VERSION ""

NS_ :

BS_:

BU_: WPC2 RLPSU DPSU PSB SHVU_RR APSU FCS EMCU SLB RCM ARS CGW_CCU ATS RLHV SGU PFSU ALBCU DSAU SWRC SHVU_FR RCS RRPSU BLTN_CAM SCM DLBCU OHCL RWPC RRHV WPC HOD ASAU

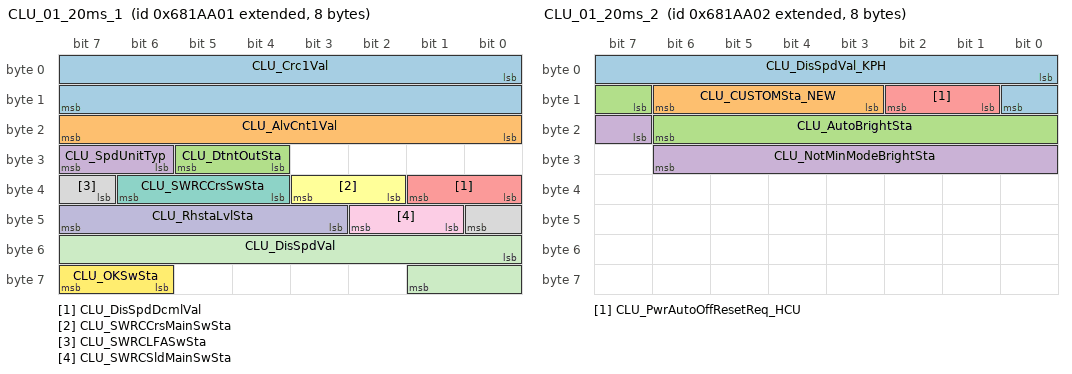
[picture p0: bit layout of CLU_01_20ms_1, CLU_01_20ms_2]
BO_ 2256644609 CLU_01_20ms_1: 8 CGW_CCU
 SG_ CLU_Crc1Val : 0|16@1+ (1,0) [0|0] ""  SHVU_RR,DPSU,ATS
 SG_ CLU_AlvCnt1Val : 16|8@1+ (1,0) [0|0] ""  SHVU_RR,DPSU,ATS,EMCU
 SG_ CLU_DtntOutSta : 28|2@1+ (1,0) [0|0] ""  FCS,WPC,RWPC,ARS,SWRC,APSU,RLHV,RRHV,SHVU_FR,SHVU_RR,DPSU,RCS,RRPSU,RLPSU,ATS,DSAU,ASAU,OHCL,WPC2
 SG_ CLU_SpdUnitTyp : 30|2@1+ (1,0) [0|0] ""  DPSU,BLTN_CAM,EMCU,WPC2
 SG_ CLU_DisSpdDcmlVal : 32|2@1+ (0.125,0) [0|0] ""  Vector__XXX
 SG_ CLU_SWRCCrsMainSwSta : 34|2@1+ (1,0) [0|0] ""  Vector__XXX
 SG_ CLU_SWRCCrsSwSta : 36|3@1+ (1,0) [0|0] ""  Vector__XXX
 SG_ CLU_SWRCLFASwSta : 39|2@1+ (1,0) [0|0] ""  Vector__XXX
 SG_ CLU_SWRCSldMainSwSta : 41|2@1+ (1,0) [0|0] ""  Vector__XXX
 SG_ CLU_RhstaLvlSta : 43|5@1+ (1,0) [0|0] ""  FCS,WPC,RWPC,ARS,SWRC,APSU,RLHV,RRHV,SHVU_FR,SHVU_RR,DPSU,RCS,RRPSU,RLPSU,ATS,DSAU,ASAU,OHCL,WPC2
 SG_ CLU_DisSpdVal : 48|10@1+ (0.5,0) [0|0] "km/h or MPH"  APSU,DPSU,BLTN_CAM,EMCU,WPC2
 SG_ CLU_OKSwSta : 62|2@1+ (1,0) [0|0] ""  Vector__XXX

BO_ 2470763009 CLU_09_00ms_1: 8 CGW_CCU
 SG_ CLU_Crc9Val : 0|16@1+ (1,0) [0|0] ""  Vector__XXX
 SG_ CLU_AlvCnt9Val : 16|8@1+ (1,0) [0|0] ""  Vector__XXX
 SG_ USM_MdLmpClrSetReq : 24|4@1+ (1,0) [0|0] ""  Vector__XXX
 SG_ USM_RrWiperRevSetReq : 28|2@1+ (1,0) [0|0] ""  Vector__XXX
 SG_ USM_RrStRemindSetReq : 30|2@1+ (1,0) [0|0] ""  Vector__XXX
 SG_ USM_RrWpcSetReq : 32|2@1+ (1,0) [0|0] ""  Vector__XXX
 SG_ USM_WpcSetReq : 34|2@1+ (1,0) [0|0] ""  WPC,WPC2
 SG_ USM_SeqLmpSetReq : 36|2@1+ (1,0) [0|0] ""  Vector__XXX
 SG_ USM_UnlckWlcmSetReq : 38|2@1+ (1,0) [0|0] ""  Vector__XXX
 SG_ USM_SmrtWlcmSetReq : 40|2@1+ (1,0) [0|0] ""  Vector__XXX
 SG_ USM_UipSetReq : 42|2@1+ (1,0) [0|0] ""  Vector__XXX
 SG_ USM_DigitalKeyEnblSetReq : 44|2@1+ (1,0) [0|0] ""  Vector__XXX
 SG_ USM_OwnerPhnRegSetReq : 46|2@1+ (1,0) [0|0] ""  Vector__XXX
 SG_ USM_NFCCard1RegSetReq : 48|2@1+ (1,0) [0|0] ""  Vector__XXX
 SG_ USM_NFCCard2RegSetReq : 50|2@1+ (1,0) [0|0] ""  Vector__XXX
 SG_ USM_ProcStpReq : 52|1@1+ (1,0) [0|0] ""  Vector__XXX
 SG_ USM_PwrAutoOffTimeSetReq : 54|3@1+ (1,0) [0|0] ""  Vector__XXX
 SG_ USM_RrStRemindSetReq_RestMode : 57|3@1+ (1,0) [0|0] ""  Vector__XXX
 SG_ USM_1stRrStRemindSetReq : 60|2@1+ (1,0) [0|0] ""  Vector__XXX
 SG_ USM_Wpc2SetReq : 62|2@1+ (1,0) [0|0] ""  WPC2

BO_ 2256644610 CLU_01_20ms_2: 8 CGW_CCU
 SG_ CLU_DisSpdVal_KPH : 0|9@1+ (1,0) [0|0] "km/h"  WPC,RWPC,APSU,RLHV,RRHV,SHVU_FR,SHVU_RR,DPSU,DLBCU,PFSU,RRPSU,RLPSU,ATS,DSAU,ASAU,RCM,ALBCU,WPC2
 SG_ CLU_CUSTOMSta_NEW : 11|4@1+ (1,0) [0|0] ""  SWRC
 SG_ CLU_AutoBrightSta : 15|8@1+ (1,0) [0|0] ""  FCS,WPC,RWPC,SWRC,APSU,RLHV,RRHV,SHVU_FR,SHVU_RR,DPSU,RCS,ATS,DSAU,ASAU,OHCL,BLTN_CAM,WPC2
 SG_ CLU_NotMinModeBrightSta : 23|8@1+ (1,0) [0|0] ""  Vector__XXX
 SG_ CLU_PwrAutoOffResetReq_HCU : 9|2@1+ (1,0) [0|0] ""  Vector__XXX

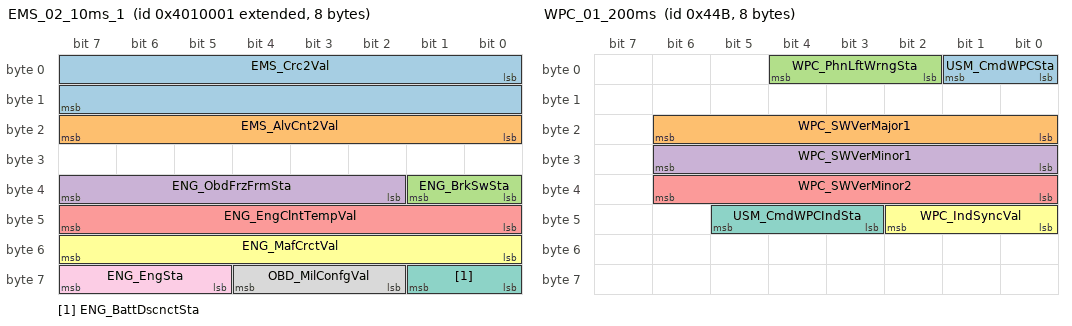
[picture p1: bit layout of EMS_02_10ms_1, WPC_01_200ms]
BO_ 2214658049 EMS_02_10ms_1: 8 CGW_CCU
 SG_ EMS_Crc2Val : 0|16@1+ (1,0) [0|0] ""  Vector__XXX
 SG_ EMS_AlvCnt2Val : 16|8@1+ (1,0) [0|0] ""  Vector__XXX
 SG_ ENG_BrkSwSta : 32|2@1+ (1,0) [0|0] ""  BLTN_CAM
 SG_ ENG_ObdFrzFrmSta : 34|6@1+ (1,0) [0|0] ""  Vector__XXX
 SG_ ENG_EngClntTempVal : 40|8@1+ (0.75,-48) [0|0] "℃"  Vector__XXX
 SG_ ENG_MafCrctVal : 48|8@1+ (0.00781,0) [0|0] ""  Vector__XXX
 SG_ ENG_BattDscnctSta : 56|2@1+ (1,0) [0|0] ""  Vector__XXX
 SG_ OBD_MilConfgVal : 58|3@1+ (1,0) [0|0] ""  Vector__XXX
 SG_ ENG_EngSta : 61|3@1+ (1,0) [0|0] ""  SCM,WPC,RWPC,SWRC,APSU,RLHV,RRHV,SHVU_FR,SHVU_RR,DPSU,DLBCU,PFSU,RRPSU,RLPSU,HOD,RCM,BLTN_CAM,EMCU,WPC2

BO_ 1099 WPC_01_200ms: 8 WPC
 SG_ USM_CmdWPCSta : 0|2@1+ (1,0) [0|0] ""  CGW_CCU
 SG_ WPC_SWVerMajor1 : 16|7@1+ (1,0) [0|0] ""  CGW_CCU
 SG_ WPC_PhnLftWrngSta : 2|3@1+ (1,0) [0|0] ""  CGW_CCU
 SG_ WPC_SWVerMinor1 : 24|7@1+ (1,0) [0|0] ""  CGW_CCU
 SG_ WPC_SWVerMinor2 : 32|7@1+ (1,0) [0|0] ""  CGW_CCU
 SG_ WPC_IndSyncVal : 40|3@1+ (1,0) [0|0] ""  RWPC,WPC2
 SG_ USM_CmdWPCIndSta : 43|3@1+ (1,0) [0|0] ""  CGW_CCU

BO_ 1093 SMK_06_200ms: 8 CGW_CCU
 SG_ SMK_Crc6Val : 0|8@1+ (1,0) [0|0] ""  Vector__XXX
 SG_ SMK_AlvCnt6Val : 12|4@1+ (1,0) [0|0] ""  Vector__XXX
 SG_ Lamp_HzrdBlnkngSta : 16|3@1+ (1,0) [0|0] ""  Vector__XXX
 SG_ RSPA_LearntSta : 19|2@1+ (1,0) [0|0] ""  Vector__XXX
 SG_ Lamp_SmrtWlcmLtOnReq : 21|2@1+ (1,0) [0|0] ""  Vector__XXX
 SG_ Fob_BattStaInfo : 24|2@1+ (1,0) [0|0] ""  Vector__XXX
 SG_ Fob_FoundDrvWlcmArea : 26|2@1+ (1,0) [0|0] ""  Vector__XXX
 SG_ Fob_FoundAsstWlcmArea : 28|2@1+ (1,0) [0|0] ""  Vector__XXX
 SG_ Fob_FoundExtrnlArea : 30|2@1+ (1,0) [0|0] ""  Vector__XXX
 SG_ Fob_FoundIntArea : 32|2@1+ (1,0) [0|0] ""  Vector__XXX
 SG_ Fob_LearntSta : 34|2@1+ (1,0) [0|0] ""  Vector__XXX
 SG_ RSPA_RFSigErrSta : 36|2@1+ (1,0) [0|0] ""  Vector__XXX
 SG_ RSPA_CanErrSta : 38|2@1+ (1,0) [0|0] ""  Vector__XXX
 SG_ LFAnt_FltSta : 40|2@1+ (1,0) [0|0] ""  Vector__XXX
 SG_ LFAnt_SrchSta : 42|2@1+ (1,0) [0|0] ""  WPC,RWPC,WPC2
 SG_ RSPA_ModSta_SMK : 48|3@1+ (1,0) [0|0] ""  DPSU
 SG_ RSPA_FobBattSta : 51|3@1+ (1,0) [0|0] ""  Vector__XXX
 SG_ Fob_BtnReleasedSta : 54|2@1+ (1,0) [0|0] ""  Vector__XXX
 SG_ USM_SmrtTrnkTlgtModSta : 56|3@1+ (1,0) [0|0] ""  Vector__XXX
 SG_ USM_WALModSta : 59|3@1+ (1,0) [0|0] ""  Vector__XXX
 SG_ Fob_FoundWlcmArea : 62|2@1+ (1,0) [0|0] ""  Vector__XXX

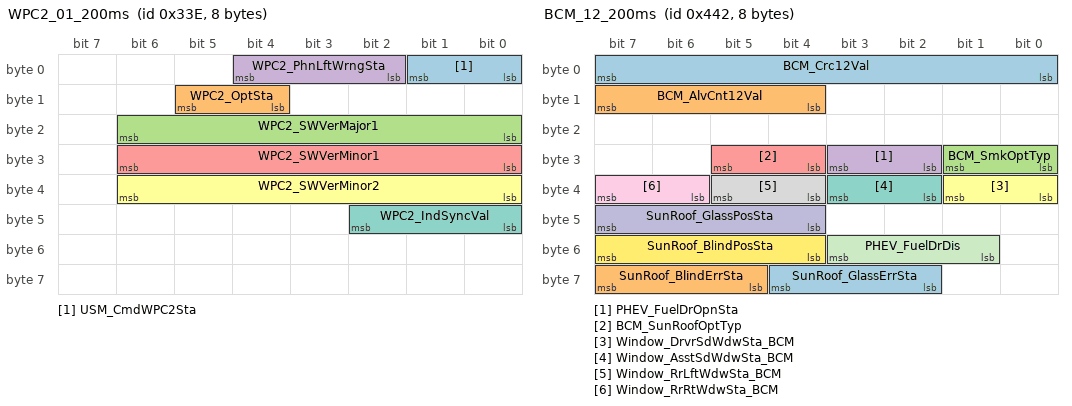
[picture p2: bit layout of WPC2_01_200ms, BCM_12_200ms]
BO_ 830 WPC2_01_200ms: 8 WPC2
 SG_ USM_CmdWPC2Sta : 0|2@1+ (1,0) [0|0] ""  CGW_CCU
 SG_ WPC2_OptSta : 12|2@1+ (1,0) [0|0] ""  CGW_CCU
 SG_ WPC2_SWVerMajor1 : 16|7@1+ (1,0) [0|0] ""  CGW_CCU
 SG_ WPC2_PhnLftWrngSta : 2|3@1+ (1,0) [0|0] ""  CGW_CCU
 SG_ WPC2_SWVerMinor1 : 24|7@1+ (1,0) [0|0] ""  CGW_CCU
 SG_ WPC2_SWVerMinor2 : 32|7@1+ (1,0) [0|0] ""  CGW_CCU
 SG_ WPC2_IndSyncVal : 40|3@1+ (1,0) [0|0] ""  RWPC,WPC

BO_ 2210462210 HCU_03_10ms_2: 8 CGW_CCU
 SG_ HCU_GreenZoneLmpDis : 0|2@1+ (1,0) [0|0] ""  Vector__XXX
 SG_ HCU_MILOnReq : 10|2@1+ (1,0) [0|0] ""  Vector__XXX
 SG_ HCU_PhevAutoModOnSta : 12|2@1+ (1,0) [0|0] "flag"  Vector__XXX
 SG_ HCU_SccDrvOvrdReq : 14|2@1+ (1,0) [0|0] ""  Vector__XXX
 SG_ HCU_SccEnblSta : 16|2@1+ (1,0) [0|0] ""  Vector__XXX
 SG_ HCU_SlwDnSta : 18|2@1+ (1,0) [0|0] ""  Vector__XXX
 SG_ HCU_HcuRdySta : 2|2@1+ (1,0) [0|0] ""  Vector__XXX
 SG_ HCU_SmrtEcoGdDis : 20|2@1+ (1,0) [0|0] ""  Vector__XXX
 SG_ HCU_SmrtEcoLvlDis : 22|7@1+ (1,0) [0|0] ""  Vector__XXX
 SG_ HCU_SmrtEcoRngDis : 29|7@1+ (1,0) [0|0] ""  Vector__XXX
 SG_ HCU_SpdLimDeviceActSta : 36|2@1+ (1,0) [0|0] ""  Vector__XXX
 SG_ HCU_SpdLimDeviceOperSta : 38|2@1+ (1,0) [0|0] ""  Vector__XXX
 SG_ HCU_HEVRdyDis : 4|2@1+ (1,0) [0|0] ""  Vector__XXX
 SG_ HCU_SpdLimDeviceVehSpdVal : 40|8@1+ (1,0) [0|0] ""  Vector__XXX
 SG_ HCU_SrvModSta : 48|2@1+ (1,0) [0|0] ""  Vector__XXX
 SG_ HCU_StrtInhbt2Sta : 50|2@1+ (1,0) [0|0] ""  Vector__XXX
 SG_ HCU_StrtInhbtSta : 52|2@1+ (1,0) [0|0] ""  Vector__XXX
 SG_ HCU_SysShtOffReq : 54|2@1+ (1,0) [0|0] ""  Vector__XXX
 SG_ HCU_VehStrtEnblSta : 56|2@1+ (1,0) [0|0] ""  Vector__XXX
 SG_ HCU_BrkLmpOnReq : 58|2@1+ (1,0) [0|0] ""  Vector__XXX
 SG_ HCU_HevRdySta : 6|2@1+ (1,0) [0|0] ""  SCM,WPC,RWPC,SWRC,APSU,RLHV,RRHV,SHVU_FR,SHVU_RR,DPSU,DLBCU,PFSU,RRPSU,RLPSU,HOD,RCM,BLTN_CAM,WPC2
 SG_ HCU_CcDrvAlrtDis : 60|2@1+ (1,0) [0|0] ""  Vector__XXX
 SG_ HCU_SldDrvAlrtDis : 62|2@1+ (1,0) [0|0] ""  Vector__XXX
 SG_ HCU_LimpOffSta : 8|2@1+ (1,0) [0|0] ""  Vector__XXX

BO_ 1090 BCM_12_200ms: 8 CGW_CCU
 SG_ BCM_Crc12Val : 0|8@1+ (1,0) [0|0] ""  Vector__XXX
 SG_ BCM_AlvCnt12Val : 12|4@1+ (1,0) [0|0] ""  Vector__XXX
 SG_ BCM_SmkOptTyp : 24|2@1+ (1,0) [0|0] ""  WPC,RWPC,WPC2
 SG_ PHEV_FuelDrOpnSta : 26|2@1+ (1,0) [0|0] ""  Vector__XXX
 SG_ BCM_SunRoofOptTyp : 28|2@1+ (1,0) [0|0] ""  ATS
 SG_ Window_DrvrSdWdwSta_BCM : 32|2@1+ (1,0) [0|0] ""  Vector__XXX
 SG_ Window_AsstSdWdwSta_BCM : 34|2@1+ (1,0) [0|0] ""  Vector__XXX
 SG_ Window_RrLftWdwSta_BCM : 36|2@1+ (1,0) [0|0] ""  ATS
 SG_ Window_RrRtWdwSta_BCM : 38|2@1+ (1,0) [0|0] ""  ATS
 SG_ SunRoof_GlassPosSta : 44|4@1+ (1,0) [0|0] ""  Vector__XXX
 SG_ PHEV_FuelDrDis : 49|3@1+ (1,0) [0|0] ""  Vector__XXX
 SG_ SunRoof_BlindPosSta : 52|4@1+ (1,0) [0|0] ""  Vector__XXX
 SG_ SunRoof_GlassErrSta : 58|3@1+ (1,0) [0|0] ""  Vector__XXX
 SG_ SunRoof_BlindErrSta : 61|3@1+ (1,0) [0|0] ""  Vector__XXX

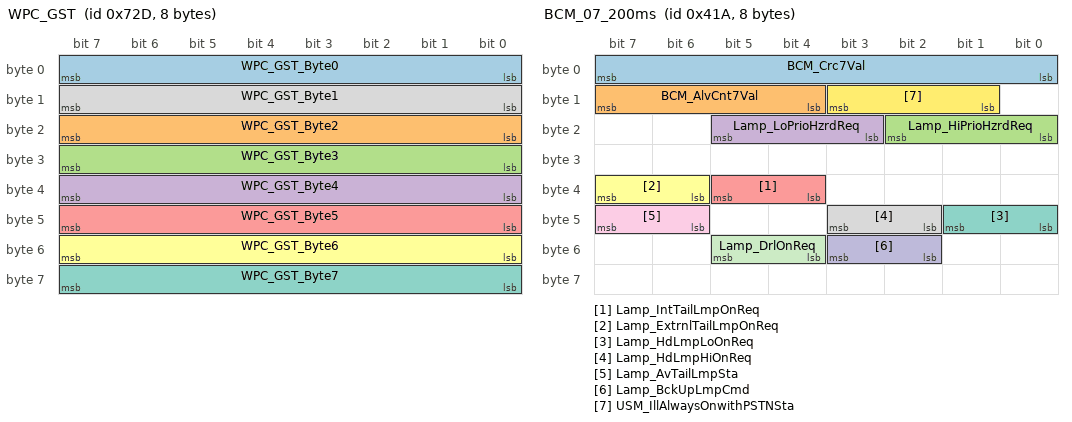
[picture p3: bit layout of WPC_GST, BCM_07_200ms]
BO_ 1837 WPC_GST: 8 WPC
 SG_ WPC_GST_Byte0 : 0|8@1+ (1,0) [0|0] ""  CGW_CCU
 SG_ WPC_GST_Byte2 : 16|8@1+ (1,0) [0|0] ""  CGW_CCU
 SG_ WPC_GST_Byte3 : 24|8@1+ (1,0) [0|0] ""  CGW_CCU
 SG_ WPC_GST_Byte4 : 32|8@1+ (1,0) [0|0] ""  CGW_CCU
 SG_ WPC_GST_Byte5 : 40|8@1+ (1,0) [0|0] ""  CGW_CCU
 SG_ WPC_GST_Byte6 : 48|8@1+ (1,0) [0|0] ""  CGW_CCU
 SG_ WPC_GST_Byte7 : 56|8@1+ (1,0) [0|0] ""  CGW_CCU
 SG_ WPC_GST_Byte1 : 8|8@1+ (1,0) [0|0] ""  CGW_CCU

BO_ 1050 BCM_07_200ms: 8 CGW_CCU
 SG_ BCM_Crc7Val : 0|8@1+ (1,0) [0|0] ""  Vector__XXX
 SG_ BCM_AlvCnt7Val : 12|4@1+ (1,0) [0|0] ""  Vector__XXX
 SG_ Lamp_HiPrioHzrdReq : 16|3@1+ (1,0) [0|0] ""  Vector__XXX
 SG_ Lamp_LoPrioHzrdReq : 19|3@1+ (1,0) [0|0] ""  Vector__XXX
 SG_ Lamp_IntTailLmpOnReq : 36|2@1+ (1,0) [0|0] ""  FCS,WPC,RWPC,APSU,RLHV,RRHV,SHVU_FR,SHVU_RR,DPSU,WPC2
 SG_ Lamp_ExtrnlTailLmpOnReq : 38|2@1+ (1,0) [0|0] ""  BLTN_CAM
 SG_ Lamp_HdLmpLoOnReq : 40|2@1+ (1,0) [0|0] ""  Vector__XXX
 SG_ Lamp_HdLmpHiOnReq : 42|2@1+ (1,0) [0|0] ""  Vector__XXX
 SG_ Lamp_AvTailLmpSta : 46|2@1+ (1,0) [0|0] ""  SWRC,APSU,ATS
 SG_ Lamp_BckUpLmpCmd : 50|2@1+ (1,0) [0|0] ""  Vector__XXX
 SG_ Lamp_DrlOnReq : 52|2@1+ (1,0) [0|0] ""  Vector__XXX
 SG_ USM_IllAlwaysOnwithPSTNSta : 9|3@1+ (1,0) [0|0] ""  Vector__XXX

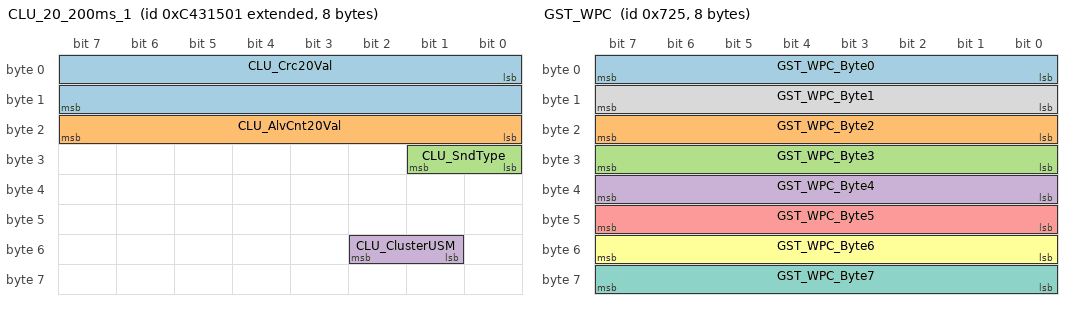
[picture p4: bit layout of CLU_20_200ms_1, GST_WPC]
BO_ 2353206529 CLU_20_200ms_1: 8 CGW_CCU
 SG_ CLU_Crc20Val : 0|16@1+ (1,0) [0|0] ""  Vector__XXX
 SG_ CLU_AlvCnt20Val : 16|8@1+ (1,0) [0|0] ""  Vector__XXX
 SG_ CLU_SndType : 24|2@1- (1,0) [0|0] ""  Vector__XXX
 SG_ CLU_ClusterUSM : 49|2@1+ (1,0) [0|0] ""  WPC,WPC2

BO_ 1041 ICU_02_200ms: 8 CGW_CCU
 SG_ ICU_Crc2Val : 0|8@1+ (1,0) [0|0] ""  Vector__XXX
 SG_ ICU_MtGearPosRSta : 10|2@1+ (1,0) [0|0] ""  BLTN_CAM
 SG_ ICU_AlvCnt2Val : 12|4@1+ (1,0) [0|0] ""  Vector__XXX
 SG_ Autocut_DlvryModSta : 20|2@1+ (1,0) [0|0] ""  Vector__XXX
 SG_ DoorLock_AsstDrUnLkSta : 22|2@1+ (1,0) [0|0] ""  Vector__XXX
 SG_ Warn_DrvDrSwSta : 24|2@1+ (1,0) [0|0] ""  WPC,RWPC,DPSU,BLTN_CAM,WPC2
 SG_ DoorLock_DrvKeyUnLkSwSta : 26|2@1+ (1,0) [0|0] ""  Vector__XXX
 SG_ DoorLock_RrLftDrUnLkSta : 28|2@1+ (1,0) [0|0] ""  Vector__XXX
 SG_ DoorLock_RrRtDrUnLkSta : 30|2@1+ (1,0) [0|0] ""  Vector__XXX
 SG_ Warn_AsstDrSwSta : 34|2@1+ (1,0) [0|0] ""  WPC,RWPC,APSU,RLPSU,BLTN_CAM,ALBCU,WPC2
 SG_ Warn_AsstStBltSwSta : 36|2@1+ (1,0) [0|0] ""  PSB,APSU,RLPSU,ASAU,ALBCU
 SG_ Warn_BrkFldSwSta : 38|2@1+ (1,0) [0|0] ""  Vector__XXX
 SG_ DoorLock_DrvKeyLkSwSta : 40|2@1+ (1,0) [0|0] ""  Vector__XXX
 SG_ Warn_DrvStBltSwSta : 42|2@1+ (1,0) [0|0] ""  PSB,DPSU,DLBCU,ATS,DSAU,ASAU
 SG_ Warn_HoodSwSta : 44|2@1+ (1,0) [0|0] ""  BLTN_CAM
 SG_ Warn_PassStOccSta : 46|2@1+ (1,0) [0|0] ""  APSU
 SG_ Warn_PrkngBrkSwSta : 48|2@1+ (1,0) [0|0] ""  APSU,RLHV,RRHV,PFSU,RRPSU,RLPSU
 SG_ Warn_RrCtrStBltSwSta : 50|2@1+ (1,0) [0|0] ""  PSB
 SG_ Warn_RrLftDrSwSta : 52|2@1+ (1,0) [0|0] ""  WPC,RWPC,APSU,RLHV,RRPSU,RLPSU,BLTN_CAM,WPC2
 SG_ Warn_RrLftStBltSwSta : 54|2@1+ (1,0) [0|0] ""  PSB,APSU,DPSU
 SG_ Warn_RrRtDrSwSta : 56|2@1+ (1,0) [0|0] ""  WPC,RWPC,APSU,RRHV,RRPSU,RLPSU,BLTN_CAM,WPC2
 SG_ Warn_RrRtStBltSwSta : 58|2@1+ (1,0) [0|0] ""  PSB,APSU,DPSU
 SG_ Warn_HoodSwMemorySta : 60|2@1+ (1,0) [0|0] ""  Vector__XXX
 SG_ Warn_WshrFldSwSta : 62|2@1+ (1,0) [0|0] ""  Vector__XXX
 SG_ ICU_Haptic_OPT : 8|2@1+ (1,0) [0|0] ""  Vector__XXX

BO_ 1829 GST_WPC: 8 CGW_CCU
 SG_ GST_WPC_Byte0 : 0|8@1+ (1,0) [0|0] ""  WPC
 SG_ GST_WPC_Byte2 : 16|8@1+ (1,0) [0|0] ""  WPC
 SG_ GST_WPC_Byte3 : 24|8@1+ (1,0) [0|0] ""  WPC
 SG_ GST_WPC_Byte4 : 32|8@1+ (1,0) [0|0] ""  WPC
 SG_ GST_WPC_Byte5 : 40|8@1+ (1,0) [0|0] ""  WPC
 SG_ GST_WPC_Byte6 : 48|8@1+ (1,0) [0|0] ""  WPC
 SG_ GST_WPC_Byte7 : 56|8@1+ (1,0) [0|0] ""  WPC
 SG_ GST_WPC_Byte1 : 8|8@1+ (1,0) [0|0] ""  WPC

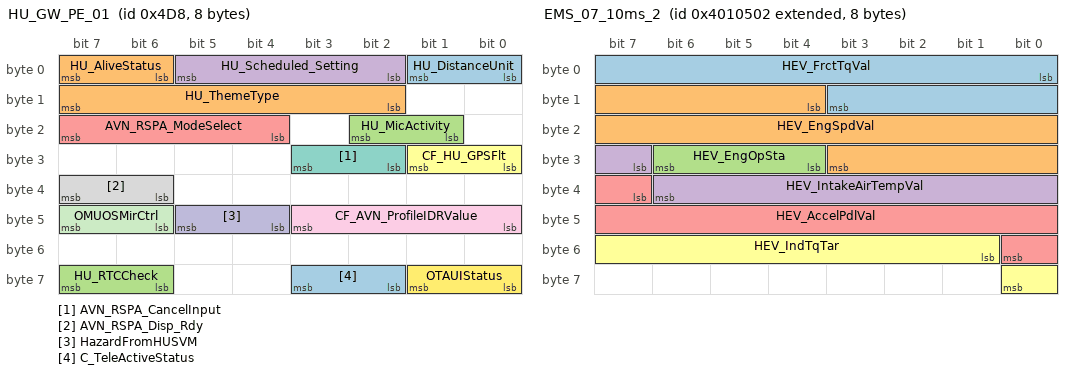
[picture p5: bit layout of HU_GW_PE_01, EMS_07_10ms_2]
BO_ 1240 HU_GW_PE_01: 8 CGW_CCU
 SG_ HU_DistanceUnit : 0|2@1+ (1,0) [0|0] ""  Vector__XXX
 SG_ HU_ThemeType : 10|6@1+ (1,0) [0|0] ""  ATS,BLTN_CAM
 SG_ HU_MicActivity : 17|2@1+ (1,0) [0|0] ""  Vector__XXX
 SG_ HU_Scheduled_Setting : 2|4@1+ (1,0) [0|0] ""  Vector__XXX
 SG_ AVN_RSPA_ModeSelect : 20|4@1+ (1,0) [0|0] ""  Vector__XXX
 SG_ CF_HU_GPSFlt : 24|2@1+ (1,0) [0|0] ""  Vector__XXX
 SG_ AVN_RSPA_CancelInput : 26|2@1+ (1,0) [0|3] ""  Vector__XXX
 SG_ AVN_RSPA_Disp_Rdy : 38|2@1+ (1,0) [0|0] ""  Vector__XXX
 SG_ CF_AVN_ProfileIDRValue : 40|4@1+ (1,0) [0|0] ""  WPC,RWPC,DPSU,DLBCU,RCM,BLTN_CAM,SGU,WPC2
 SG_ HazardFromHUSVM : 44|2@1+ (1,0) [0|0] ""  Vector__XXX
 SG_ OMUOSMirCtrl : 46|2@1+ (1,0) [0|0] ""  Vector__XXX
 SG_ OTAUIStatus : 56|2@1+ (1,0) [0|0] ""  Vector__XXX
 SG_ C_TeleActiveStatus : 58|2@1+ (1,0) [0|0] ""  Vector__XXX
 SG_ HU_AliveStatus : 6|2@1+ (1,0) [0|0] ""  Vector__XXX
 SG_ HU_RTCCheck : 62|2@1+ (1,0) [0|0] ""  APSU

BO_ 2214659330 EMS_07_10ms_2: 8 CGW_CCU
 SG_ HEV_FrctTqVal : 0|12@1+ (0.1,0) [0|0] "Nm"  Vector__XXX
 SG_ HEV_EngSpdVal : 12|16@1+ (0.25,0) [0|0] "rpm"  Vector__XXX
 SG_ HEV_EngOpSta : 28|3@1+ (1,0) [0|0] ""  WPC,RWPC,PFSU,WPC2
 SG_ HEV_IntakeAirTempVal : 31|8@1+ (0.75,-48) [0|0] "℃"  Vector__XXX
 SG_ HEV_AccelPdlVal : 39|10@1+ (0.09784,0) [0|0] "%"  BLTN_CAM
 SG_ HEV_IndTqTar : 49|8@1+ (0.3906,0) [0|0] "%"  Vector__XXX

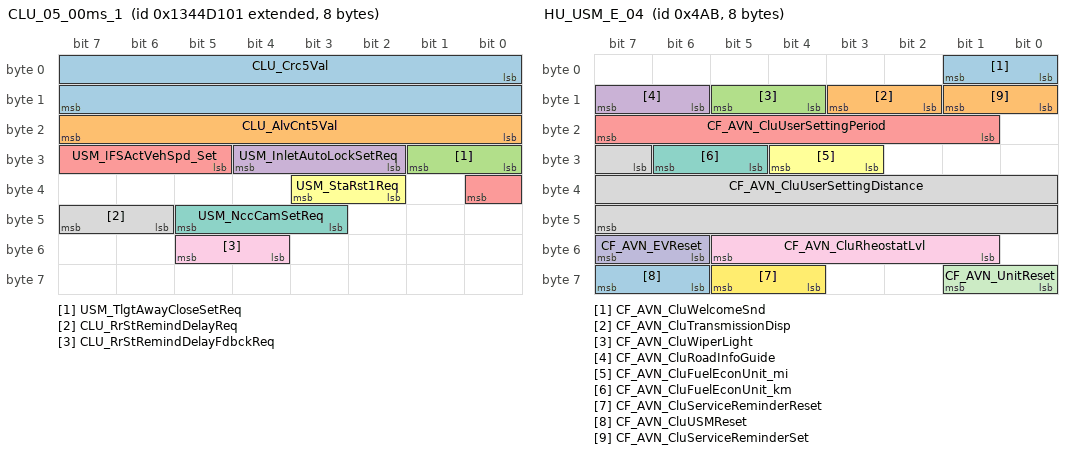
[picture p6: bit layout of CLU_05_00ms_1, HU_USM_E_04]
BO_ 2470760705 CLU_05_00ms_1: 8 CGW_CCU
 SG_ CLU_Crc5Val : 0|16@1+ (1,0) [0|0] ""  Vector__XXX
 SG_ CLU_AlvCnt5Val : 16|8@1+ (1,0) [0|0] ""  Vector__XXX
 SG_ USM_TlgtAwayCloseSetReq : 24|2@1+ (1,0) [0|0] ""  Vector__XXX
 SG_ USM_InletAutoLockSetReq : 26|3@1+ (1,0) [0|0] ""  Vector__XXX
 SG_ USM_IFSActVehSpd_Set : 29|4@1+ (1,0) [0|0] ""  Vector__XXX
 SG_ USM_StaRst1Req : 34|2@1+ (1,0) [0|0] ""  WPC,DPSU,WPC2
 SG_ USM_NccCamSetReq : 43|3@1+ (1,0) [0|0] ""  Vector__XXX
 SG_ CLU_RrStRemindDelayReq : 46|2@1+ (1,0) [0|0] ""  Vector__XXX
 SG_ CLU_RrStRemindDelayFdbckReq : 52|2@1+ (1,0) [0|0] ""  Vector__XXX

BO_ 1195 HU_USM_E_04: 8 CGW_CCU
 SG_ CF_AVN_CluWelcomeSnd : 0|2@1+ (1,0) [0|0] ""  Vector__XXX
 SG_ CF_AVN_CluTransmissionDisp : 10|2@1+ (1,0) [0|0] ""  Vector__XXX
 SG_ CF_AVN_CluWiperLight : 12|2@1+ (1,0) [0|0] ""  Vector__XXX
 SG_ CF_AVN_CluRoadInfoGuide : 14|2@1+ (1,0) [0|0] ""  Vector__XXX
 SG_ CF_AVN_CluUserSettingPeriod : 17|7@1+ (1,0) [0|0] ""  Vector__XXX
 SG_ CF_AVN_CluFuelEconUnit_mi : 27|2@1+ (1,0) [0|0] ""  Vector__XXX
 SG_ CF_AVN_CluFuelEconUnit_km : 29|2@1+ (1,0) [0|0] ""  Vector__XXX
 SG_ CF_AVN_CluUserSettingDistance : 31|17@1+ (1,0) [0|0] ""  Vector__XXX
 SG_ CF_AVN_CluRheostatLvl : 49|5@1+ (1,0) [0|0] ""  Vector__XXX
 SG_ CF_AVN_EVReset : 54|2@1+ (1,0) [0|0] ""  Vector__XXX
 SG_ CF_AVN_UnitReset : 56|2@1+ (1,0) [0|0] ""  Vector__XXX
 SG_ CF_AVN_CluServiceReminderReset : 60|2@1+ (1,0) [0|0] ""  Vector__XXX
 SG_ CF_AVN_CluUSMReset : 62|2@1+ (1,0) [0|0] ""  WPC,RWPC,SLB,ARS,APSU,RLHV,RRHV,SHVU_FR,SHVU_RR,DPSU,DLBCU,PFSU,RRPSU,RLPSU,ATS,DSAU,ASAU,RCM,BLTN_CAM,SGU,ALBCU,WPC2
 SG_ CF_AVN_CluServiceReminderSet : 8|2@1+ (1,0) [0|0] ""  Vector__XXX

CM_ BO_ 1050 "[PE] Periodic and On Event";
CM_ SG_ 1050 BCM_Crc7Val "BCM_CyclicRedundancyCheck7Value";
CM_ SG_ 1050 BCM_AlvCnt7Val "BCM_AliveCounter7Value";
CM_ SG_ 1050 Lamp_HiPrioHzrdReq "Lamp_HighPriorityHazardRequest ##2G##BCM - BCMmsg19 - C_HazardFromBCMHigh";
CM_ SG_ 1050 Lamp_LoPrioHzrdReq "Lamp_LowPriorityHazardStatus ##2G##BCM - BCMmsg19 - C_HazardfromBCMLow";
CM_ SG_ 1050 Lamp_IntTailLmpOnReq "Lamp_InternalTailLampOnRequest ##2G##BCM - BCMmsg19 - C_IntTailOn";
CM_ SG_ 1050 Lamp_ExtrnlTailLmpOnReq "Lamp_ExternalTailLampOnRequest ##2G##BCM - BCMmsg19 - C_ExtTailOn";
CM_ SG_ 1050 Lamp_HdLmpLoOnReq "Lamp_HeadLampLowOnRequest ##2G##BCM - BCMmsg19 - C_HLpLowOn";
CM_ SG_ 1050 Lamp_HdLmpHiOnReq "Lamp_HeadLampHighOnRequest ##2G##BCM - BCMmsg19 - C_HLpHighOn";
CM_ SG_ 1050 Lamp_AvTailLmpSta "Lamp_AvTailLampStatus ##2G##BCM - BCMmsg18 - C_AvTail";
CM_ BO_ 1090 "[PE] Periodic and On Event";
CM_ SG_ 1090 BCM_Crc12Val "BCM_CyclicRedundancyCheck12Value";
CM_ SG_ 1090 BCM_AlvCnt12Val "BCM_AliveCounter12Value";
CM_ SG_ 1090 BCM_SmkOptTyp "BCM_SmkOptionType ##2G##BCM - BCMmsg17 - C_SMKOption";
CM_ SG_ 1090 PHEV_FuelDrOpnSta "PHEV_FuelDoorOpenStatus ##2G##BCM - BCMmsg20 - C_FuelDrSw";
CM_ SG_ 1090 BCM_SunRoofOptTyp "BCM_SunRoofOptionType";
CM_ SG_ 1090 Window_DrvrSdWdwSta_BCM "Window_DriverSideWindowStatus ##2G##BCM - BCMmsg22 - C_DrvWindowOpenState";
CM_ SG_ 1090 Window_AsstSdWdwSta_BCM "Window_AssistantSideWindowStatus ##2G##BCM - BCMmsg22 - C_AstWindowOpenState";
CM_ SG_ 1090 Window_RrLftWdwSta_BCM "Window_RearLeftWindowStatus ##2G##BCM - BCMmsg22 - C_RLWindowOpenState";
CM_ SG_ 1090 Window_RrRtWdwSta_BCM "Window_RearRightPowerWindowStatus ##2G##BCM - BCMmsg22 - C_RRWindowOpenState";
CM_ SG_ 1090 SunRoof_GlassPosSta "SunRoof_GlassPositionStatus";
CM_ SG_ 1090 PHEV_FuelDrDis "PHEV_FuelDoorDisplay ##2G##BCM - BCMmsg19 - C_PHEVFuelDrDisp";
CM_ SG_ 1090 SunRoof_BlindPosSta "SunRoof_BlindPositionStatus";
CM_ SG_ 1090 SunRoof_GlassErrSta "SunRoof_GlassErrorStatus";
CM_ SG_ 1090 SunRoof_BlindErrSta "SunRoof_BlindErrorStatus";
CM_ BO_ 2256644609 "[P] Periodic";
CM_ SG_ 2256644609 CLU_Crc1Val "CLU_CyclicRedundancyCheck1Value";
CM_ SG_ 2256644609 CLU_AlvCnt1Val "CLU_AliveCounter1Value";
CM_ SG_ 2256644609 CLU_DtntOutSta "CLU_DetentOutStatus";
CM_ SG_ 2256644609 CLU_SpdUnitTyp "CLU_SpeedUnitType";
CM_ SG_ 2256644609 CLU_DisSpdDcmlVal "CLU_DisplaySpeedDecimalValue";
CM_ SG_ 2256644609 CLU_SWRCCrsMainSwSta "CLU_SWRCCrsMainSwSta";
CM_ SG_ 2256644609 CLU_SWRCCrsSwSta "CLU_SWRCCrsSwSta";
CM_ SG_ 2256644609 CLU_SWRCLFASwSta "SWRC_LFASwitchStatus";
CM_ SG_ 2256644609 CLU_SWRCSldMainSwSta "SWRC_SpeedLimiterMainSwitchStatus";
CM_ SG_ 2256644609 CLU_RhstaLvlSta "CLU_RheostatLevelStatus";
CM_ SG_ 2256644609 CLU_DisSpdVal "CLU_DisplaySpeedValue";
CM_ SG_ 2256644609 CLU_OKSwSta "OK Switch On/Off State";
CM_ BO_ 2256644610 "[P] Periodic";
CM_ SG_ 2256644610 CLU_DisSpdVal_KPH "CLU_DisplaySpeedValue_KPH";
CM_ SG_ 2256644610 CLU_AutoBrightSta "CLU_AutoBrightStatus";
CM_ SG_ 2256644610 CLU_NotMinModeBrightSta "CLU_NotMinimumModeBrightStaus";
CM_ SG_ 2256644610 CLU_PwrAutoOffResetReq_HCU "reset power auto off time";
CM_ BO_ 2470760705 "[EC] On Event and On Change";
CM_ SG_ 2470760705 CLU_Crc5Val "CLU_CyclicRedundancyCheck5Value";
CM_ SG_ 2470760705 CLU_AlvCnt5Val "CLU_AliveCounter5Value";
CM_ SG_ 2470760705 USM_TlgtAwayCloseSetReq "USM for Tailgate Away Close system";
CM_ SG_ 2470760705 USM_InletAutoLockSetReq "2nd General Signal: CLU22/CF_Clu_InletAutoLockNValueSet";
CM_ SG_ 2470760705 USM_IFSActVehSpd_Set "IFS 진입 속도 설정 메뉴";
CM_ SG_ 2470760705 USM_StaRst1Req "USM_StatusReset1Request";
CM_ SG_ 2470760705 USM_NccCamSetReq "USM_NccCameraSetRequest";
CM_ SG_ 2470760705 CLU_RrStRemindDelayReq "This singal is the delay request for ROA";
CM_ SG_ 2470760705 CLU_RrStRemindDelayFdbckReq "user input feedback for Rear Seat Reminder";
CM_ BO_ 2470763009 "[EC] On Event and On Change";
CM_ SG_ 2470763009 CLU_Crc9Val "CLU_CyclicRedundancyCheck9Value";
CM_ SG_ 2470763009 CLU_AlvCnt9Val "CLU_AliveCounter9Value";
CM_ SG_ 2470763009 USM_MdLmpClrSetReq "USM_MoodLampColorSetRequest";
CM_ SG_ 2470763009 USM_RrWiperRevSetReq "USM_RearWiperReverseSetRequest";
CM_ SG_ 2470763009 USM_RrStRemindSetReq "USM_RrseatReminderSetRequest(2nd :General: CLU20/CF_Clu_RrSeatRemindNValueSet)";
CM_ SG_ 2470763009 USM_RrWpcSetReq "USM_RearWpcSetRequest";
CM_ SG_ 2470763009 USM_WpcSetReq "USM_WpcSetRequest";
CM_ SG_ 2470763009 USM_SeqLmpSetReq "USM_SequencialLampSetRequest";
CM_ SG_ 2470763009 USM_UnlckWlcmSetReq "USM_UnlockWelcomeSetRequest";
CM_ SG_ 2470763009 USM_SmrtWlcmSetReq "USM_SmartWelcomeSetRequest";
CM_ SG_ 2470763009 USM_UipSetReq "2nd General: CF_Clu_UIPNValueSet";
CM_ SG_ 2470763009 USM_DigitalKeyEnblSetReq "Request to set the Digital Key ON or OFF(2nd General DB: CF_Clu_DigitalKeyNValueSet)";
CM_ SG_ 2470763009 USM_OwnerPhnRegSetReq "2nd general DB: CF_Clu_OwnerPhoneNValueSet";
CM_ SG_ 2470763009 USM_NFCCard1RegSetReq "2nd General DB:CF_Clu_NFCCard1NValueSet";
CM_ SG_ 2470763009 USM_NFCCard2RegSetReq "2nd General DB:CF_Clu_NFCCard2NValueSet";
CM_ SG_ 2470763009 USM_ProcStpReq "2nd General DB:CF_Clu_ProcessStopReq";
CM_ SG_ 2470763009 USM_PwrAutoOffTimeSetReq "USM_PowerAutoofftimeSetRequest";
CM_ SG_ 2470763009 USM_RrStRemindSetReq_RestMode "Request to set  Restmod of Rear Seat remind";
CM_ SG_ 2470763009 USM_1stRrStRemindSetReq "USM_RrseatReminderSetRequest(2nd :General: CLU21/CF_Clu_1stRrSeatRemindNValueSet)";
CM_ SG_ 2470763009 USM_Wpc2SetReq "USM_Wpc2SetRequest";
CM_ BO_ 2353206529 "[P] Periodic";
CM_ SG_ 2353206529 CLU_Crc20Val "CLU_CyclicRedundancyCheck20Value";
CM_ SG_ 2353206529 CLU_AlvCnt20Val "CLU_AliveCounter20Value";
CM_ SG_ 2353206529 CLU_SndType "CLU_SoundType";
CM_ BO_ 2214658049 "[P] Periodic";
CM_ SG_ 2214658049 EMS_Crc2Val "EMS_CyclicRedundancyCheck2Value";
CM_ SG_ 2214658049 EMS_AlvCnt2Val "EMS_AliveCounter2Value";
CM_ SG_ 2214658049 ENG_BrkSwSta "ENG_BrakeSwitchStatus ##2G##EMS - EMS12 - BRAKE_ACT";
CM_ SG_ 2214658049 ENG_ObdFrzFrmSta "ENG_ObdFreezeFrameStatus ##2G##EMS - EMS12 - OBD_FRF_ACK";
CM_ SG_ 2214658049 ENG_EngClntTempVal "ENG_EngineCoolantTemperatureValue ##2G##EMS - EMS12 - TEMP_ENG";
CM_ SG_ 2214658049 ENG_MafCrctVal "ENG_MassAirFlowCorrectionValue ##2G##EMS - EMS12 - MAF_FAC_ALTI_MMV";
CM_ SG_ 2214658049 ENG_BattDscnctSta "ENG_BatteryDisconnectStatus ##2G##EMS - EMS12 - VB_OFF_ACT";
CM_ SG_ 2214658049 OBD_MilConfgVal "OBD_MalfunctionIndicationLampConfigurationValue ##2G##EMS - EMS12 - CONF_MIL_FMY";
CM_ SG_ 2214658049 ENG_EngSta "ENG_EngineStatus ##2G##EMS - EMS16 - ENG_STAT";
CM_ BO_ 2214659330 "[P] Periodic";
CM_ SG_ 2214659330 HEV_FrctTqVal "HEV_FrictionTorqueValue";
CM_ SG_ 2214659330 HEV_EngSpdVal "HEV_EngineSpeedValue";
CM_ SG_ 2214659330 HEV_EngOpSta "HEV_EngineOperatingStatus";
CM_ SG_ 2214659330 HEV_IntakeAirTempVal "HEV_IntakeAirTemperatureValue";
CM_ SG_ 2214659330 HEV_AccelPdlVal "HEV_AcceleratorPedalValue";
CM_ SG_ 2214659330 HEV_IndTqTar "HEV_IndicatedTorqueTarget";
CM_ BO_ 1829 "[TP] Transport Protocol";
CM_ BO_ 2210462210 "[P] Periodic";
CM_ SG_ 2210462210 HCU_GreenZoneLmpDis "Indicate Green Zone Area ##2G##HCU - HCU4 - CF_Hcu_GreenZoneLamp";
CM_ SG_ 2210462210 HCU_MILOnReq "HCU_MalfunctionIndicatorLampOnRequest ##2G##HCU - HCU1 - CF_Hcu_MILReq";
CM_ SG_ 2210462210 HCU_PhevAutoModOnSta "HCU_PhevAutoModeOnStatus ##2G##HCU - HCU4 - CF_Hcu_AutoCdCs";
CM_ SG_ 2210462210 HCU_SccDrvOvrdReq "HCU_SccDriverOverrideRequest ##2G##HCU - HCU2 - CF_Hcu_Ovrride";
CM_ SG_ 2210462210 HCU_SccEnblSta "HCU_SmartCruiseControlEnableStatus ##2G##HCU - HCU2 - CF_Hcu_SccEna";
CM_ SG_ 2210462210 HCU_SlwDnSta "HCU_SlowDownStatus ##2G##HCU - HCU1 - CF_Hcu_SlwDwnStat";
CM_ SG_ 2210462210 HCU_HcuRdySta "HCU_HybridControlUnitReadyStatus ##2G##HCU - HCU1 - CF_Hcu_Rdy";
CM_ SG_ 2210462210 HCU_SmrtEcoGdDis "HCU_SmartEcoGuideDisplay ##2G##HCU - HCU4 - CF_Hcu_SmartEcoDisp";
CM_ SG_ 2210462210 HCU_SmrtEcoLvlDis "HCU_SmartEcoLevelDisplay ##2G##HCU - HCU4 - CR_Hcu_SmartEcoLvl";
CM_ SG_ 2210462210 HCU_SmrtEcoRngDis "HCU_SmartEcoRangeDisplay ##2G##HCU - HCU4 - CR_Hcu_SmartEcoRng";
CM_ SG_ 2210462210 HCU_SpdLimDeviceActSta "HCU_SpeedLimiterDeviceActivationStatus ##2G##HCU - HCU4 - CF_Vcu_SldAct";
CM_ SG_ 2210462210 HCU_SpdLimDeviceOperSta "HCU_SpeedLimiterDeviceOperationStatus ##2G##HCU - HCU4 - CF_Hcu_SldOpr";
CM_ SG_ 2210462210 HCU_HEVRdyDis "HCU_HybridVehicleReadyDisplay ##2G##HCU - HCU1 - CF_Hcu_HevRdyClu";
CM_ SG_ 2210462210 HCU_SpdLimDeviceVehSpdVal "HCU_SpeedLimiterDeviceVehicleSpeedValue ##2G##HCU - HCU4 - CR_Vcu_SldVs";
CM_ SG_ 2210462210 HCU_SrvModSta "HCU_ServiceModeStatus ##2G##HCU - HCU2 - CF_Hcu_ServiceMod";
CM_ SG_ 2210462210 HCU_StrtInhbt2Sta "HCU_StartInhibit2Status ##2G##HCU - HCU3 - CF_Hcu_StartInh";
CM_ SG_ 2210462210 HCU_StrtInhbtSta "HCU_StartInhibitStatus ##2G##HCU - HCU1 - CF_Hcu_StInhStat";
CM_ SG_ 2210462210 HCU_SysShtOffReq "HCU_SystemShutOffRequest ##2G##HCU - HCU1 - CF_Hcu_SysShutOffReq";
CM_ SG_ 2210462210 HCU_VehStrtEnblSta "HCU_VehicleStartEnableStatus ##2G##HCU - HCU1 - CF_Hcu_Veh_ST";
CM_ SG_ 2210462210 HCU_BrkLmpOnReq "HCU_BrakeLampOnRequest###2G####HCU - HCU5 - CF_Hcu_BrkLpReq";
CM_ SG_ 2210462210 HCU_HevRdySta "HCU_HybridVehicleReadyStatus ##2G##HCU - HCU1 - CF_Hcu_HevRdy";
CM_ SG_ 2210462210 HCU_CcDrvAlrtDis "Driver display information of CC can not be engaged";
CM_ SG_ 2210462210 HCU_SldDrvAlrtDis "SLD must be disengaged by system or cannot be engaged";
CM_ SG_ 2210462210 HCU_LimpOffSta "HCU_LimpOffStatus ##2G##HCU - HCU22 - CF_Hcu_LimpOff";
CM_ BO_ 1240 "[PE] Periodic and On Event";
CM_ SG_ 1240 HU_DistanceUnit "Request to set CLU Distance Unit";
CM_ SG_ 1240 HU_MicActivity "HU send this signal to eCall for MIC using status.
eCall unit stop the diagonosis when received 0x1:Activated from HU
Otherwise, eCall unit keep diagnosis every 1 sec. and HU can not use MIC";
CM_ SG_ 1240 CF_HU_GPSFlt "Information of GPS Fault 

0x0: Normal
0x1 : Fault operation
0x2 : Reserved
0x3:Invalid";
CM_ SG_ 1240 AVN_RSPA_CancelInput "Request Signal to cancel RSPA function";
CM_ SG_ 1240 AVN_RSPA_Disp_Rdy "Signal to inform RSPA of AVN's display ready status
(RSPA 화면 표시 가능/불가능 상태를 알리기 위한 신호)";
CM_ SG_ 1240 CF_AVN_ProfileIDRValue "This signal is User ID value in H/Unit.";
CM_ SG_ 1240 HazardFromHUSVM "This signal is for Hazard control";
CM_ SG_ 1240 OMUOSMirCtrl "This signal is for the OutSide Mirror Control (Fold or Unfold)";
CM_ SG_ 1240 OTAUIStatus "Information of the status of Head Unit";
CM_ SG_ 1240 C_TeleActiveStatus "This signal is for check TMS active status";
CM_ SG_ 1240 HU_AliveStatus "Information of the status of Head Unit
0x00 : Headunit is booting so, Headunit cant display any state
0x01 : Headunit is normal state, Headunit could display according to MM CAN  command.
0x02 : Headunit is doing their internal process, so Headunit cant communicate with other node.
For CLU/SCC/eCall
-AVN System transmission signal";
CM_ SG_ 1240 HU_RTCCheck "Checking whether RTC of AVN and HCU is operationg normally.";
CM_ BO_ 1195 "[EC] On Event and On Change";
CM_ SG_ 1195 CF_AVN_CluWelcomeSnd "Request to set CLU welcome soun";
CM_ SG_ 1195 CF_AVN_CluTransmissionDisp "Request to set CLU transmission display";
CM_ SG_ 1195 CF_AVN_CluWiperLight "Request to set CLU wiper & light mode";
CM_ SG_ 1195 CF_AVN_CluRoadInfoGuide "Request to set CLU road info guidance";
CM_ SG_ 1195 CF_AVN_CluUserSettingPeriod "Request to set CLU sservice period set by user";
CM_ SG_ 1195 CF_AVN_CluFuelEconUnit_mi "Cluster setting status for cluster Fuel Economy Unit (mile)";
CM_ SG_ 1195 CF_AVN_CluFuelEconUnit_km "Cluster setting status for cluster Fuel Economy unit (km)";
CM_ SG_ 1195 CF_AVN_CluUserSettingDistance "Request to set CLU service distance set by user";
CM_ SG_ 1195 CF_AVN_CluRheostatLvl "Request to set CLU rheostat level";
CM_ SG_ 1195 CF_AVN_EVReset "Request to reset EV Service (0x1 : EV USM Reset)";
CM_ SG_ 1195 CF_AVN_UnitReset "Request to reset Unit setting";
CM_ SG_ 1195 CF_AVN_CluServiceReminderReset "Request to reset CLU service reminder";
CM_ SG_ 1195 CF_AVN_CluUSMReset "Request to reset all USM service";
CM_ SG_ 1195 CF_AVN_CluServiceReminderSet "Request to set CLU service notification";
CM_ BO_ 1041 "[PE] Periodic and On Event";
CM_ SG_ 1041 ICU_Crc2Val "ICU_CyclicRedundancyCheck2Value";
CM_ SG_ 1041 ICU_MtGearPosRSta "##2G## -  - C_InhibitRMT,CF_Gway_InhibitRMT";
CM_ SG_ 1041 ICU_AlvCnt2Val "ICU_AliveCounter2Value";
CM_ SG_ 1041 Autocut_DlvryModSta "Autocut_DeliveryModeStatus ##2G## -  - C_SJBDeliveryMode,CF_Gway_SJBDeliveryMode";
CM_ SG_ 1041 DoorLock_AsstDrUnLkSta "DoorLock_AssistDoorUnLockStatus ##2G## -  - C_AstUnlockState,DoorLock_AsstDrUnLkSta";
CM_ SG_ 1041 Warn_DrvDrSwSta "DoorLock_DriverDoorSwitchStatus ##2G## -  - C_DrvDrSw,CF_Gway_DrvDrSw,Warn_DrvDrSwSta";
CM_ SG_ 1041 DoorLock_DrvKeyUnLkSwSta "DoorLock_DriverKeyUnLockSwitchStatus ##2G## -  - C_DrvKeyUnlockSw";
CM_ SG_ 1041 DoorLock_RrLftDrUnLkSta "DoorLock_RearLeftDoorUnLockStatus ##2G## -  - C_RLUnlockState,DoorLock_RrLftDrUnLkSta";
CM_ SG_ 1041 DoorLock_RrRtDrUnLkSta "DoorLock_RearRightDoorUnLockStatus ##2G## -  - C_RRUnlockState,DoorLock_RrRtDrUnLkSta";
CM_ SG_ 1041 Warn_AsstDrSwSta "Warn_AssistDoorSwitchStatus ##2G## -  - C_AstDrSw,CF_Gway_AstDrSw,Warn_AsstDrSwSta";
CM_ SG_ 1041 Warn_AsstStBltSwSta "Warn_AssistSeatBeltSwitchStatus ##2G## -  - C_AstSeatBeltSw,CF_Gway_AstSeatBeltSw";
CM_ SG_ 1041 Warn_BrkFldSwSta "Warn_BrakeFluidSwitchStatus ##2G## -  - C_BrakeFluidSw,CF_Gway_BrakeFluidSw";
CM_ SG_ 1041 DoorLock_DrvKeyLkSwSta "DoorLock_DriverKeyLockSwitchStatus ##2G## -  - C_DrvKeyLockSw";
CM_ SG_ 1041 Warn_DrvStBltSwSta "Warn_DriverSeatbeltSwitchStatus ##2G## -  - C_DrvSeatBeltSw,CF_Gway_DrvSeatBeltSw";
CM_ SG_ 1041 Warn_HoodSwSta "Warn_HoodSwitchStatus ##2G## -  - C_HoodSw,CF_Gway_HoodSw";
CM_ SG_ 1041 Warn_PassStOccSta "Warn_PassengerSeatOccupyStatus ##2G## -  - C_SBRMatSw";
CM_ SG_ 1041 Warn_PrkngBrkSwSta "Warn_ParkingBrakeSwitchStatus ##2G## -  - C_ParkBrakeSw";
CM_ SG_ 1041 Warn_RrCtrStBltSwSta "Warn_RearCenterSeatBeltSwitchStatus ##2G## -  - C_RCSeatBeltSw";
CM_ SG_ 1041 Warn_RrLftDrSwSta "Warn_RearLeftDoorSwitchStatus ##2G## -  - C_RLDrSw,CF_Gway_RLDrSw,Warn_RrLftDrSwSta";
CM_ SG_ 1041 Warn_RrLftStBltSwSta "Warn_RearLeftSeatBeltSwitchStatus ##2G## -  - C_RLSeatBeltSw";
CM_ SG_ 1041 Warn_RrRtDrSwSta "Warn_RearRightDoorSwitchStatus ##2G## -  - C_RRDrSw,CF_Gway_RRDrSw,Warn_RrRtDrSwSta";
CM_ SG_ 1041 Warn_RrRtStBltSwSta "Warn_RearRightSeatBeltSwitchStatus ##2G## -  - C_RRSeatBeltSw";
CM_ SG_ 1041 Warn_HoodSwMemorySta "Warn_HoodSwitchMemoryStatus ##2G## -  - CF_Hoodsw_memory,C_HoodSwMemory";
CM_ SG_ 1041 Warn_WshrFldSwSta "Washer Fluid Switch Signal ##2G## -  - CF_Gway_WasherFluidSw";
CM_ SG_ 1041 ICU_Haptic_OPT "Steering Wheel Haptic Warning Option Infomation ##2G## -  - C_ICU_Haptic_OPT";
CM_ BO_ 1093 "[PE] Periodic and On Event";
CM_ SG_ 1093 SMK_Crc6Val "SMK_CyclicRedundancyCheck6Value";
CM_ SG_ 1093 SMK_AlvCnt6Val "SMK_AliveCounter6Value";
CM_ SG_ 1093 Lamp_HzrdBlnkngSta "Lamp_HazardBlinkingStatus ##2G##SMK - SMKmsg17 - C_HazardFromSMK";
CM_ SG_ 1093 Lamp_SmrtWlcmLtOnReq "Lamp_SmartWelcomeLightOnRequest ##2G##SMK - SMKmsg17 - C_WlightOn";
CM_ SG_ 1093 Fob_BattStaInfo "Fob_BatteryStatusInformation ##2G##SMK - SMKmsg17 - C_FOBBatteryStatusInfo";
CM_ SG_ 1093 Fob_FoundDrvWlcmArea "Fob_FoundDriverWelcomeArea ##2G##SMK - SMKmsg17 - C_WelcomeFobFoundDrv";
CM_ SG_ 1093 Fob_FoundAsstWlcmArea "Fob_FoundAssistWelcomeArea ##2G##SMK - SMKmsg17 - C_WelcomeFobFoundAst";
CM_ SG_ 1093 Fob_FoundExtrnlArea "Fob_FoundExternalArea ##2G##SMK - SMKmsg18 - C_ExtFobPos";
CM_ SG_ 1093 Fob_FoundIntArea "Fob_FoundInternalArea ##2G##SMK - SMKmsg18 - C_IntFobPos";
CM_ SG_ 1093 Fob_LearntSta "Fob_LearntStatus ##2G##SMK - SMKmsg18 - C_FobLearntState";
CM_ SG_ 1093 RSPA_RFSigErrSta "RSPA_RFSignalErrorState";
CM_ SG_ 1093 RSPA_CanErrSta "RSPA_CANErrorState";
CM_ SG_ 1093 LFAnt_FltSta "LFAntenna_FaultSatus ##2G##SMK - SMKmsg18 - C_LFANTState";
CM_ SG_ 1093 LFAnt_SrchSta "LFAntenna_SearchingStatus ##2G##SMK - SMKmsg19 - C_LFSearchingOn";
CM_ SG_ 1093 RSPA_ModSta_SMK "RSPA_ModeStatus ##2G##SMK - SMKmsg18 - C_SMKRSPAMode";
CM_ SG_ 1093 RSPA_FobBattSta "RSPA_FobBatteryStatus ##2G##SMK - SMKmsg18 - C_FobBATState";
CM_ SG_ 1093 USM_SmrtTrnkTlgtModSta "USM_SmartTunkTailgateModeStatus ##2G##SMK - SMKmsg20 - C_HfreeTrunkTgRValue";
CM_ SG_ 1093 USM_WALModSta "USM_WalkAwayLockModeStatus ##2G##SMK - SMKmsg20 - C_WALRValue";
CM_ SG_ 1093 Fob_FoundWlcmArea "Fob_FoundWlcmArea ##2G##SMK - SMKmsg17 -C_FobFoundWlcmArea";
CM_ BO_ 830 "[PE] Periodic and On Event";
CM_ SG_ 830 USM_CmdWPC2Sta "USM_CommandWPC2Status";
CM_ SG_ 830 WPC2_SWVerMajor1 "First Word(ASCII) in WPC2 S/W Ver";
CM_ SG_ 830 WPC2_PhnLftWrngSta "WPC2_PhoneLeftWarningStatus";
CM_ SG_ 830 WPC2_SWVerMinor1 "Second Word(ASCII) in WPC2 S/W Ver";
CM_ SG_ 830 WPC2_SWVerMinor2 "Third Word(ASCII) in WPC2 S/W Ver";
CM_ BO_ 1099 "[PE] Periodic and On Event";
CM_ SG_ 1099 USM_CmdWPCSta "USM_CommandWPCStatus";
CM_ SG_ 1099 WPC_SWVerMajor1 "First Word(ASCII) in WPC S/W Ver";
CM_ SG_ 1099 WPC_PhnLftWrngSta "WPC_PhoneLeftWarningStatus";
CM_ SG_ 1099 WPC_SWVerMinor1 "Second Word(ASCII) in WPC S/W Ver";
CM_ SG_ 1099 WPC_SWVerMinor2 "Third Word(ASCII) in WPC S/W Ver";
CM_ BO_ 1837 "[TP] Transport Protocol";
BA_DEF_ BO_ "DiagState" ENUM "No","Yes" ;
BA_DEF_ BO_ "DiagResponse" ENUM "No","Yes" ;
BA_DEF_ BO_ "DiagRequest" ENUM "No","Yes" ;
BA_DEF_ BO_ "TpMessage" ENUM "No","Yes" ;
BA_DEF_ BO_ "UsrMsgIDSforwardDeviation" INT 0 100 ;
BA_DEF_ BO_ "UsrMsgIDSbackwardDeviation" INT 50 1000 ;
BA_DEF_ "BusType" STRING ;
BA_DEF_ "DBName" STRING ;
BA_DEF_ "Baudrate" INT 50000 1000000 ;
BA_DEF_ "GenEnvVarEndingDsp" STRING ;
BA_DEF_ "GenEnvVarEndingSnd" STRING ;
BA_DEF_ "GenEnvVarPrefix" STRING ;
BA_DEF_ "GenNWMApBusSleep" STRING ;
BA_DEF_ "GenNWMApCanNormal" STRING ;
BA_DEF_ "GenNWMApCanOff" STRING ;
BA_DEF_ "GenNWMApCanOn" STRING ;
BA_DEF_ "GenNWMApCanSleep" STRING ;
BA_DEF_ "GenNWMApCanWakeUp" STRING ;
BA_DEF_ "GenNWMGotoMode_Awake" STRING ;
BA_DEF_ "GenNWMGotoMode_BusSleep" STRING ;
BA_DEF_ "GenNWMSleepTime" INT 1375 1650 ;
BA_DEF_ "GenNWMTalkNM" STRING ;
BA_DEF_ "Manufacturer" STRING ;
BA_DEF_ "NmBaseAddress" HEX 0 2047 ;
BA_DEF_ "NmMessageCount" INT 0 128 ;
BA_DEF_ "NmType" STRING ;
BA_DEF_ "SamplePointMax" INT 50 85 ;
BA_DEF_ "SamplePointMin" INT 55 85 ;
BA_DEF_ "SyncJumpWidthMax" INT 1 8 ;
BA_DEF_ "SyncJumpWidthMin" INT 1 4 ;
BA_DEF_ "VersionDay" INT 1 31 ;
BA_DEF_ "VersionMonth" INT 1 12 ;
BA_DEF_ "VersionNumber" INT 0 999999 ;
BA_DEF_ "VersionNumberInternal" INT 0 9999 ;
BA_DEF_ "VersionWeek" INT 1 53 ;
BA_DEF_ "VersionYear" INT 0 9999 ;
BA_DEF_ BU_ "NmStationAddress" HEX 0 127 ;
BA_DEF_ BU_ "NmNode" ENUM "No","Yes" ;
BA_DEF_ BU_ "GenNodSleepTime" INT 1375 1650 ;
BA_DEF_ BU_ "ILUsed" ENUM "No","Yes" ;
BA_DEF_ BU_ "NmCAN" INT 1 2 ;
BA_DEF_ BU_ "NodeLayerModules" STRING ;
BA_DEF_ BU_ "NWM_Knoten" ENUM "No","Yes" ;
BA_DEF_ BO_ "GenMsgCycleTime" INT 0 2000 ;
BA_DEF_ BO_ "GenMsgStartDelayTime" INT 0 2000 ;
BA_DEF_ BO_ "GenMsgSendType" ENUM "Cyclic","NoMsgSendType" ;
BA_DEF_ BO_ "GenMsgCycleTimeFast" INT 0 500 ;
BA_DEF_ BO_ "GenMsgDelayTime" INT 0 20 ;
BA_DEF_ BO_ "GenMsgILSupport" ENUM "No","Yes" ;
BA_DEF_ BO_ "GenMsgNrOfRepetition" INT 0 3 ;
BA_DEF_ BO_ "NmMessage" ENUM "No","Yes" ;
BA_DEF_ BO_ "NWM-Botschaft" ENUM "No","Yes" ;
BA_DEF_ BO_ "TpTxIndex" INT 0 65535 ;
BA_DEF_ BO_ "VFrameFormat" ENUM "StandardCAN","ExtendedCAN","reserved","reserved","reserved","reserved","reserved","reserved","reserved","reserved","reserved","reserved","reserved","reserved","StandardCAN_FD","ExtendedCAN_FD" ;
BA_DEF_ SG_ "UserSigValidity" ENUM "B+","ACC","IG","IG1","IG2","IG3","IG1 or IG2","IG1 or IG3","Undef" ;
BA_DEF_ SG_ "TimeoutValue" STRING ;
BA_DEF_ SG_ "UsrSigPurpose" ENUM "Undef","FN","DIAG","DIAG(Req)","DIAG(Res)","DIAG(Phy)","DEV","CCP(Req)","CCP(Res)","NM","TP" ;
BA_DEF_ SG_ "GenSigStartValue" INT 0 1215752192 ;
BA_DEF_ SG_ "NetworkRequest" ENUM "Yes","No" ;
BA_DEF_ SG_ "NetworkRequestHoldingTime" INT 0 65535 ;
BA_DEF_ SG_ "Description" STRING ;
BA_DEF_ SG_ "Version" STRING ;
BA_DEF_ SG_ "GenSigEnvVarType" ENUM "Int","Float","Undef" ;
BA_DEF_ SG_ "GenSigSendType" ENUM "Cyclic","OnWrite","OnWriteWithRepetition","OnChange","OnChangeWithRepetition","IfActive","IfActiveWithRepetition","NoSigSendType","OnChangeAndIfActive","OnChangeAndIfActiveWithRepetition" ;
BA_DEF_ SG_ "GwSigLatencyTime" INT 0 65536 ;
BA_DEF_ SG_ "GwSigMissingSourceType" ENUM "Undef","OldValue","DefaultValue","InitialValue" ;
BA_DEF_ SG_ "NWM-WakeupAllowed" ENUM "<n.a.>" ;
BA_DEF_ SG_ "RoutingFactor" INT 1 1215752192 ;
BA_DEF_REL_ BU_SG_REL_ "GenSigTimeoutTime" INT 0 7000 ;
BA_DEF_DEF_ "DiagState" "No" ;
BA_DEF_DEF_ "DiagResponse" "No" ;
BA_DEF_DEF_ "DiagRequest" "No" ;
BA_DEF_DEF_ "TpMessage" "No" ;
BA_DEF_DEF_ "UsrMsgIDSforwardDeviation" 10 ;
BA_DEF_DEF_ "UsrMsgIDSbackwardDeviation" 100 ;
BA_DEF_DEF_ "BusType" "CAN" ;
BA_DEF_DEF_ "DBName" "" ;
BA_DEF_DEF_ "Baudrate" 500000 ;
BA_DEF_DEF_ "GenEnvVarEndingDsp" "Dsp_" ;
BA_DEF_DEF_ "GenEnvVarEndingSnd" "_" ;
BA_DEF_DEF_ "GenEnvVarPrefix" "Env" ;
BA_DEF_DEF_ "GenNWMApBusSleep" "AppNmCanBusSleep()" ;
BA_DEF_DEF_ "GenNWMApCanNormal" "AppNmCanNormal()" ;
BA_DEF_DEF_ "GenNWMApCanOff" "ApplCanOffline()" ;
BA_DEF_DEF_ "GenNWMApCanOn" "ApplCanOnline()" ;
BA_DEF_DEF_ "GenNWMApCanSleep" "ApplNmCanSleep()" ;
BA_DEF_DEF_ "GenNWMApCanWakeUp" "ApplCanWakeUp()" ;
BA_DEF_DEF_ "GenNWMGotoMode_Awake" "GotoMode_Awake()" ;
BA_DEF_DEF_ "GenNWMGotoMode_BusSleep" "GotoMode_BusSleep()" ;
BA_DEF_DEF_ "GenNWMSleepTime" 1500 ;
BA_DEF_DEF_ "GenNWMTalkNM" "TalkNM()" ;
BA_DEF_DEF_ "Manufacturer" "HMC" ;
BA_DEF_DEF_ "NmBaseAddress" 1280 ;
BA_DEF_DEF_ "NmMessageCount" 128 ;
BA_DEF_DEF_ "NmType" "Vector" ;
BA_DEF_DEF_ "SamplePointMax" 80 ;
BA_DEF_DEF_ "SamplePointMin" 80 ;
BA_DEF_DEF_ "SyncJumpWidthMax" 3 ;
BA_DEF_DEF_ "SyncJumpWidthMin" 2 ;
BA_DEF_DEF_ "VersionDay" 1 ;
BA_DEF_DEF_ "VersionMonth" 1 ;
BA_DEF_DEF_ "VersionNumber" 0 ;
BA_DEF_DEF_ "VersionNumberInternal" 0 ;
BA_DEF_DEF_ "VersionWeek" 1 ;
BA_DEF_DEF_ "VersionYear" 0 ;
BA_DEF_DEF_ "NmStationAddress" 0 ;
BA_DEF_DEF_ "NmNode" "Yes" ;
BA_DEF_DEF_ "GenNodSleepTime" 1500 ;
BA_DEF_DEF_ "ILUsed" "Yes" ;
BA_DEF_DEF_ "NmCAN" 1 ;
BA_DEF_DEF_ "NodeLayerModules" "oseknm01.dll,CANoeILNLVector.dll" ;
BA_DEF_DEF_ "NWM_Knoten" "Yes" ;
BA_DEF_DEF_ "GenMsgCycleTime" 200 ;
BA_DEF_DEF_ "GenMsgStartDelayTime" 0 ;
BA_DEF_DEF_ "GenMsgSendType" "NoMsgSendType" ;
BA_DEF_DEF_ "GenMsgCycleTimeFast" 40 ;
BA_DEF_DEF_ "GenMsgDelayTime" 20 ;
BA_DEF_DEF_ "GenMsgILSupport" "Yes" ;
BA_DEF_DEF_ "GenMsgNrOfRepetition" 3 ;
BA_DEF_DEF_ "NmMessage" "No" ;
BA_DEF_DEF_ "NWM-Botschaft" "No" ;
BA_DEF_DEF_ "TpTxIndex" 0 ;
BA_DEF_DEF_ "VFrameFormat" "StandardCAN" ;
BA_DEF_DEF_ "UserSigValidity" "IG" ;
BA_DEF_DEF_ "TimeoutValue" "" ;
BA_DEF_DEF_ "UsrSigPurpose" "FN" ;
BA_DEF_DEF_ "GenSigStartValue" 0 ;
BA_DEF_DEF_ "NetworkRequest" "No" ;
BA_DEF_DEF_ "NetworkRequestHoldingTime" 0 ;
BA_DEF_DEF_ "Description" "" ;
BA_DEF_DEF_ "Version" "" ;
BA_DEF_DEF_ "GenSigEnvVarType" "Undef" ;
BA_DEF_DEF_ "GenSigSendType" "NoSigSendType" ;
BA_DEF_DEF_ "GwSigLatencyTime" 40 ;
BA_DEF_DEF_ "GwSigMissingSourceType" "Undef" ;
BA_DEF_DEF_ "NWM-WakeupAllowed" "<n.a.>" ;
BA_DEF_DEF_ "RoutingFactor" 1 ;
BA_DEF_DEF_REL_ "GenSigTimeoutTime" 500 ;
BA_ "DBName" "HS_B2";
BA_ "VersionYear" 1;
BA_ "VersionNumber" 7;
BA_ "NmStationAddress" BU_ CGW_CCU 112;
BA_ "GenMsgSendType" BO_ 1050 0;
BA_ "Description" SG_ 1050 BCM_Crc7Val "The data area for CRC calculation is based on the data length (DLC) of the message DB.

The CRC shall be calculated over the entire data block (excluding the CRC bytes) including the user data, alive counter and Data ID 

 

- CRC Polynomial (0x1D) , Initial Value : 0x00, XOR value : 0xFF, Data ID Mode : Both, Data ID : Message ID + 0xF800 

- The initial value is for CRC calculation and the message should be sent with the calculated result value. 

The mathematical expression to 8 bit CRC polynomial is given here. G(x) = x8 + x4 + x3 + x2 + 1";
BA_ "GenSigSendType" SG_ 1050 BCM_Crc7Val 4;
BA_ "UserSigValidity" SG_ 1050 BCM_Crc7Val 0;
BA_ "Version" SG_ 1050 BCM_Crc7Val "21.09.03";
BA_ "Description" SG_ 1050 BCM_AlvCnt7Val "For the first transmission request for a data element the counter shall be initialized with 0 and shall be incremented by 1

for every subsequent send request. When the counter reaches the maximum value(0xE), then it shall restart with 0 for the next send request";
BA_ "GenSigSendType" SG_ 1050 BCM_AlvCnt7Val 4;
BA_ "UserSigValidity" SG_ 1050 BCM_AlvCnt7Val 0;
BA_ "Version" SG_ 1050 BCM_AlvCnt7Val "21.09.03";
BA_ "Description" SG_ 1050 Lamp_HiPrioHzrdReq "-Higher priority than SJB hazard

-Diag/Arm/DisArm/Balarm/Panic/MTS

-Initial Value: 2";
BA_ "GenSigSendType" SG_ 1050 Lamp_HiPrioHzrdReq 4;
BA_ "GenSigStartValue" SG_ 1050 Lamp_HiPrioHzrdReq 2;
BA_ "UserSigValidity" SG_ 1050 Lamp_HiPrioHzrdReq 0;
BA_ "NetworkRequest" SG_ 1050 Lamp_HiPrioHzrdReq 0;
BA_ "NetworkRequestHoldingTime" SG_ 1050 Lamp_HiPrioHzrdReq 5000;
BA_ "Version" SG_ 1050 Lamp_HiPrioHzrdReq "17.12.00";
BA_ "Description" SG_ 1050 Lamp_LoPrioHzrdReq "-Lower priority than SJB hazard

-TrunkOpenClose/CrashUnlock/RemoteStart

-Initial Value: 2";
BA_ "GenSigSendType" SG_ 1050 Lamp_LoPrioHzrdReq 4;
BA_ "GenSigStartValue" SG_ 1050 Lamp_LoPrioHzrdReq 2;
BA_ "UserSigValidity" SG_ 1050 Lamp_LoPrioHzrdReq 0;
BA_ "NetworkRequest" SG_ 1050 Lamp_LoPrioHzrdReq 0;
BA_ "NetworkRequestHoldingTime" SG_ 1050 Lamp_LoPrioHzrdReq 5000;
BA_ "Version" SG_ 1050 Lamp_LoPrioHzrdReq "17.12.00";
BA_ "NmStationAddress" BU_ FCS 33;
BA_ "NmStationAddress" BU_ WPC 30;
BA_ "NmStationAddress" BU_ RWPC 31;
BA_ "NmStationAddress" BU_ APSU 49;
BA_ "NmStationAddress" BU_ RLHV 52;
BA_ "NmStationAddress" BU_ RRHV 53;
BA_ "NmStationAddress" BU_ SHVU_FR 42;
BA_ "NmStationAddress" BU_ SHVU_RR 43;
BA_ "NmStationAddress" BU_ DPSU 56;
BA_ "NmStationAddress" BU_ WPC2 21;
BA_ "Description" SG_ 1050 Lamp_IntTailLmpOnReq "-(Old)C_INTTailOn";
BA_ "GenSigSendType" SG_ 1050 Lamp_IntTailLmpOnReq 4;
BA_ "UserSigValidity" SG_ 1050 Lamp_IntTailLmpOnReq 0;
BA_REL_ "GenSigTimeoutTime" BU_SG_REL_ FCS SG_ 1050 Lamp_IntTailLmpOnReq 1500;
BA_REL_ "GenSigTimeoutTime" BU_SG_REL_ WPC SG_ 1050 Lamp_IntTailLmpOnReq 1500;
BA_REL_ "GenSigTimeoutTime" BU_SG_REL_ RWPC SG_ 1050 Lamp_IntTailLmpOnReq 1500;
BA_REL_ "GenSigTimeoutTime" BU_SG_REL_ APSU SG_ 1050 Lamp_IntTailLmpOnReq 1500;
BA_REL_ "GenSigTimeoutTime" BU_SG_REL_ RLHV SG_ 1050 Lamp_IntTailLmpOnReq 1500;
BA_REL_ "GenSigTimeoutTime" BU_SG_REL_ RRHV SG_ 1050 Lamp_IntTailLmpOnReq 1500;
BA_REL_ "GenSigTimeoutTime" BU_SG_REL_ SHVU_FR SG_ 1050 Lamp_IntTailLmpOnReq 1500;
BA_REL_ "GenSigTimeoutTime" BU_SG_REL_ SHVU_RR SG_ 1050 Lamp_IntTailLmpOnReq 1500;
BA_REL_ "GenSigTimeoutTime" BU_SG_REL_ DPSU SG_ 1050 Lamp_IntTailLmpOnReq 1500;
BA_REL_ "GenSigTimeoutTime" BU_SG_REL_ WPC2 SG_ 1050 Lamp_IntTailLmpOnReq 1500;
BA_ "NetworkRequest" SG_ 1050 Lamp_IntTailLmpOnReq 0;
BA_ "NetworkRequestHoldingTime" SG_ 1050 Lamp_IntTailLmpOnReq 5000;
BA_ "Version" SG_ 1050 Lamp_IntTailLmpOnReq "17.12.00";
BA_ "NmStationAddress" BU_ BLTN_CAM 72;
BA_ "Description" SG_ 1050 Lamp_ExtrnlTailLmpOnReq "-(Old)C_EXTTailOn";
BA_ "GenSigSendType" SG_ 1050 Lamp_ExtrnlTailLmpOnReq 4;
BA_ "UserSigValidity" SG_ 1050 Lamp_ExtrnlTailLmpOnReq 0;
BA_REL_ "GenSigTimeoutTime" BU_SG_REL_ BLTN_CAM SG_ 1050 Lamp_ExtrnlTailLmpOnReq 1500;
BA_ "NetworkRequest" SG_ 1050 Lamp_ExtrnlTailLmpOnReq 0;
BA_ "NetworkRequestHoldingTime" SG_ 1050 Lamp_ExtrnlTailLmpOnReq 5000;
BA_ "Version" SG_ 1050 Lamp_ExtrnlTailLmpOnReq "17.12.00";
BA_ "Description" SG_ 1050 Lamp_HdLmpLoOnReq "-(Old)C_HLampLowON";
BA_ "GenSigSendType" SG_ 1050 Lamp_HdLmpLoOnReq 4;
BA_ "UserSigValidity" SG_ 1050 Lamp_HdLmpLoOnReq 0;
BA_ "NetworkRequest" SG_ 1050 Lamp_HdLmpLoOnReq 0;
BA_ "NetworkRequestHoldingTime" SG_ 1050 Lamp_HdLmpLoOnReq 5000;
BA_ "Version" SG_ 1050 Lamp_HdLmpLoOnReq "17.12.00";
BA_ "Description" SG_ 1050 Lamp_HdLmpHiOnReq "-(Old)C_HLampHighON";
BA_ "GenSigSendType" SG_ 1050 Lamp_HdLmpHiOnReq 4;
BA_ "UserSigValidity" SG_ 1050 Lamp_HdLmpHiOnReq 0;
BA_ "NetworkRequest" SG_ 1050 Lamp_HdLmpHiOnReq 0;
BA_ "NetworkRequestHoldingTime" SG_ 1050 Lamp_HdLmpHiOnReq 5000;
BA_ "Version" SG_ 1050 Lamp_HdLmpHiOnReq "17.12.00";
BA_ "NmStationAddress" BU_ SWRC 8;
BA_ "NmStationAddress" BU_ ATS 80;
BA_ "Description" SG_ 1050 Lamp_AvTailLmpSta "-Send with at the same time with C_IntTailOn

-Initiail Value: 1";
BA_ "GenSigSendType" SG_ 1050 Lamp_AvTailLmpSta 4;
BA_ "GenSigStartValue" SG_ 1050 Lamp_AvTailLmpSta 1;
BA_ "UserSigValidity" SG_ 1050 Lamp_AvTailLmpSta 0;
BA_REL_ "GenSigTimeoutTime" BU_SG_REL_ SWRC SG_ 1050 Lamp_AvTailLmpSta 1500;
BA_REL_ "GenSigTimeoutTime" BU_SG_REL_ APSU SG_ 1050 Lamp_AvTailLmpSta 1500;
BA_REL_ "GenSigTimeoutTime" BU_SG_REL_ ATS SG_ 1050 Lamp_AvTailLmpSta 1500;
BA_ "NetworkRequest" SG_ 1050 Lamp_AvTailLmpSta 0;
BA_ "NetworkRequestHoldingTime" SG_ 1050 Lamp_AvTailLmpSta 5000;
BA_ "Version" SG_ 1050 Lamp_AvTailLmpSta "17.12.00";
BA_ "Description" SG_ 1050 Lamp_BckUpLmpCmd "BackUp Lamp On/Off Command";
BA_ "GenSigSendType" SG_ 1050 Lamp_BckUpLmpCmd 4;
BA_ "UserSigValidity" SG_ 1050 Lamp_BckUpLmpCmd 0;
BA_ "NetworkRequest" SG_ 1050 Lamp_BckUpLmpCmd 0;
BA_ "NetworkRequestHoldingTime" SG_ 1050 Lamp_BckUpLmpCmd 5000;
BA_ "Version" SG_ 1050 Lamp_BckUpLmpCmd "20.08.02";
BA_ "Description" SG_ 1050 Lamp_DrlOnReq "Lamp on command for DRL";
BA_ "GenSigSendType" SG_ 1050 Lamp_DrlOnReq 4;
BA_ "UserSigValidity" SG_ 1050 Lamp_DrlOnReq 0;
BA_ "NetworkRequest" SG_ 1050 Lamp_DrlOnReq 0;
BA_ "NetworkRequestHoldingTime" SG_ 1050 Lamp_DrlOnReq 5000;
BA_ "Version" SG_ 1050 Lamp_DrlOnReq "20.09.00";
BA_ "Description" SG_ 1050 USM_IllAlwaysOnwithPSTNSta "Current setting value for IntTailOn with DRL/PSTN";
BA_ "GenSigSendType" SG_ 1050 USM_IllAlwaysOnwithPSTNSta 4;
BA_ "UserSigValidity" SG_ 1050 USM_IllAlwaysOnwithPSTNSta 0;
BA_ "NetworkRequest" SG_ 1050 USM_IllAlwaysOnwithPSTNSta 0;
BA_ "NetworkRequestHoldingTime" SG_ 1050 USM_IllAlwaysOnwithPSTNSta 5000;
BA_ "Version" SG_ 1050 USM_IllAlwaysOnwithPSTNSta "22.06.00";
BA_ "GenMsgSendType" BO_ 1090 0;
BA_ "Description" SG_ 1090 BCM_Crc12Val "The data area for CRC calculation is based on the data length (DLC) of the message DB.

The CRC shall be calculated over the entire data block (excluding the CRC bytes) including the user data, alive counter and Data ID 

 

- CRC Polynomial (0x1D) , Initial Value : 0x00, XOR value : 0xFF, Data ID Mode : Both, Data ID : Message ID + 0xF800 

- The initial value is for CRC calculation and the message should be sent with the calculated result value. 

The mathematical expression to 8 bit CRC polynomial is given here. G(x) = x8 + x4 + x3 + x2 + 1";
BA_ "GenSigSendType" SG_ 1090 BCM_Crc12Val 4;
BA_ "UserSigValidity" SG_ 1090 BCM_Crc12Val 0;
BA_ "Version" SG_ 1090 BCM_Crc12Val "21.09.03";
BA_ "Description" SG_ 1090 BCM_AlvCnt12Val "For the first transmission request for a data element the counter shall be initialized with 0 and shall be incremented by 1

for every subsequent send request. When the counter reaches the maximum value(0xE), then it shall restart with 0 for the next send request";
BA_ "GenSigSendType" SG_ 1090 BCM_AlvCnt12Val 4;
BA_ "UserSigValidity" SG_ 1090 BCM_AlvCnt12Val 0;
BA_ "Version" SG_ 1090 BCM_AlvCnt12Val "21.09.03";
BA_ "Description" SG_ 1090 BCM_SmkOptTyp "-(Old)C_PICOption";
BA_ "GenSigSendType" SG_ 1090 BCM_SmkOptTyp 4;
BA_ "UserSigValidity" SG_ 1090 BCM_SmkOptTyp 0;
BA_REL_ "GenSigTimeoutTime" BU_SG_REL_ WPC SG_ 1090 BCM_SmkOptTyp 1500;
BA_REL_ "GenSigTimeoutTime" BU_SG_REL_ RWPC SG_ 1090 BCM_SmkOptTyp 1500;
BA_REL_ "GenSigTimeoutTime" BU_SG_REL_ WPC2 SG_ 1090 BCM_SmkOptTyp 1500;
BA_ "NetworkRequest" SG_ 1090 BCM_SmkOptTyp 0;
BA_ "NetworkRequestHoldingTime" SG_ 1090 BCM_SmkOptTyp 5000;
BA_ "Version" SG_ 1090 BCM_SmkOptTyp "17.12.00";
BA_ "Description" SG_ 1090 PHEV_FuelDrOpnSta "This signal means state of fuel door switch (Open/Close)



Fuel door switch located in fuel door, thus switch states means physical status of fuel door(Open/Close)







* Applied LF PHEV Fuel Door Control Workshop Result



Timeout Value



P-CAN(EMS) : 0x1, 



C-CAN(CLU) : 0x0";
BA_ "GenSigSendType" SG_ 1090 PHEV_FuelDrOpnSta 4;
BA_ "UserSigValidity" SG_ 1090 PHEV_FuelDrOpnSta 0;
BA_ "NetworkRequest" SG_ 1090 PHEV_FuelDrOpnSta 0;
BA_ "NetworkRequestHoldingTime" SG_ 1090 PHEV_FuelDrOpnSta 5000;
BA_ "Version" SG_ 1090 PHEV_FuelDrOpnSta "18.03.04";
BA_ "Description" SG_ 1090 BCM_SunRoofOptTyp "Option Signal for Sunroof system

(C_SunroofOpt)";
BA_ "GenSigSendType" SG_ 1090 BCM_SunRoofOptTyp 4;
BA_ "UserSigValidity" SG_ 1090 BCM_SunRoofOptTyp 0;
BA_REL_ "GenSigTimeoutTime" BU_SG_REL_ ATS SG_ 1090 BCM_SunRoofOptTyp 1500;
BA_ "Version" SG_ 1090 BCM_SunRoofOptTyp "18.09.00";
BA_ "GenSigSendType" SG_ 1090 Window_DrvrSdWdwSta_BCM 4;
BA_ "UserSigValidity" SG_ 1090 Window_DrvrSdWdwSta_BCM 0;
BA_ "NetworkRequest" SG_ 1090 Window_DrvrSdWdwSta_BCM 0;
BA_ "NetworkRequestHoldingTime" SG_ 1090 Window_DrvrSdWdwSta_BCM 5000;
BA_ "Version" SG_ 1090 Window_DrvrSdWdwSta_BCM "17.12.00";
BA_ "Description" SG_ 1090 Window_AsstSdWdwSta_BCM "-(Old)C_AstWdwStat";
BA_ "GenSigSendType" SG_ 1090 Window_AsstSdWdwSta_BCM 4;
BA_ "UserSigValidity" SG_ 1090 Window_AsstSdWdwSta_BCM 0;
BA_ "NetworkRequest" SG_ 1090 Window_AsstSdWdwSta_BCM 0;
BA_ "NetworkRequestHoldingTime" SG_ 1090 Window_AsstSdWdwSta_BCM 5000;
BA_ "Version" SG_ 1090 Window_AsstSdWdwSta_BCM "17.12.00";
BA_ "Description" SG_ 1090 Window_RrLftWdwSta_BCM "-(Old)C_RLWdwSta";
BA_ "GenSigSendType" SG_ 1090 Window_RrLftWdwSta_BCM 4;
BA_ "UserSigValidity" SG_ 1090 Window_RrLftWdwSta_BCM 0;
BA_REL_ "GenSigTimeoutTime" BU_SG_REL_ ATS SG_ 1090 Window_RrLftWdwSta_BCM 1500;
BA_ "NetworkRequest" SG_ 1090 Window_RrLftWdwSta_BCM 0;
BA_ "NetworkRequestHoldingTime" SG_ 1090 Window_RrLftWdwSta_BCM 5000;
BA_ "Version" SG_ 1090 Window_RrLftWdwSta_BCM "17.12.00";
BA_ "Description" SG_ 1090 Window_RrRtWdwSta_BCM "-(Old)C_RRWdwStat";
BA_ "GenSigSendType" SG_ 1090 Window_RrRtWdwSta_BCM 4;
BA_ "UserSigValidity" SG_ 1090 Window_RrRtWdwSta_BCM 0;
BA_REL_ "GenSigTimeoutTime" BU_SG_REL_ ATS SG_ 1090 Window_RrRtWdwSta_BCM 1500;
BA_ "NetworkRequest" SG_ 1090 Window_RrRtWdwSta_BCM 0;
BA_ "NetworkRequestHoldingTime" SG_ 1090 Window_RrRtWdwSta_BCM 5000;
BA_ "Version" SG_ 1090 Window_RrRtWdwSta_BCM "17.12.00";
BA_ "Description" SG_ 1090 SunRoof_GlassPosSta "This signal indicates Sunroof Glass Open/Close Status

(C_GlassPositionState)";
BA_ "GenSigSendType" SG_ 1090 SunRoof_GlassPosSta 4;
BA_ "GenSigStartValue" SG_ 1090 SunRoof_GlassPosSta 15;
BA_ "UserSigValidity" SG_ 1090 SunRoof_GlassPosSta 0;
BA_ "Version" SG_ 1090 SunRoof_GlassPosSta "18.09.00";
BA_ "Description" SG_ 1090 PHEV_FuelDrDis "PHEV Fuel Door Control CLU Display Message from BCM";
BA_ "GenSigSendType" SG_ 1090 PHEV_FuelDrDis 4;
BA_ "UserSigValidity" SG_ 1090 PHEV_FuelDrDis 0;
BA_ "NetworkRequest" SG_ 1090 PHEV_FuelDrDis 0;
BA_ "NetworkRequestHoldingTime" SG_ 1090 PHEV_FuelDrDis 5000;
BA_ "Version" SG_ 1090 PHEV_FuelDrDis "18.03.04";
BA_ "Description" SG_ 1090 SunRoof_BlindPosSta "This signal indicates Sunroof Blind Open/Close Status

(C_BlindPositionState)";
BA_ "GenSigSendType" SG_ 1090 SunRoof_BlindPosSta 4;
BA_ "GenSigStartValue" SG_ 1090 SunRoof_BlindPosSta 15;
BA_ "UserSigValidity" SG_ 1090 SunRoof_BlindPosSta 0;
BA_ "Version" SG_ 1090 SunRoof_BlindPosSta "18.09.00";
BA_ "Description" SG_ 1090 SunRoof_GlassErrSta "This signal indicates Sunroof Glass error Status

(C_GlassErrorState)";
BA_ "GenSigSendType" SG_ 1090 SunRoof_GlassErrSta 4;
BA_ "UserSigValidity" SG_ 1090 SunRoof_GlassErrSta 0;
BA_ "Version" SG_ 1090 SunRoof_GlassErrSta "18.09.00";
BA_ "Description" SG_ 1090 SunRoof_BlindErrSta "This signal indicates Sunroof Blind error Status

(C_BlindErrorState)";
BA_ "GenSigSendType" SG_ 1090 SunRoof_BlindErrSta 4;
BA_ "UserSigValidity" SG_ 1090 SunRoof_BlindErrSta 0;
BA_ "Version" SG_ 1090 SunRoof_BlindErrSta "18.09.00";
BA_ "GenMsgSendType" BO_ 2256644609 0;
BA_ "GenMsgCycleTime" BO_ 2256644609 100;
BA_ "GenMsgCycleTimeFast" BO_ 2256644609 0;
BA_ "GenMsgNrOfRepetition" BO_ 2256644609 0;
BA_ "VFrameFormat" BO_ 2256644609 1;
BA_ "Description" SG_ 2256644609 CLU_Crc1Val "The data area for CRC calculation is based on the data length (DLC) of the message DB.

The CRC shall be calculated over the entire data block (excluding the CRC bytes) including the user data, alive counter and Data ID



- CRC Polynomial (0x1021) , Initial Value : 0xFFFF, XOR value : 0x0000, Data ID : Message ID + 0xF800 

- The initial value is for CRC calculation and the message should be sent with the calculated result value. 

- The mathematical expression to 16 bit CRC polynomial is given here. G(x) = x16 + x12 + x5 + 1



<For CRC calculation of CAN-FD Msg for HS CAN domain ECUs>



- HS-CAN Messages that routed from CAN-FD domain are using 29 bit Extended CAN ID and splitted into 8 Byte Messages.

(from 1 to 4 Msgs, depending on source CAN-FD Msg’s DLC)

- For splitted CAN-FD Msgs’ CRC calculation, HS CAN ECUs should use source CAN-FD Msg’s original STD ID. 

- The original STD ID can be read from Ext ID’s 4~6th Byte.

Eg. STD 0x6AA : EXT SPLT 0x1A8[6AA]01 / 0x1A8[6AA]02 / 0x1A8[6AA]03 / 0x1A8[6AA]04 

(2~4th splitited Msgs can be omitted depending on source CAN-FD Msg’s DLC)

- Aslo, HS-CAN ECUs should use merged data block (from whole splitted Msg) for CRC calculation.";
BA_ "GenSigStartValue" SG_ 2256644609 CLU_Crc1Val 65535;
BA_ "UserSigValidity" SG_ 2256644609 CLU_Crc1Val 3;
BA_REL_ "GenSigTimeoutTime" BU_SG_REL_ SHVU_RR SG_ 2256644609 CLU_Crc1Val 1500;
BA_REL_ "GenSigTimeoutTime" BU_SG_REL_ DPSU SG_ 2256644609 CLU_Crc1Val 1500;
BA_REL_ "GenSigTimeoutTime" BU_SG_REL_ ATS SG_ 2256644609 CLU_Crc1Val 1500;
BA_ "RoutingFactor" SG_ 2256644609 CLU_Crc1Val 5;
BA_ "Version" SG_ 2256644609 CLU_Crc1Val "21.09.03";
BA_ "NmStationAddress" BU_ EMCU 17;
BA_ "Description" SG_ 2256644609 CLU_AlvCnt1Val "For the first transmission request for a data element the counter shall be initialized with 0 and shall be incremented by 1 for every subsequent send request. 

When the counter reaches the maximum value(0xFF), then it shall restart with 0 for the next send request";
BA_ "UserSigValidity" SG_ 2256644609 CLU_AlvCnt1Val 3;
BA_REL_ "GenSigTimeoutTime" BU_SG_REL_ SHVU_RR SG_ 2256644609 CLU_AlvCnt1Val 1500;
BA_REL_ "GenSigTimeoutTime" BU_SG_REL_ DPSU SG_ 2256644609 CLU_AlvCnt1Val 1500;
BA_REL_ "GenSigTimeoutTime" BU_SG_REL_ ATS SG_ 2256644609 CLU_AlvCnt1Val 1500;
BA_REL_ "GenSigTimeoutTime" BU_SG_REL_ EMCU SG_ 2256644609 CLU_AlvCnt1Val 1500;
BA_ "RoutingFactor" SG_ 2256644609 CLU_AlvCnt1Val 5;
BA_ "Version" SG_ 2256644609 CLU_AlvCnt1Val "21.09.03";
BA_ "NmStationAddress" BU_ ARS 10;
BA_ "NmStationAddress" BU_ RCS 70;
BA_ "NmStationAddress" BU_ RRPSU 29;
BA_ "NmStationAddress" BU_ RLPSU 28;
BA_ "NmStationAddress" BU_ DSAU 89;
BA_ "NmStationAddress" BU_ ASAU 83;
BA_ "NmStationAddress" BU_ OHCL 84;
BA_ "Description" SG_ 2256644609 CLU_DtntOutSta "This signal indicates the status of detent illumination. Cluster sends the detent information for a Unified Illumination system.";
BA_ "UserSigValidity" SG_ 2256644609 CLU_DtntOutSta 0;
BA_REL_ "GenSigTimeoutTime" BU_SG_REL_ FCS SG_ 2256644609 CLU_DtntOutSta 1500;
BA_REL_ "GenSigTimeoutTime" BU_SG_REL_ WPC SG_ 2256644609 CLU_DtntOutSta 1500;
BA_REL_ "GenSigTimeoutTime" BU_SG_REL_ RWPC SG_ 2256644609 CLU_DtntOutSta 1500;
BA_REL_ "GenSigTimeoutTime" BU_SG_REL_ ARS SG_ 2256644609 CLU_DtntOutSta 1500;
BA_REL_ "GenSigTimeoutTime" BU_SG_REL_ SWRC SG_ 2256644609 CLU_DtntOutSta 1500;
BA_REL_ "GenSigTimeoutTime" BU_SG_REL_ APSU SG_ 2256644609 CLU_DtntOutSta 1500;
BA_REL_ "GenSigTimeoutTime" BU_SG_REL_ RLHV SG_ 2256644609 CLU_DtntOutSta 1500;
BA_REL_ "GenSigTimeoutTime" BU_SG_REL_ RRHV SG_ 2256644609 CLU_DtntOutSta 1500;
BA_REL_ "GenSigTimeoutTime" BU_SG_REL_ SHVU_FR SG_ 2256644609 CLU_DtntOutSta 1500;
BA_REL_ "GenSigTimeoutTime" BU_SG_REL_ SHVU_RR SG_ 2256644609 CLU_DtntOutSta 1500;
BA_REL_ "GenSigTimeoutTime" BU_SG_REL_ DPSU SG_ 2256644609 CLU_DtntOutSta 1500;
BA_REL_ "GenSigTimeoutTime" BU_SG_REL_ RCS SG_ 2256644609 CLU_DtntOutSta 1500;
BA_REL_ "GenSigTimeoutTime" BU_SG_REL_ RRPSU SG_ 2256644609 CLU_DtntOutSta 1500;
BA_REL_ "GenSigTimeoutTime" BU_SG_REL_ RLPSU SG_ 2256644609 CLU_DtntOutSta 1500;
BA_REL_ "GenSigTimeoutTime" BU_SG_REL_ ATS SG_ 2256644609 CLU_DtntOutSta 1500;
BA_REL_ "GenSigTimeoutTime" BU_SG_REL_ DSAU SG_ 2256644609 CLU_DtntOutSta 1500;
BA_REL_ "GenSigTimeoutTime" BU_SG_REL_ ASAU SG_ 2256644609 CLU_DtntOutSta 1500;
BA_REL_ "GenSigTimeoutTime" BU_SG_REL_ OHCL SG_ 2256644609 CLU_DtntOutSta 1500;
BA_REL_ "GenSigTimeoutTime" BU_SG_REL_ WPC2 SG_ 2256644609 CLU_DtntOutSta 1500;
BA_ "RoutingFactor" SG_ 2256644609 CLU_DtntOutSta 5;
BA_ "Version" SG_ 2256644609 CLU_DtntOutSta "17.11.00";
BA_ "Description" SG_ 2256644609 CLU_SpdUnitTyp "This signal indicates the unit of the speed displayed in the speedometer.";
BA_ "UserSigValidity" SG_ 2256644609 CLU_SpdUnitTyp 3;
BA_REL_ "GenSigTimeoutTime" BU_SG_REL_ DPSU SG_ 2256644609 CLU_SpdUnitTyp 1500;
BA_REL_ "GenSigTimeoutTime" BU_SG_REL_ BLTN_CAM SG_ 2256644609 CLU_SpdUnitTyp 1500;
BA_REL_ "GenSigTimeoutTime" BU_SG_REL_ EMCU SG_ 2256644609 CLU_SpdUnitTyp 1500;
BA_REL_ "GenSigTimeoutTime" BU_SG_REL_ WPC2 SG_ 2256644609 CLU_SpdUnitTyp 1500;
BA_ "RoutingFactor" SG_ 2256644609 CLU_SpdUnitTyp 5;
BA_ "Version" SG_ 2256644609 CLU_SpdUnitTyp "17.11.00";
BA_ "Description" SG_ 2256644609 CLU_DisSpdDcmlVal "The signal 'CF_Clu_VanzDecimal' means the extra value of the signal 'CF_Clu_Vanz' (vehicle speed which is indicated in the speedometer)

Also, This signal should be sent in km/h or MPH according to the 'CF_Clu_SPEED_UNIT' signal.

CF_Clu_SPEED_UNIT = 0 : [km/h]

CF_Clu_SPEED_UNIT = 1 : [MPH]



Example)   CF_Clu_Vanz = 13,  CF_Clu_VanzDecimal  = 3

Displayed vehicle speed  = (CF_Clu_Vanz / 2) + (CF_Clu_VanzDecimal / 8)

= ( 13 / 2 ) + ( 3 / 8 ) = 6.875 [Km/h or MPH]";
BA_ "UserSigValidity" SG_ 2256644609 CLU_DisSpdDcmlVal 3;
BA_ "RoutingFactor" SG_ 2256644609 CLU_DisSpdDcmlVal 5;
BA_ "Version" SG_ 2256644609 CLU_DisSpdDcmlVal "17.11.00";
BA_ "Description" SG_ 2256644609 CLU_SWRCCrsMainSwSta "Cruise on/off switch";
BA_ "UserSigValidity" SG_ 2256644609 CLU_SWRCCrsMainSwSta 3;
BA_ "RoutingFactor" SG_ 2256644609 CLU_SWRCCrsMainSwSta 5;
BA_ "Version" SG_ 2256644609 CLU_SWRCCrsMainSwSta "18.04.00";
BA_ "Description" SG_ 2256644609 CLU_SWRCCrsSwSta "Depending on whether One-touch logic is applied, the meaning of each signal value is divided into two cases as shown below



Case1) Not applied

0x0:Idle Position

0x1:Resume/Plus

0x2:Set/Minus

0x3:Time gap (Distance, SCC only)

0x4:ACC/SCC cancel



Case2) Applied

0x0: Idle Position

0x1: Plus/Set

0x2: Minus/Set

0x3: Time gap (Distance, SCC only)

0x4: Pause/Resume";
BA_ "UserSigValidity" SG_ 2256644609 CLU_SWRCCrsSwSta 3;
BA_ "RoutingFactor" SG_ 2256644609 CLU_SWRCCrsSwSta 5;
BA_ "Version" SG_ 2256644609 CLU_SWRCCrsSwSta "18.07.01";
BA_ "Description" SG_ 2256644609 CLU_SWRCLFASwSta "LFA/HDA on/off switch";
BA_ "UserSigValidity" SG_ 2256644609 CLU_SWRCLFASwSta 3;
BA_ "RoutingFactor" SG_ 2256644609 CLU_SWRCLFASwSta 5;
BA_ "Version" SG_ 2256644609 CLU_SWRCLFASwSta "18.04.00";
BA_ "Description" SG_ 2256644609 CLU_SWRCSldMainSwSta "Speedlimiter on/off switch";
BA_ "UserSigValidity" SG_ 2256644609 CLU_SWRCSldMainSwSta 3;
BA_ "RoutingFactor" SG_ 2256644609 CLU_SWRCSldMainSwSta 5;
BA_ "Version" SG_ 2256644609 CLU_SWRCSldMainSwSta "18.04.00";
BA_ "Description" SG_ 2256644609 CLU_RhstaLvlSta "This signal is used for a rheostat level of CLUSTER from 1 to 21 level (21 level : Detent) for a Unified Illumination system.



※ Start Value : Current value";
BA_ "UserSigValidity" SG_ 2256644609 CLU_RhstaLvlSta 0;
BA_REL_ "GenSigTimeoutTime" BU_SG_REL_ FCS SG_ 2256644609 CLU_RhstaLvlSta 1500;
BA_REL_ "GenSigTimeoutTime" BU_SG_REL_ WPC SG_ 2256644609 CLU_RhstaLvlSta 1500;
BA_REL_ "GenSigTimeoutTime" BU_SG_REL_ RWPC SG_ 2256644609 CLU_RhstaLvlSta 1500;
BA_REL_ "GenSigTimeoutTime" BU_SG_REL_ ARS SG_ 2256644609 CLU_RhstaLvlSta 1500;
BA_REL_ "GenSigTimeoutTime" BU_SG_REL_ SWRC SG_ 2256644609 CLU_RhstaLvlSta 1500;
BA_REL_ "GenSigTimeoutTime" BU_SG_REL_ APSU SG_ 2256644609 CLU_RhstaLvlSta 1500;
BA_REL_ "GenSigTimeoutTime" BU_SG_REL_ RLHV SG_ 2256644609 CLU_RhstaLvlSta 1500;
BA_REL_ "GenSigTimeoutTime" BU_SG_REL_ RRHV SG_ 2256644609 CLU_RhstaLvlSta 1500;
BA_REL_ "GenSigTimeoutTime" BU_SG_REL_ SHVU_FR SG_ 2256644609 CLU_RhstaLvlSta 1500;
BA_REL_ "GenSigTimeoutTime" BU_SG_REL_ SHVU_RR SG_ 2256644609 CLU_RhstaLvlSta 1500;
BA_REL_ "GenSigTimeoutTime" BU_SG_REL_ DPSU SG_ 2256644609 CLU_RhstaLvlSta 1500;
BA_REL_ "GenSigTimeoutTime" BU_SG_REL_ RCS SG_ 2256644609 CLU_RhstaLvlSta 1500;
BA_REL_ "GenSigTimeoutTime" BU_SG_REL_ RRPSU SG_ 2256644609 CLU_RhstaLvlSta 1500;
BA_REL_ "GenSigTimeoutTime" BU_SG_REL_ RLPSU SG_ 2256644609 CLU_RhstaLvlSta 1500;
BA_REL_ "GenSigTimeoutTime" BU_SG_REL_ ATS SG_ 2256644609 CLU_RhstaLvlSta 1500;
BA_REL_ "GenSigTimeoutTime" BU_SG_REL_ DSAU SG_ 2256644609 CLU_RhstaLvlSta 1500;
BA_REL_ "GenSigTimeoutTime" BU_SG_REL_ ASAU SG_ 2256644609 CLU_RhstaLvlSta 1500;
BA_REL_ "GenSigTimeoutTime" BU_SG_REL_ OHCL SG_ 2256644609 CLU_RhstaLvlSta 1500;
BA_REL_ "GenSigTimeoutTime" BU_SG_REL_ WPC2 SG_ 2256644609 CLU_RhstaLvlSta 1500;
BA_ "RoutingFactor" SG_ 2256644609 CLU_RhstaLvlSta 5;
BA_ "Version" SG_ 2256644609 CLU_RhstaLvlSta "17.11.00";
BA_ "Description" SG_ 2256644609 CLU_DisSpdVal "The vehicle speed which is indicated in the speedmeter has to be sent to SCC. This value is used for evalution of SCC command values instead of the vehicle velocity in order to avoid significant difference between the speedmeter indicator and the set speed indicator(especially in the case of free cruising with the set speed). In terms of debouning and presnce on CAN, the same time scales have to be used and described for time gap setting.

This signal should be sent in km/h or MPH according to the “SPEED_UNIT” signal.

SPEED_UNIT = 0 : [km/h]

SPEED_UNIT = 1 : [MPH]";
BA_ "UserSigValidity" SG_ 2256644609 CLU_DisSpdVal 3;
BA_REL_ "GenSigTimeoutTime" BU_SG_REL_ APSU SG_ 2256644609 CLU_DisSpdVal 1500;
BA_REL_ "GenSigTimeoutTime" BU_SG_REL_ DPSU SG_ 2256644609 CLU_DisSpdVal 1500;
BA_REL_ "GenSigTimeoutTime" BU_SG_REL_ BLTN_CAM SG_ 2256644609 CLU_DisSpdVal 1500;
BA_REL_ "GenSigTimeoutTime" BU_SG_REL_ EMCU SG_ 2256644609 CLU_DisSpdVal 1500;
BA_REL_ "GenSigTimeoutTime" BU_SG_REL_ WPC2 SG_ 2256644609 CLU_DisSpdVal 1500;
BA_ "RoutingFactor" SG_ 2256644609 CLU_DisSpdVal 5;
BA_ "Version" SG_ 2256644609 CLU_DisSpdVal "17.12.03";
BA_ "Description" SG_ 2256644609 CLU_OKSwSta "This signal represents operating status of Ok Switch in Steering Wheel. Default value of this signal is 0 and the value is set to 1 only while a driver is pressing the OK Switch.";
BA_ "UserSigValidity" SG_ 2256644609 CLU_OKSwSta 3;
BA_ "RoutingFactor" SG_ 2256644609 CLU_OKSwSta 5;
BA_ "Version" SG_ 2256644609 CLU_OKSwSta "19.03.06";
BA_ "GenMsgSendType" BO_ 2256644610 0;
BA_ "GenMsgCycleTime" BO_ 2256644610 100;
BA_ "GenMsgCycleTimeFast" BO_ 2256644610 0;
BA_ "GenMsgNrOfRepetition" BO_ 2256644610 0;
BA_ "VFrameFormat" BO_ 2256644610 1;
BA_ "NmStationAddress" BU_ DLBCU 64;
BA_ "NmStationAddress" BU_ PFSU 45;
BA_ "NmStationAddress" BU_ RCM 61;
BA_ "NmStationAddress" BU_ ALBCU 68;
BA_ "Description" SG_ 2256644610 CLU_DisSpdVal_KPH "The vehicle speed which is indicated in the speedmeter.

This signal should be sent in km/h only.";
BA_ "UserSigValidity" SG_ 2256644610 CLU_DisSpdVal_KPH 3;
BA_REL_ "GenSigTimeoutTime" BU_SG_REL_ WPC SG_ 2256644610 CLU_DisSpdVal_KPH 1500;
BA_REL_ "GenSigTimeoutTime" BU_SG_REL_ RWPC SG_ 2256644610 CLU_DisSpdVal_KPH 1500;
BA_REL_ "GenSigTimeoutTime" BU_SG_REL_ APSU SG_ 2256644610 CLU_DisSpdVal_KPH 1500;
BA_REL_ "GenSigTimeoutTime" BU_SG_REL_ RLHV SG_ 2256644610 CLU_DisSpdVal_KPH 1500;
BA_REL_ "GenSigTimeoutTime" BU_SG_REL_ RRHV SG_ 2256644610 CLU_DisSpdVal_KPH 1500;
BA_REL_ "GenSigTimeoutTime" BU_SG_REL_ SHVU_FR SG_ 2256644610 CLU_DisSpdVal_KPH 1500;
BA_REL_ "GenSigTimeoutTime" BU_SG_REL_ SHVU_RR SG_ 2256644610 CLU_DisSpdVal_KPH 1500;
BA_REL_ "GenSigTimeoutTime" BU_SG_REL_ DPSU SG_ 2256644610 CLU_DisSpdVal_KPH 1500;
BA_REL_ "GenSigTimeoutTime" BU_SG_REL_ DLBCU SG_ 2256644610 CLU_DisSpdVal_KPH 1500;
BA_REL_ "GenSigTimeoutTime" BU_SG_REL_ PFSU SG_ 2256644610 CLU_DisSpdVal_KPH 1500;
BA_REL_ "GenSigTimeoutTime" BU_SG_REL_ RRPSU SG_ 2256644610 CLU_DisSpdVal_KPH 1500;
BA_REL_ "GenSigTimeoutTime" BU_SG_REL_ RLPSU SG_ 2256644610 CLU_DisSpdVal_KPH 1500;
BA_REL_ "GenSigTimeoutTime" BU_SG_REL_ ATS SG_ 2256644610 CLU_DisSpdVal_KPH 1500;
BA_REL_ "GenSigTimeoutTime" BU_SG_REL_ DSAU SG_ 2256644610 CLU_DisSpdVal_KPH 1500;
BA_REL_ "GenSigTimeoutTime" BU_SG_REL_ ASAU SG_ 2256644610 CLU_DisSpdVal_KPH 1500;
BA_REL_ "GenSigTimeoutTime" BU_SG_REL_ RCM SG_ 2256644610 CLU_DisSpdVal_KPH 1500;
BA_REL_ "GenSigTimeoutTime" BU_SG_REL_ ALBCU SG_ 2256644610 CLU_DisSpdVal_KPH 1500;
BA_REL_ "GenSigTimeoutTime" BU_SG_REL_ WPC2 SG_ 2256644610 CLU_DisSpdVal_KPH 1500;
BA_ "RoutingFactor" SG_ 2256644610 CLU_DisSpdVal_KPH 5;
BA_ "Version" SG_ 2256644610 CLU_DisSpdVal_KPH "17.12.09";
BA_ "Description" SG_ 2256644610 CLU_CUSTOMSta_NEW "This is a signal for New concept CUSTOM mode in AVN USM

This is a confirm signal for selecting CUSTOM mode in AVN USM

And Other units refer this signal when CUSTOM mode (CLU_DrvngModSwSta=0x6

). Other unit decided the Detailed CUSTOM Mode with this signal

EX>

 In AVN USM, MY DRIVE MODE is selected, sent CLU_CUSTOMSta_NEW= 0x1

In vehicle, current mode is MY DRIVE MODE, other unit refer this signal and decide detailed Mode.In this case, MY DRIVE MODE is a mode";
BA_ "UserSigValidity" SG_ 2256644610 CLU_CUSTOMSta_NEW 3;
BA_REL_ "GenSigTimeoutTime" BU_SG_REL_ SWRC SG_ 2256644610 CLU_CUSTOMSta_NEW 1500;
BA_ "RoutingFactor" SG_ 2256644610 CLU_CUSTOMSta_NEW 5;
BA_ "Version" SG_ 2256644610 CLU_CUSTOMSta_NEW "20.08.07";
BA_ "Description" SG_ 2256644610 CLU_AutoBrightSta "This signal is used for a auto bright level of CLUSTER from 1step to 200step for a Unified Illumination system.



※ Start Value : Current value";
BA_ "UserSigValidity" SG_ 2256644610 CLU_AutoBrightSta 0;
BA_REL_ "GenSigTimeoutTime" BU_SG_REL_ FCS SG_ 2256644610 CLU_AutoBrightSta 1500;
BA_REL_ "GenSigTimeoutTime" BU_SG_REL_ WPC SG_ 2256644610 CLU_AutoBrightSta 1500;
BA_REL_ "GenSigTimeoutTime" BU_SG_REL_ RWPC SG_ 2256644610 CLU_AutoBrightSta 1500;
BA_REL_ "GenSigTimeoutTime" BU_SG_REL_ SWRC SG_ 2256644610 CLU_AutoBrightSta 1500;
BA_REL_ "GenSigTimeoutTime" BU_SG_REL_ APSU SG_ 2256644610 CLU_AutoBrightSta 1500;
BA_REL_ "GenSigTimeoutTime" BU_SG_REL_ RLHV SG_ 2256644610 CLU_AutoBrightSta 1500;
BA_REL_ "GenSigTimeoutTime" BU_SG_REL_ RRHV SG_ 2256644610 CLU_AutoBrightSta 1500;
BA_REL_ "GenSigTimeoutTime" BU_SG_REL_ SHVU_FR SG_ 2256644610 CLU_AutoBrightSta 1500;
BA_REL_ "GenSigTimeoutTime" BU_SG_REL_ SHVU_RR SG_ 2256644610 CLU_AutoBrightSta 1500;
BA_REL_ "GenSigTimeoutTime" BU_SG_REL_ DPSU SG_ 2256644610 CLU_AutoBrightSta 1500;
BA_REL_ "GenSigTimeoutTime" BU_SG_REL_ RCS SG_ 2256644610 CLU_AutoBrightSta 1500;
BA_REL_ "GenSigTimeoutTime" BU_SG_REL_ ATS SG_ 2256644610 CLU_AutoBrightSta 1500;
BA_REL_ "GenSigTimeoutTime" BU_SG_REL_ DSAU SG_ 2256644610 CLU_AutoBrightSta 1500;
BA_REL_ "GenSigTimeoutTime" BU_SG_REL_ ASAU SG_ 2256644610 CLU_AutoBrightSta 1500;
BA_REL_ "GenSigTimeoutTime" BU_SG_REL_ OHCL SG_ 2256644610 CLU_AutoBrightSta 1500;
BA_REL_ "GenSigTimeoutTime" BU_SG_REL_ BLTN_CAM SG_ 2256644610 CLU_AutoBrightSta 1500;
BA_REL_ "GenSigTimeoutTime" BU_SG_REL_ WPC2 SG_ 2256644610 CLU_AutoBrightSta 1500;
BA_ "RoutingFactor" SG_ 2256644610 CLU_AutoBrightSta 5;
BA_ "Version" SG_ 2256644610 CLU_AutoBrightSta "20.12.05";
BA_ "Description" SG_ 2256644610 CLU_NotMinModeBrightSta "This signal is used for a Cluster brightness level when not in minimum brightness mode.



※ Start Value : Current value";
BA_ "UserSigValidity" SG_ 2256644610 CLU_NotMinModeBrightSta 0;
BA_ "RoutingFactor" SG_ 2256644610 CLU_NotMinModeBrightSta 5;
BA_ "Version" SG_ 2256644610 CLU_NotMinModeBrightSta "22.07.06";
BA_ "Description" SG_ 2256644610 CLU_PwrAutoOffResetReq_HCU "This signal is used for a request to reset power auto off time

when OK sw on, this signal 0x1 for 3 period times,and send 0x0 

It is signal for HCU";
BA_ "UserSigValidity" SG_ 2256644610 CLU_PwrAutoOffResetReq_HCU 3;
BA_ "RoutingFactor" SG_ 2256644610 CLU_PwrAutoOffResetReq_HCU 5;
BA_ "Version" SG_ 2256644610 CLU_PwrAutoOffResetReq_HCU "19.10.03";
BA_ "GenMsgCycleTime" BO_ 2470760705 0;
BA_ "VFrameFormat" BO_ 2470760705 1;
BA_ "Description" SG_ 2470760705 CLU_Crc5Val "The data area for CRC calculation is based on the data length (DLC) of the message DB.

The CRC shall be calculated over the entire data block (excluding the CRC bytes) including the user data, alive counter and Data ID



- CRC Polynomial (0x1021) , Initial Value : 0xFFFF, XOR value : 0x0000, Data ID : Message ID + 0xF800 

- The initial value is for CRC calculation and the message should be sent with the calculated result value. 

- The mathematical expression to 16 bit CRC polynomial is given here. G(x) = x16 + x12 + x5 + 1



<For CRC calculation of CAN-FD Msg for HS CAN domain ECUs>



- HS-CAN Messages that routed from CAN-FD domain are using 29 bit Extended CAN ID and splitted into 8 Byte Messages.

(from 1 to 4 Msgs, depending on source CAN-FD Msg’s DLC)

- For splitted CAN-FD Msgs’ CRC calculation, HS CAN ECUs should use source CAN-FD Msg’s original STD ID. 

- The original STD ID can be read from Ext ID’s 4~6th Byte.

Eg. STD 0x6AA : EXT SPLT 0x1A8[6AA]01 / 0x1A8[6AA]02 / 0x1A8[6AA]03 / 0x1A8[6AA]04 

(2~4th splitited Msgs can be omitted depending on source CAN-FD Msg’s DLC)

- Aslo, HS-CAN ECUs should use merged data block (from whole splitted Msg) for CRC calculation.";
BA_ "GenSigSendType" SG_ 2470760705 CLU_Crc5Val 4;
BA_ "GenSigStartValue" SG_ 2470760705 CLU_Crc5Val 65535;
BA_ "UserSigValidity" SG_ 2470760705 CLU_Crc5Val 3;
BA_ "Version" SG_ 2470760705 CLU_Crc5Val "21.09.03";
BA_ "Description" SG_ 2470760705 CLU_AlvCnt5Val "For the first transmission request for a data element the counter shall be initialized with 0 and shall be incremented by 1 for every subsequent send request. 

When the counter reaches the maximum value(0xFF), then it shall restart with 0 for the next send request";
BA_ "GenSigSendType" SG_ 2470760705 CLU_AlvCnt5Val 4;
BA_ "UserSigValidity" SG_ 2470760705 CLU_AlvCnt5Val 3;
BA_ "Version" SG_ 2470760705 CLU_AlvCnt5Val "21.09.03";
BA_ "Description" SG_ 2470760705 USM_TlgtAwayCloseSetReq "This signal is used for a request to set the value of USM Menus. 

This signal requests to set Tailgate Away close system On/Off

When this signal change, the message is sent 3 times.";
BA_ "GenSigSendType" SG_ 2470760705 USM_TlgtAwayCloseSetReq 4;
BA_ "UserSigValidity" SG_ 2470760705 USM_TlgtAwayCloseSetReq 3;
BA_ "Version" SG_ 2470760705 USM_TlgtAwayCloseSetReq "20.03.02";
BA_ "Description" SG_ 2470760705 USM_InletAutoLockSetReq "This signal is used for a request to set the value of USM Menus. This signal requests to change status of Charging Connector Locking Mode.";
BA_ "GenSigSendType" SG_ 2470760705 USM_InletAutoLockSetReq 4;
BA_ "UserSigValidity" SG_ 2470760705 USM_InletAutoLockSetReq 3;
BA_ "Version" SG_ 2470760705 USM_InletAutoLockSetReq "19.01.10";
BA_ "Description" SG_ 2470760705 USM_IFSActVehSpd_Set "IFS 진입 속도 설정 메뉴";
BA_ "GenSigSendType" SG_ 2470760705 USM_IFSActVehSpd_Set 4;
BA_ "UserSigValidity" SG_ 2470760705 USM_IFSActVehSpd_Set 3;
BA_ "Version" SG_ 2470760705 USM_IFSActVehSpd_Set "21.09.05";
BA_ "Description" SG_ 2470760705 USM_StaRst1Req "This signal is used for a request to reset the value of USM menus.

When this signal change, the message (CLU16) is sent 3 times.";
BA_ "GenSigSendType" SG_ 2470760705 USM_StaRst1Req 4;
BA_ "UserSigValidity" SG_ 2470760705 USM_StaRst1Req 3;
BA_REL_ "GenSigTimeoutTime" BU_SG_REL_ WPC SG_ 2470760705 USM_StaRst1Req 0;
BA_REL_ "GenSigTimeoutTime" BU_SG_REL_ DPSU SG_ 2470760705 USM_StaRst1Req 0;
BA_REL_ "GenSigTimeoutTime" BU_SG_REL_ WPC2 SG_ 2470760705 USM_StaRst1Req 0;
BA_ "Version" SG_ 2470760705 USM_StaRst1Req "17.11.00";
BA_ "Description" SG_ 2470760705 USM_NccCamSetReq "This signal describes the status of CC with Navigation function.(speed camera control) - User Setting Menu for the cluster";
BA_ "GenSigSendType" SG_ 2470760705 USM_NccCamSetReq 4;
BA_ "UserSigValidity" SG_ 2470760705 USM_NccCamSetReq 3;
BA_ "Version" SG_ 2470760705 USM_NccCamSetReq "17.11.00";
BA_ "Description" SG_ 2470760705 CLU_RrStRemindDelayReq "This singal is the delay request for ROA";
BA_ "GenSigSendType" SG_ 2470760705 CLU_RrStRemindDelayReq 4;
BA_ "UserSigValidity" SG_ 2470760705 CLU_RrStRemindDelayReq 0;
BA_ "Version" SG_ 2470760705 CLU_RrStRemindDelayReq "22.05.02";
BA_ "Description" SG_ 2470760705 CLU_RrStRemindDelayFdbckReq "This signal is user input feedback for Rear Seat Reminder";
BA_ "GenSigSendType" SG_ 2470760705 CLU_RrStRemindDelayFdbckReq 4;
BA_ "UserSigValidity" SG_ 2470760705 CLU_RrStRemindDelayFdbckReq 0;
BA_ "Version" SG_ 2470760705 CLU_RrStRemindDelayFdbckReq "22.05.02";
BA_ "GenMsgCycleTime" BO_ 2470763009 0;
BA_ "VFrameFormat" BO_ 2470763009 1;
BA_ "Description" SG_ 2470763009 CLU_Crc9Val "The data area for CRC calculation is based on the data length (DLC) of the message DB.

The CRC shall be calculated over the entire data block (excluding the CRC bytes) including the user data, alive counter and Data ID



- CRC Polynomial (0x1021) , Initial Value : 0xFFFF, XOR value : 0x0000, Data ID : Message ID + 0xF800 

- The initial value is for CRC calculation and the message should be sent with the calculated result value. 

- The mathematical expression to 16 bit CRC polynomial is given here. G(x) = x16 + x12 + x5 + 1



<For CRC calculation of CAN-FD Msg for HS CAN domain ECUs>



- HS-CAN Messages that routed from CAN-FD domain are using 29 bit Extended CAN ID and splitted into 8 Byte Messages.

(from 1 to 4 Msgs, depending on source CAN-FD Msg’s DLC)

- For splitted CAN-FD Msgs’ CRC calculation, HS CAN ECUs should use source CAN-FD Msg’s original STD ID. 

- The original STD ID can be read from Ext ID’s 4~6th Byte.

Eg. STD 0x6AA : EXT SPLT 0x1A8[6AA]01 / 0x1A8[6AA]02 / 0x1A8[6AA]03 / 0x1A8[6AA]04 

(2~4th splitited Msgs can be omitted depending on source CAN-FD Msg’s DLC)

- Aslo, HS-CAN ECUs should use merged data block (from whole splitted Msg) for CRC calculation.";
BA_ "GenSigSendType" SG_ 2470763009 CLU_Crc9Val 4;
BA_ "GenSigStartValue" SG_ 2470763009 CLU_Crc9Val 65535;
BA_ "UserSigValidity" SG_ 2470763009 CLU_Crc9Val 3;
BA_ "Version" SG_ 2470763009 CLU_Crc9Val "21.09.03";
BA_ "Description" SG_ 2470763009 CLU_AlvCnt9Val "For the first transmission request for a data element the counter shall be initialized with 0 and shall be incremented by 1 for every subsequent send request. 

When the counter reaches the maximum value(0xFF), then it shall restart with 0 for the next send request";
BA_ "GenSigSendType" SG_ 2470763009 CLU_AlvCnt9Val 4;
BA_ "UserSigValidity" SG_ 2470763009 CLU_AlvCnt9Val 3;
BA_ "Version" SG_ 2470763009 CLU_AlvCnt9Val "21.09.03";
BA_ "Description" SG_ 2470763009 USM_MdLmpClrSetReq "Request set the Mood Lamp Color";
BA_ "GenSigSendType" SG_ 2470763009 USM_MdLmpClrSetReq 4;
BA_ "UserSigValidity" SG_ 2470763009 USM_MdLmpClrSetReq 3;
BA_ "Version" SG_ 2470763009 USM_MdLmpClrSetReq "20.08.06";
BA_ "Description" SG_ 2470763009 USM_RrWiperRevSetReq "Request to set RearWiper Reverse Mode";
BA_ "GenSigSendType" SG_ 2470763009 USM_RrWiperRevSetReq 4;
BA_ "UserSigValidity" SG_ 2470763009 USM_RrWiperRevSetReq 3;
BA_ "Version" SG_ 2470763009 USM_RrWiperRevSetReq "17.11.00";
BA_ "Description" SG_ 2470763009 USM_RrStRemindSetReq "USM Function for RearSeatReminder on/off SW";
BA_ "GenSigSendType" SG_ 2470763009 USM_RrStRemindSetReq 4;
BA_ "UserSigValidity" SG_ 2470763009 USM_RrStRemindSetReq 3;
BA_ "Version" SG_ 2470763009 USM_RrStRemindSetReq "19.01.04";
BA_ "Description" SG_ 2470763009 USM_RrWpcSetReq "USM Function for REAR WPC(Wireless Phone Chager) on/off SW";
BA_ "GenSigSendType" SG_ 2470763009 USM_RrWpcSetReq 4;
BA_ "UserSigValidity" SG_ 2470763009 USM_RrWpcSetReq 3;
BA_ "Version" SG_ 2470763009 USM_RrWpcSetReq "17.11.00";
BA_ "Description" SG_ 2470763009 USM_WpcSetReq "USM Function for WPC(Wireless Phone Chager) on/off SW";
BA_ "GenSigSendType" SG_ 2470763009 USM_WpcSetReq 4;
BA_ "UserSigValidity" SG_ 2470763009 USM_WpcSetReq 3;
BA_REL_ "GenSigTimeoutTime" BU_SG_REL_ WPC SG_ 2470763009 USM_WpcSetReq 0;
BA_REL_ "GenSigTimeoutTime" BU_SG_REL_ WPC2 SG_ 2470763009 USM_WpcSetReq 0;
BA_ "Version" SG_ 2470763009 USM_WpcSetReq "17.11.00";
BA_ "Description" SG_ 2470763009 USM_SeqLmpSetReq "This signal is used for a request to set the value of USM Menus. This signal requests to change status of SequencialLamp ON/OFF setting.





When this signal change, the message (CLU18) is sent 3 times.";
BA_ "GenSigSendType" SG_ 2470763009 USM_SeqLmpSetReq 4;
BA_ "UserSigValidity" SG_ 2470763009 USM_SeqLmpSetReq 3;
BA_ "Version" SG_ 2470763009 USM_SeqLmpSetReq "17.11.00";
BA_ "Description" SG_ 2470763009 USM_UnlckWlcmSetReq "This signal is used for a request to set the value of USM Menus. This signal requests to change status of Welcome System setting.





When this signal change, the message (CLU18) is sent 3 times.";
BA_ "GenSigSendType" SG_ 2470763009 USM_UnlckWlcmSetReq 4;
BA_ "UserSigValidity" SG_ 2470763009 USM_UnlckWlcmSetReq 3;
BA_ "Version" SG_ 2470763009 USM_UnlckWlcmSetReq "17.11.00";
BA_ "Description" SG_ 2470763009 USM_SmrtWlcmSetReq "This signal is used for a request to set the value of USM Menus. This signal requests to change status of Welcome System setting.





When this signal change, the message (CLU18) is sent 3 times.";
BA_ "GenSigSendType" SG_ 2470763009 USM_SmrtWlcmSetReq 4;
BA_ "UserSigValidity" SG_ 2470763009 USM_SmrtWlcmSetReq 3;
BA_ "Version" SG_ 2470763009 USM_SmrtWlcmSetReq "17.11.00";
BA_ "Description" SG_ 2470763009 USM_UipSetReq "Request to set Uip(Ultrasonic Intrusion Protection)

This signal is used for a request to set the value of USM Menus. 

When this signal change, the message is sent 3 times.";
BA_ "GenSigSendType" SG_ 2470763009 USM_UipSetReq 4;
BA_ "UserSigValidity" SG_ 2470763009 USM_UipSetReq 3;
BA_ "Version" SG_ 2470763009 USM_UipSetReq "18.11.07";
BA_ "Description" SG_ 2470763009 USM_DigitalKeyEnblSetReq "This signal is used for a request to set the value of USM Menus. This signal requests to set Digital Key On/Off.";
BA_ "GenSigSendType" SG_ 2470763009 USM_DigitalKeyEnblSetReq 4;
BA_ "UserSigValidity" SG_ 2470763009 USM_DigitalKeyEnblSetReq 3;
BA_ "Version" SG_ 2470763009 USM_DigitalKeyEnblSetReq "18.11.00";
BA_ "Description" SG_ 2470763009 USM_OwnerPhnRegSetReq "This signal is used for a request to set the value of USM Menus.

This signal requests to set Digital Key On/Off";
BA_ "GenSigSendType" SG_ 2470763009 USM_OwnerPhnRegSetReq 4;
BA_ "UserSigValidity" SG_ 2470763009 USM_OwnerPhnRegSetReq 3;
BA_ "Version" SG_ 2470763009 USM_OwnerPhnRegSetReq "18.11.00";
BA_ "Description" SG_ 2470763009 USM_NFCCard1RegSetReq "This signal is used for a request to set the value of USM Menus. This signal requests to go through the process for NFC Card 1 recoding.";
BA_ "GenSigSendType" SG_ 2470763009 USM_NFCCard1RegSetReq 4;
BA_ "UserSigValidity" SG_ 2470763009 USM_NFCCard1RegSetReq 3;
BA_ "Version" SG_ 2470763009 USM_NFCCard1RegSetReq "18.11.00";
BA_ "Description" SG_ 2470763009 USM_NFCCard2RegSetReq "This signal is used for arequest to set the value of usm menus.

This signal requests to go through the process NFC Card 2 recording";
BA_ "GenSigSendType" SG_ 2470763009 USM_NFCCard2RegSetReq 4;
BA_ "UserSigValidity" SG_ 2470763009 USM_NFCCard2RegSetReq 3;
BA_ "Version" SG_ 2470763009 USM_NFCCard2RegSetReq "18.11.00";
BA_ "Description" SG_ 2470763009 USM_ProcStpReq "This signal is used for a request to escape the IAU Authorizaton processing";
BA_ "GenSigSendType" SG_ 2470763009 USM_ProcStpReq 4;
BA_ "UserSigValidity" SG_ 2470763009 USM_ProcStpReq 3;
BA_ "Version" SG_ 2470763009 USM_ProcStpReq "18.11.00";
BA_ "Description" SG_ 2470763009 USM_PwrAutoOffTimeSetReq "This signal is used for a request to set the value of USM Menus. This signal requests to change status of Power auto off time setting.";
BA_ "GenSigSendType" SG_ 2470763009 USM_PwrAutoOffTimeSetReq 4;
BA_ "UserSigValidity" SG_ 2470763009 USM_PwrAutoOffTimeSetReq 3;
BA_ "Version" SG_ 2470763009 USM_PwrAutoOffTimeSetReq "18.12.02";
BA_ "Description" SG_ 2470763009 USM_RrStRemindSetReq_RestMode "This is a signal for Rear Seat remind USM 

Request to set  Restmod of Rear Seat remind";
BA_ "GenSigSendType" SG_ 2470763009 USM_RrStRemindSetReq_RestMode 4;
BA_ "UserSigValidity" SG_ 2470763009 USM_RrStRemindSetReq_RestMode 3;
BA_ "Version" SG_ 2470763009 USM_RrStRemindSetReq_RestMode "19.09.04";
BA_ "Description" SG_ 2470763009 USM_1stRrStRemindSetReq "USM Function for RearSeatReminder on/off SW for IBU only Type";
BA_ "GenSigSendType" SG_ 2470763009 USM_1stRrStRemindSetReq 4;
BA_ "UserSigValidity" SG_ 2470763009 USM_1stRrStRemindSetReq 3;
BA_ "Version" SG_ 2470763009 USM_1stRrStRemindSetReq "20.02.06";
BA_ "Description" SG_ 2470763009 USM_Wpc2SetReq "USM Function for WPC(Wireless Phone Chager) on/off SW";
BA_ "GenSigSendType" SG_ 2470763009 USM_Wpc2SetReq 4;
BA_ "UserSigValidity" SG_ 2470763009 USM_Wpc2SetReq 3;
BA_REL_ "GenSigTimeoutTime" BU_SG_REL_ WPC2 SG_ 2470763009 USM_Wpc2SetReq 0;
BA_ "Version" SG_ 2470763009 USM_Wpc2SetReq "22.02.06";
BA_ "GenMsgSendType" BO_ 2353206529 0;
BA_ "GenMsgCycleTimeFast" BO_ 2353206529 0;
BA_ "GenMsgNrOfRepetition" BO_ 2353206529 0;
BA_ "VFrameFormat" BO_ 2353206529 1;
BA_ "Description" SG_ 2353206529 CLU_Crc20Val "The data area for CRC calculation is based on the data length (DLC) of the message DB.

The CRC shall be calculated over the entire data block (excluding the CRC bytes) including the user data, alive counter and Data ID



- CRC Polynomial (0x1021) , Initial Value : 0xFFFF, XOR value : 0x0000, Data ID : Message ID + 0xF800 

- The initial value is for CRC calculation and the message should be sent with the calculated result value. 

- The mathematical expression to 16 bit CRC polynomial is given here. G(x) = x16 + x12 + x5 + 1



<For CRC calculation of CAN-FD Msg for HS CAN domain ECUs>



- HS-CAN Messages that routed from CAN-FD domain are using 29 bit Extended CAN ID and splitted into 8 Byte Messages.

(from 1 to 4 Msgs, depending on source CAN-FD Msg’s DLC)

- For splitted CAN-FD Msgs’ CRC calculation, HS CAN ECUs should use source CAN-FD Msg’s original STD ID. 

- The original STD ID can be read from Ext ID’s 4~6th Byte.

Eg. STD 0x6AA : EXT SPLT 0x1A8[6AA]01 / 0x1A8[6AA]02 / 0x1A8[6AA]03 / 0x1A8[6AA]04 

(2~4th splitited Msgs can be omitted depending on source CAN-FD Msg’s DLC)

- Aslo, HS-CAN ECUs should use merged data block (from whole splitted Msg) for CRC calculation.";
BA_ "GenSigStartValue" SG_ 2353206529 CLU_Crc20Val 65535;
BA_ "UserSigValidity" SG_ 2353206529 CLU_Crc20Val 3;
BA_ "Version" SG_ 2353206529 CLU_Crc20Val "21.09.03";
BA_ "Description" SG_ 2353206529 CLU_AlvCnt20Val "For the first transmission request for a data element the counter shall be initialized with 0 and shall be incremented by 1 for every subsequent send request. 

When the counter reaches the maximum value(0xFF), then it shall restart with 0 for the next send request";
BA_ "UserSigValidity" SG_ 2353206529 CLU_AlvCnt20Val 3;
BA_ "Version" SG_ 2353206529 CLU_AlvCnt20Val "21.09.03";
BA_ "Description" SG_ 2353206529 CLU_SndType "This signal is for sound type of Cluster.

The Cluster applied buzzer is can generate only on channel sound

and the Cluster applied speaker can generate multi channel sound.";
BA_ "UserSigValidity" SG_ 2353206529 CLU_SndType 3;
BA_ "Version" SG_ 2353206529 CLU_SndType "19.01.08";
BA_ "Description" SG_ 2353206529 CLU_ClusterUSM "USM application of Cluster

If USM is applied in Cluster, Signal send 0x1";
BA_ "UserSigValidity" SG_ 2353206529 CLU_ClusterUSM 3;
BA_REL_ "GenSigTimeoutTime" BU_SG_REL_ WPC SG_ 2353206529 CLU_ClusterUSM 1500;
BA_REL_ "GenSigTimeoutTime" BU_SG_REL_ WPC2 SG_ 2353206529 CLU_ClusterUSM 1500;
BA_ "Version" SG_ 2353206529 CLU_ClusterUSM "20.06.05";
BA_ "GenMsgSendType" BO_ 2214658049 0;
BA_ "GenMsgCycleTime" BO_ 2214658049 50;
BA_ "GenMsgCycleTimeFast" BO_ 2214658049 0;
BA_ "GenMsgNrOfRepetition" BO_ 2214658049 0;
BA_ "VFrameFormat" BO_ 2214658049 1;
BA_ "Description" SG_ 2214658049 EMS_Crc2Val "The data area for CRC calculation is based on the data length (DLC) of the message DB.

The CRC shall be calculated over the entire data block (excluding the CRC bytes) including the user data, alive counter and Data ID



- CRC Polynomial (0x1021) , Initial Value : 0xFFFF, XOR value : 0x0000, Data ID : Message ID + 0xF800 

- The initial value is for CRC calculation and the message should be sent with the calculated result value. 

- The mathematical expression to 16 bit CRC polynomial is given here. G(x) = x16 + x12 + x5 + 1



<For CRC calculation of CAN-FD Msg for HS CAN domain ECUs>



- HS-CAN Messages that routed from CAN-FD domain are using 29 bit Extended CAN ID and splitted into 8 Byte Messages.

(from 1 to 4 Msgs, depending on source CAN-FD Msg’s DLC)

- For splitted CAN-FD Msgs’ CRC calculation, HS CAN ECUs should use source CAN-FD Msg’s original STD ID. 

- The original STD ID can be read from Ext ID’s 4~6th Byte.

Eg. STD 0x6AA : EXT SPLT 0x1A8[6AA]01 / 0x1A8[6AA]02 / 0x1A8[6AA]03 / 0x1A8[6AA]04 

(2~4th splitited Msgs can be omitted depending on source CAN-FD Msg’s DLC)

- Aslo, HS-CAN ECUs should use merged data block (from whole splitted Msg) for CRC calculation.";
BA_ "GenSigStartValue" SG_ 2214658049 EMS_Crc2Val 65535;
BA_ "UserSigValidity" SG_ 2214658049 EMS_Crc2Val 3;
BA_ "RoutingFactor" SG_ 2214658049 EMS_Crc2Val 5;
BA_ "Version" SG_ 2214658049 EMS_Crc2Val "21.09.03";
BA_ "Description" SG_ 2214658049 EMS_AlvCnt2Val "For the first transmission request for a data element the counter shall be initialized with 0 and shall be incremented by 1 for every subsequent send request. 

When the counter reaches the maximum value(0xFF), then it shall restart with 0 for the next send request";
BA_ "UserSigValidity" SG_ 2214658049 EMS_AlvCnt2Val 3;
BA_ "RoutingFactor" SG_ 2214658049 EMS_AlvCnt2Val 5;
BA_ "Version" SG_ 2214658049 EMS_AlvCnt2Val "21.09.03";
BA_ "Description" SG_ 2214658049 ENG_BrkSwSta "This signal indicates that a brake switch is activated or not. When the brake switch is activated(pressed) its value is 01H otherwise its value is 00H.

If the EMS does not support this signal the value is 02H.



Physical range : 0 ... 100

Conversion : (PH) = (Unsigned)0.002 * (HEX)[%]";
BA_ "GenSigStartValue" SG_ 2214658049 ENG_BrkSwSta 1;
BA_ "UserSigValidity" SG_ 2214658049 ENG_BrkSwSta 3;
BA_ "RoutingFactor" SG_ 2214658049 ENG_BrkSwSta 5;
BA_ "Version" SG_ 2214658049 ENG_BrkSwSta "18.11.00";
BA_ "Description" SG_ 2214658049 ENG_ObdFrzFrmSta "An ECU which detects an OBD fault, requires the EMS to store a set of environmental conditions

(freeze frame). If the EMS follows this requirement it is acknowledged in OBD_FRF_ACK. Also the synchronization of OBD relevant ECUs is made by this signal:



Bit 3-5 is used for freeze frame acknowledgement.

Bit 2 is set, in case a driving cycle has started.

Bit 1 is set, in case a trip is finished.

Bit 0 is set, in case a warm up cycle is finished.



Bit 5, 4, 3 freeze frame status :

0 - No freeze frame stored

1 - Freeze frame requested by EMS

2 - Freeze frame requested by TCU

3 - Freeze frame requested by TCS

4~7 - Reserved";
BA_ "UserSigValidity" SG_ 2214658049 ENG_ObdFrzFrmSta 3;
BA_ "RoutingFactor" SG_ 2214658049 ENG_ObdFrzFrmSta 5;
BA_ "Version" SG_ 2214658049 ENG_ObdFrzFrmSta "17.12.00";
BA_ "Description" SG_ 2214658049 ENG_EngClntTempVal "Engine coolant temperature in EMS sensed via an A/D converter; converted into degrees centigrade (°C).";
BA_ "GenSigStartValue" SG_ 2214658049 ENG_EngClntTempVal 255;
BA_ "UserSigValidity" SG_ 2214658049 ENG_EngClntTempVal 3;
BA_ "RoutingFactor" SG_ 2214658049 ENG_EngClntTempVal 5;
BA_ "Version" SG_ 2214658049 ENG_EngClntTempVal "17.12.00";
BA_ "Description" SG_ 2214658049 ENG_MafCrctVal "The altitude correction factor MAF_FAC_ALTI_MMV is calculated from division of MAF by MAF_SUB_DIAG (=limp home-value for MAF) or from AMP_AD by 1013 mbar in order to take into account different atmospheric pressures at different altitudes.



The Initial-value of 1.0 indicates sea-level, whereas lower values indicate altitude. MAF_FAC_ALTI_MMV is limited to C_MAF_FAC_ALTI_MMV_MIN (=0.6) and C_MAF_FAC_ALTI_MMV_MAX (=1.1) by calibration.";
BA_ "GenSigStartValue" SG_ 2214658049 ENG_MafCrctVal 128;
BA_ "UserSigValidity" SG_ 2214658049 ENG_MafCrctVal 3;
BA_ "RoutingFactor" SG_ 2214658049 ENG_MafCrctVal 5;
BA_ "Version" SG_ 2214658049 ENG_MafCrctVal "17.12.00";
BA_ "Description" SG_ 2214658049 ENG_BattDscnctSta "The signal specifies that ECU has detected a disconnection of the battery since last driving cycle, and therefore has reset the adaptive values and failure memory.

If the EMS does not support this signal the value is 00H



The failure memory erasure is activated only if the calibration C_CONF_NVMY_RST is set to 1 inside the EMS.";
BA_ "UserSigValidity" SG_ 2214658049 ENG_BattDscnctSta 3;
BA_ "RoutingFactor" SG_ 2214658049 ENG_BattDscnctSta 5;
BA_ "Version" SG_ 2214658049 ENG_BattDscnctSta "17.12.00";
BA_ "Description" SG_ 2214658049 OBD_MilConfgVal "The signal specifies the Configuration of the MIL Handling and Failure Memory Management by ECU.";
BA_ "GenSigStartValue" SG_ 2214658049 OBD_MilConfgVal 3;
BA_ "UserSigValidity" SG_ 2214658049 OBD_MilConfgVal 3;
BA_ "RoutingFactor" SG_ 2214658049 OBD_MilConfgVal 5;
BA_ "Version" SG_ 2214658049 OBD_MilConfgVal "17.12.00";
BA_ "NmStationAddress" BU_ SCM 7;
BA_ "NmStationAddress" BU_ HOD 74;
BA_ "Description" SG_ 2214658049 ENG_EngSta "This signal indicates that a status of engine.";
BA_ "UserSigValidity" SG_ 2214658049 ENG_EngSta 3;
BA_ "RoutingFactor" SG_ 2214658049 ENG_EngSta 5;
BA_ "Version" SG_ 2214658049 ENG_EngSta "17.12.00";
BA_ "GenMsgSendType" BO_ 2214659330 0;
BA_ "GenMsgCycleTime" BO_ 2214659330 50;
BA_ "GenMsgCycleTimeFast" BO_ 2214659330 0;
BA_ "GenMsgNrOfRepetition" BO_ 2214659330 0;
BA_ "VFrameFormat" BO_ 2214659330 1;
BA_ "Description" SG_ 2214659330 HEV_FrctTqVal "Friction Loss Torque";
BA_ "UserSigValidity" SG_ 2214659330 HEV_FrctTqVal 3;
BA_ "RoutingFactor" SG_ 2214659330 HEV_FrctTqVal 5;
BA_ "Version" SG_ 2214659330 HEV_FrctTqVal "18.10.07";
BA_ "Description" SG_ 2214659330 HEV_EngSpdVal "Engine Speed";
BA_ "UserSigValidity" SG_ 2214659330 HEV_EngSpdVal 3;
BA_ "RoutingFactor" SG_ 2214659330 HEV_EngSpdVal 5;
BA_ "Version" SG_ 2214659330 HEV_EngSpdVal "18.05.04";
BA_ "Description" SG_ 2214659330 HEV_EngOpSta "Engine Operating State";
BA_ "UserSigValidity" SG_ 2214659330 HEV_EngOpSta 3;
BA_ "RoutingFactor" SG_ 2214659330 HEV_EngOpSta 5;
BA_ "Version" SG_ 2214659330 HEV_EngOpSta "18.05.04";
BA_ "Description" SG_ 2214659330 HEV_IntakeAirTempVal "Intake air temperature";
BA_ "UserSigValidity" SG_ 2214659330 HEV_IntakeAirTempVal 3;
BA_ "RoutingFactor" SG_ 2214659330 HEV_IntakeAirTempVal 5;
BA_ "Version" SG_ 2214659330 HEV_IntakeAirTempVal "18.05.04";
BA_ "Description" SG_ 2214659330 HEV_AccelPdlVal "The signal is a measure of the Accelerator Pedal value.

The accelerator pedal value is determined via 2 pedal sensors, which are connected mechanically to the accelerator pedal. If the EMS-ECU recognizes that the accelerator pedal is not activated, then the value 00 H is carried over on the CAN. If the EMS-ECU detects that the accelerator pedal is fully activated, then 3FE H is carried over on the CAN bus.

If an error is detected on both pedal sensor channels, this is identified by the value 3FFH";
BA_ "UserSigValidity" SG_ 2214659330 HEV_AccelPdlVal 3;
BA_ "RoutingFactor" SG_ 2214659330 HEV_AccelPdlVal 5;
BA_ "Version" SG_ 2214659330 HEV_AccelPdlVal "19.11.11";
BA_ "Description" SG_ 2214659330 HEV_IndTqTar "Indicated Engine (Desired) Torque";
BA_ "UserSigValidity" SG_ 2214659330 HEV_IndTqTar 3;
BA_ "RoutingFactor" SG_ 2214659330 HEV_IndTqTar 5;
BA_ "Version" SG_ 2214659330 HEV_IndTqTar "18.05.04";
BA_ "NmStationAddress" BU_ PSB 65;
BA_ "NmStationAddress" BU_ SLB 27;
BA_ "NmStationAddress" BU_ SGU 62;
BA_ "GenMsgCycleTime" BO_ 1829 0;
BA_ "GenMsgCycleTimeFast" BO_ 1829 0;
BA_ "GenMsgNrOfRepetition" BO_ 1829 0;
BA_ "DiagRequest" BO_ 1829 1;
BA_ "GenMsgILSupport" BO_ 1829 0;
BA_ "TpMessage" BO_ 1829 1;
BA_ "TpTxIndex" BO_ 1829 180;
BA_ "Description" SG_ 1829 GST_WPC_Byte0 "TP Index : 180";
BA_ "UsrSigPurpose" SG_ 1829 GST_WPC_Byte0 3;
BA_ "UserSigValidity" SG_ 1829 GST_WPC_Byte0 0;
BA_REL_ "GenSigTimeoutTime" BU_SG_REL_ WPC SG_ 1829 GST_WPC_Byte0 0;
BA_ "NetworkRequest" SG_ 1829 GST_WPC_Byte0 0;
BA_ "NetworkRequestHoldingTime" SG_ 1829 GST_WPC_Byte0 5000;
BA_ "Version" SG_ 1829 GST_WPC_Byte0 "21.02.04";
BA_ "Description" SG_ 1829 GST_WPC_Byte2 "TP Index : 180";
BA_ "UsrSigPurpose" SG_ 1829 GST_WPC_Byte2 3;
BA_ "UserSigValidity" SG_ 1829 GST_WPC_Byte2 0;
BA_REL_ "GenSigTimeoutTime" BU_SG_REL_ WPC SG_ 1829 GST_WPC_Byte2 0;
BA_ "NetworkRequest" SG_ 1829 GST_WPC_Byte2 0;
BA_ "NetworkRequestHoldingTime" SG_ 1829 GST_WPC_Byte2 5000;
BA_ "Version" SG_ 1829 GST_WPC_Byte2 "21.02.04";
BA_ "Description" SG_ 1829 GST_WPC_Byte3 "TP Index : 180";
BA_ "UsrSigPurpose" SG_ 1829 GST_WPC_Byte3 3;
BA_ "UserSigValidity" SG_ 1829 GST_WPC_Byte3 0;
BA_REL_ "GenSigTimeoutTime" BU_SG_REL_ WPC SG_ 1829 GST_WPC_Byte3 0;
BA_ "NetworkRequest" SG_ 1829 GST_WPC_Byte3 0;
BA_ "NetworkRequestHoldingTime" SG_ 1829 GST_WPC_Byte3 5000;
BA_ "Version" SG_ 1829 GST_WPC_Byte3 "21.02.04";
BA_ "Description" SG_ 1829 GST_WPC_Byte4 "TP Index : 180";
BA_ "UsrSigPurpose" SG_ 1829 GST_WPC_Byte4 3;
BA_ "UserSigValidity" SG_ 1829 GST_WPC_Byte4 0;
BA_REL_ "GenSigTimeoutTime" BU_SG_REL_ WPC SG_ 1829 GST_WPC_Byte4 0;
BA_ "NetworkRequest" SG_ 1829 GST_WPC_Byte4 0;
BA_ "NetworkRequestHoldingTime" SG_ 1829 GST_WPC_Byte4 5000;
BA_ "Version" SG_ 1829 GST_WPC_Byte4 "21.02.04";
BA_ "Description" SG_ 1829 GST_WPC_Byte5 "TP Index : 180";
BA_ "UsrSigPurpose" SG_ 1829 GST_WPC_Byte5 3;
BA_ "UserSigValidity" SG_ 1829 GST_WPC_Byte5 0;
BA_REL_ "GenSigTimeoutTime" BU_SG_REL_ WPC SG_ 1829 GST_WPC_Byte5 0;
BA_ "NetworkRequest" SG_ 1829 GST_WPC_Byte5 0;
BA_ "NetworkRequestHoldingTime" SG_ 1829 GST_WPC_Byte5 5000;
BA_ "Version" SG_ 1829 GST_WPC_Byte5 "21.02.04";
BA_ "Description" SG_ 1829 GST_WPC_Byte6 "TP Index : 180";
BA_ "UsrSigPurpose" SG_ 1829 GST_WPC_Byte6 3;
BA_ "UserSigValidity" SG_ 1829 GST_WPC_Byte6 0;
BA_REL_ "GenSigTimeoutTime" BU_SG_REL_ WPC SG_ 1829 GST_WPC_Byte6 0;
BA_ "NetworkRequest" SG_ 1829 GST_WPC_Byte6 0;
BA_ "NetworkRequestHoldingTime" SG_ 1829 GST_WPC_Byte6 5000;
BA_ "Version" SG_ 1829 GST_WPC_Byte6 "21.02.04";
BA_ "Description" SG_ 1829 GST_WPC_Byte7 "TP Index : 180";
BA_ "UsrSigPurpose" SG_ 1829 GST_WPC_Byte7 3;
BA_ "UserSigValidity" SG_ 1829 GST_WPC_Byte7 0;
BA_REL_ "GenSigTimeoutTime" BU_SG_REL_ WPC SG_ 1829 GST_WPC_Byte7 0;
BA_ "NetworkRequest" SG_ 1829 GST_WPC_Byte7 0;
BA_ "NetworkRequestHoldingTime" SG_ 1829 GST_WPC_Byte7 5000;
BA_ "Version" SG_ 1829 GST_WPC_Byte7 "21.02.04";
BA_ "Description" SG_ 1829 GST_WPC_Byte1 "TP Index : 180";
BA_ "UsrSigPurpose" SG_ 1829 GST_WPC_Byte1 3;
BA_ "UserSigValidity" SG_ 1829 GST_WPC_Byte1 0;
BA_REL_ "GenSigTimeoutTime" BU_SG_REL_ WPC SG_ 1829 GST_WPC_Byte1 0;
BA_ "NetworkRequest" SG_ 1829 GST_WPC_Byte1 0;
BA_ "NetworkRequestHoldingTime" SG_ 1829 GST_WPC_Byte1 5000;
BA_ "Version" SG_ 1829 GST_WPC_Byte1 "21.02.04";
BA_ "GenMsgSendType" BO_ 2210462210 0;
BA_ "GenMsgCycleTime" BO_ 2210462210 50;
BA_ "GenMsgCycleTimeFast" BO_ 2210462210 0;
BA_ "GenMsgNrOfRepetition" BO_ 2210462210 0;
BA_ "VFrameFormat" BO_ 2210462210 1;
BA_ "Description" SG_ 2210462210 HCU_GreenZoneLmpDis "Indicate Green Zone Area";
BA_ "UserSigValidity" SG_ 2210462210 HCU_GreenZoneLmpDis 3;
BA_ "RoutingFactor" SG_ 2210462210 HCU_GreenZoneLmpDis 5;
BA_ "Version" SG_ 2210462210 HCU_GreenZoneLmpDis "18.08.02";
BA_ "Description" SG_ 2210462210 HCU_MILOnReq "HCU sends this signal to turn on the Malfunction Indicator Lamp (MIL).";
BA_ "UserSigValidity" SG_ 2210462210 HCU_MILOnReq 3;
BA_ "RoutingFactor" SG_ 2210462210 HCU_MILOnReq 5;
BA_ "Version" SG_ 2210462210 HCU_MILOnReq "18.08.02";
BA_ "Description" SG_ 2210462210 HCU_PhevAutoModOnSta "PHEV Auto CD CS Mode";
BA_ "UserSigValidity" SG_ 2210462210 HCU_PhevAutoModOnSta 3;
BA_ "RoutingFactor" SG_ 2210462210 HCU_PhevAutoModOnSta 5;
BA_ "Version" SG_ 2210462210 HCU_PhevAutoModOnSta "20.04.02";
BA_ "Description" SG_ 2210462210 HCU_SccDrvOvrdReq "CF_Hcu_Ovrride ※ Start Value : set bit 

Override Drive by driver request during SCC";
BA_ "UserSigValidity" SG_ 2210462210 HCU_SccDrvOvrdReq 3;
BA_ "RoutingFactor" SG_ 2210462210 HCU_SccDrvOvrdReq 5;
BA_ "Version" SG_ 2210462210 HCU_SccDrvOvrdReq "18.08.02";
BA_ "Description" SG_ 2210462210 HCU_SccEnblSta "Smart Cruise Control Enable";
BA_ "UserSigValidity" SG_ 2210462210 HCU_SccEnblSta 3;
BA_ "RoutingFactor" SG_ 2210462210 HCU_SccEnblSta 5;
BA_ "Version" SG_ 2210462210 HCU_SccEnblSta "18.08.02";
BA_ "Description" SG_ 2210462210 HCU_SlwDnSta "HCU determine slowdown state when HCU received slowdown command from TMU";
BA_ "UserSigValidity" SG_ 2210462210 HCU_SlwDnSta 3;
BA_ "RoutingFactor" SG_ 2210462210 HCU_SlwDnSta 5;
BA_ "Version" SG_ 2210462210 HCU_SlwDnSta "18.08.02";
BA_ "Description" SG_ 2210462210 HCU_HcuRdySta "Hybrid Control Unit ready";
BA_ "UserSigValidity" SG_ 2210462210 HCU_HcuRdySta 3;
BA_ "RoutingFactor" SG_ 2210462210 HCU_HcuRdySta 5;
BA_ "Version" SG_ 2210462210 HCU_HcuRdySta "18.08.02";
BA_ "Description" SG_ 2210462210 HCU_SmrtEcoGdDis "This signal indicates whether Smart eco guide displays or not. Display equipment(clutster) follows the direction of the value of this signal.";
BA_ "UserSigValidity" SG_ 2210462210 HCU_SmrtEcoGdDis 3;
BA_ "RoutingFactor" SG_ 2210462210 HCU_SmrtEcoGdDis 5;
BA_ "Version" SG_ 2210462210 HCU_SmrtEcoGdDis "18.08.02";
BA_ "Description" SG_ 2210462210 HCU_SmrtEcoLvlDis "This signal is used on the cluster which displays the current driver's demand for Smart eco guide.";
BA_ "UserSigValidity" SG_ 2210462210 HCU_SmrtEcoLvlDis 3;
BA_ "RoutingFactor" SG_ 2210462210 HCU_SmrtEcoLvlDis 5;
BA_ "Version" SG_ 2210462210 HCU_SmrtEcoLvlDis "18.08.02";
BA_ "Description" SG_ 2210462210 HCU_SmrtEcoRngDis "This signal is used on the cluster which guides a driver to drive the car economically.It is variable regarding driving condition such as the road, traffic and so on.";
BA_ "UserSigValidity" SG_ 2210462210 HCU_SmrtEcoRngDis 3;
BA_ "RoutingFactor" SG_ 2210462210 HCU_SmrtEcoRngDis 5;
BA_ "Version" SG_ 2210462210 HCU_SmrtEcoRngDis "18.08.02";
BA_ "Description" SG_ 2210462210 HCU_SpdLimDeviceActSta "Speed Limiter Device in Activation";
BA_ "UserSigValidity" SG_ 2210462210 HCU_SpdLimDeviceActSta 3;
BA_ "RoutingFactor" SG_ 2210462210 HCU_SpdLimDeviceActSta 5;
BA_ "Version" SG_ 2210462210 HCU_SpdLimDeviceActSta "18.08.02";
BA_ "Description" SG_ 2210462210 HCU_SpdLimDeviceOperSta "Speed Limiter Device in Operation";
BA_ "UserSigValidity" SG_ 2210462210 HCU_SpdLimDeviceOperSta 3;
BA_ "RoutingFactor" SG_ 2210462210 HCU_SpdLimDeviceOperSta 5;
BA_ "Version" SG_ 2210462210 HCU_SpdLimDeviceOperSta "20.05.02";
BA_ "Description" SG_ 2210462210 HCU_HEVRdyDis "This signal indicates whether “READY” lamp on cluster turns on or off.";
BA_ "UserSigValidity" SG_ 2210462210 HCU_HEVRdyDis 3;
BA_ "RoutingFactor" SG_ 2210462210 HCU_HEVRdyDis 5;
BA_ "Version" SG_ 2210462210 HCU_HEVRdyDis "19.09.02";
BA_ "Description" SG_ 2210462210 HCU_SpdLimDeviceVehSpdVal "Speed Limiter Vehicle Speed

This signal should be sent in km/h or MPH according to the “SPEED_UNIT” signal.

SPEED_UNIT = 0 : [km/h]

SPEED_UNIT = 1 : [MPH]";
BA_ "UserSigValidity" SG_ 2210462210 HCU_SpdLimDeviceVehSpdVal 3;
BA_ "RoutingFactor" SG_ 2210462210 HCU_SpdLimDeviceVehSpdVal 5;
BA_ "Version" SG_ 2210462210 HCU_SpdLimDeviceVehSpdVal "21.07.05";
BA_ "Description" SG_ 2210462210 HCU_SrvModSta "Service Test Mode";
BA_ "UserSigValidity" SG_ 2210462210 HCU_SrvModSta 3;
BA_ "RoutingFactor" SG_ 2210462210 HCU_SrvModSta 5;
BA_ "Version" SG_ 2210462210 HCU_SrvModSta "18.08.02";
BA_ "Description" SG_ 2210462210 HCU_StrtInhbt2Sta "Start Inhibit";
BA_ "UserSigValidity" SG_ 2210462210 HCU_StrtInhbt2Sta 3;
BA_ "RoutingFactor" SG_ 2210462210 HCU_StrtInhbt2Sta 5;
BA_ "Version" SG_ 2210462210 HCU_StrtInhbt2Sta "18.08.02";
BA_ "Description" SG_ 2210462210 HCU_StrtInhbtSta "HCU determine Start Inhibit state when HCU received Start Inhibit command from TMU";
BA_ "UserSigValidity" SG_ 2210462210 HCU_StrtInhbtSta 3;
BA_ "RoutingFactor" SG_ 2210462210 HCU_StrtInhbtSta 5;
BA_ "Version" SG_ 2210462210 HCU_StrtInhbtSta "18.08.02";
BA_ "Description" SG_ 2210462210 HCU_SysShtOffReq "CF_Hcu_SysShutOffReq indicates System Shut Off Request or not.";
BA_ "UserSigValidity" SG_ 2210462210 HCU_SysShtOffReq 3;
BA_ "RoutingFactor" SG_ 2210462210 HCU_SysShtOffReq 5;
BA_ "Version" SG_ 2210462210 HCU_SysShtOffReq "18.08.02";
BA_ "Description" SG_ 2210462210 HCU_VehStrtEnblSta "Start";
BA_ "UserSigValidity" SG_ 2210462210 HCU_VehStrtEnblSta 3;
BA_ "RoutingFactor" SG_ 2210462210 HCU_VehStrtEnblSta 5;
BA_ "Version" SG_ 2210462210 HCU_VehStrtEnblSta "18.08.02";
BA_ "Description" SG_ 2210462210 HCU_BrkLmpOnReq "Brake Lamp On Request";
BA_ "UserSigValidity" SG_ 2210462210 HCU_BrkLmpOnReq 3;
BA_ "RoutingFactor" SG_ 2210462210 HCU_BrkLmpOnReq 5;
BA_ "Version" SG_ 2210462210 HCU_BrkLmpOnReq "19.06.02";
BA_ "Description" SG_ 2210462210 HCU_HevRdySta "Hybrid Vehicle Drivable ready";
BA_ "UserSigValidity" SG_ 2210462210 HCU_HevRdySta 3;
BA_ "RoutingFactor" SG_ 2210462210 HCU_HevRdySta 5;
BA_ "Version" SG_ 2210462210 HCU_HevRdySta "18.08.02";
BA_ "Description" SG_ 2210462210 HCU_CcDrvAlrtDis "CC must be disengaged by system or can not be engaged";
BA_ "UserSigValidity" SG_ 2210462210 HCU_CcDrvAlrtDis 3;
BA_ "RoutingFactor" SG_ 2210462210 HCU_CcDrvAlrtDis 5;
BA_ "Version" SG_ 2210462210 HCU_CcDrvAlrtDis "19.12.07";
BA_ "Description" SG_ 2210462210 HCU_SldDrvAlrtDis "SLD must be disengaged by system or cannot be engaged";
BA_ "UserSigValidity" SG_ 2210462210 HCU_SldDrvAlrtDis 3;
BA_ "RoutingFactor" SG_ 2210462210 HCU_SldDrvAlrtDis 5;
BA_ "Version" SG_ 2210462210 HCU_SldDrvAlrtDis "20.01.01";
BA_ "Description" SG_ 2210462210 HCU_LimpOffSta "Limp off the road";
BA_ "UserSigValidity" SG_ 2210462210 HCU_LimpOffSta 3;
BA_ "RoutingFactor" SG_ 2210462210 HCU_LimpOffSta 5;
BA_ "Version" SG_ 2210462210 HCU_LimpOffSta "18.08.02";
BA_ "GenMsgSendType" BO_ 1240 0;
BA_ "Description" SG_ 1240 HU_DistanceUnit "16.12.02_J.H.J. DR Request";
BA_ "GenSigSendType" SG_ 1240 HU_DistanceUnit 4;
BA_ "GenSigStartValue" SG_ 1240 HU_DistanceUnit 3;
BA_ "UserSigValidity" SG_ 1240 HU_DistanceUnit 1;
BA_ "NetworkRequest" SG_ 1240 HU_DistanceUnit 0;
BA_ "Version" SG_ 1240 HU_DistanceUnit "19.02.08";
BA_ "Description" SG_ 1240 HU_ThemeType "This signal indicates current H/Unit GUI theme value. 

 

Detail value -GUI Theme matching table, refer to attachement and ES SPEC";
BA_ "GenSigSendType" SG_ 1240 HU_ThemeType 4;
BA_ "GenSigStartValue" SG_ 1240 HU_ThemeType 15;
BA_ "UserSigValidity" SG_ 1240 HU_ThemeType 0;
BA_REL_ "GenSigTimeoutTime" BU_SG_REL_ ATS SG_ 1240 HU_ThemeType 1500;
BA_REL_ "GenSigTimeoutTime" BU_SG_REL_ BLTN_CAM SG_ 1240 HU_ThemeType 1500;
BA_ "Version" SG_ 1240 HU_ThemeType "20.09.00";
BA_ "Description" SG_ 1240 HU_MicActivity "16.06.02_";
BA_ "GenSigSendType" SG_ 1240 HU_MicActivity 4;
BA_ "GenSigStartValue" SG_ 1240 HU_MicActivity 3;
BA_ "UserSigValidity" SG_ 1240 HU_MicActivity 0;
BA_ "Version" SG_ 1240 HU_MicActivity "19.02.08";
BA_ "Description" SG_ 1240 HU_Scheduled_Setting "Information of scheduled update charge setting

The signal means that scheduled update charaging information send to BMS for BMS SOC control";
BA_ "GenSigSendType" SG_ 1240 HU_Scheduled_Setting 4;
BA_ "UserSigValidity" SG_ 1240 HU_Scheduled_Setting 3;
BA_ "Version" SG_ 1240 HU_Scheduled_Setting "19.05.02";
BA_ "Description" SG_ 1240 AVN_RSPA_ModeSelect "Signal for User's RSPAⅡ mode setting

RSPAⅡ 모드 선택 메뉴 CCP Focus 및 CCP Confirm or Touch 결과";
BA_ "GenSigSendType" SG_ 1240 AVN_RSPA_ModeSelect 4;
BA_ "GenSigStartValue" SG_ 1240 AVN_RSPA_ModeSelect 15;
BA_ "UserSigValidity" SG_ 1240 AVN_RSPA_ModeSelect 0;
BA_ "Version" SG_ 1240 AVN_RSPA_ModeSelect "19.08.08";
BA_ "GenSigSendType" SG_ 1240 CF_HU_GPSFlt 4;
BA_ "GenSigStartValue" SG_ 1240 CF_HU_GPSFlt 2;
BA_ "TimeoutValue" SG_ 1240 CF_HU_GPSFlt "0x2";
BA_ "UserSigValidity" SG_ 1240 CF_HU_GPSFlt 0;
BA_ "Version" SG_ 1240 CF_HU_GPSFlt "20.02.02";
BA_ "GenSigSendType" SG_ 1240 AVN_RSPA_CancelInput 4;
BA_ "UserSigValidity" SG_ 1240 AVN_RSPA_CancelInput 0;
BA_ "Version" SG_ 1240 AVN_RSPA_CancelInput "19.05.03";
BA_ "GenSigSendType" SG_ 1240 AVN_RSPA_Disp_Rdy 4;
BA_ "GenSigStartValue" SG_ 1240 AVN_RSPA_Disp_Rdy 3;
BA_ "UserSigValidity" SG_ 1240 AVN_RSPA_Disp_Rdy 0;
BA_ "Version" SG_ 1240 AVN_RSPA_Disp_Rdy "19.05.03";
BA_ "Description" SG_ 1240 CF_AVN_ProfileIDRValue "18.08.22_This signal is only used in User Profile applied H/Unit";
BA_ "GenSigSendType" SG_ 1240 CF_AVN_ProfileIDRValue 4;
BA_ "GenSigStartValue" SG_ 1240 CF_AVN_ProfileIDRValue 15;
BA_ "UserSigValidity" SG_ 1240 CF_AVN_ProfileIDRValue 0;
BA_REL_ "GenSigTimeoutTime" BU_SG_REL_ WPC SG_ 1240 CF_AVN_ProfileIDRValue 1500;
BA_REL_ "GenSigTimeoutTime" BU_SG_REL_ RWPC SG_ 1240 CF_AVN_ProfileIDRValue 1500;
BA_REL_ "GenSigTimeoutTime" BU_SG_REL_ DPSU SG_ 1240 CF_AVN_ProfileIDRValue 1500;
BA_REL_ "GenSigTimeoutTime" BU_SG_REL_ DLBCU SG_ 1240 CF_AVN_ProfileIDRValue 1500;
BA_REL_ "GenSigTimeoutTime" BU_SG_REL_ RCM SG_ 1240 CF_AVN_ProfileIDRValue 1500;
BA_REL_ "GenSigTimeoutTime" BU_SG_REL_ BLTN_CAM SG_ 1240 CF_AVN_ProfileIDRValue 1500;
BA_REL_ "GenSigTimeoutTime" BU_SG_REL_ SGU SG_ 1240 CF_AVN_ProfileIDRValue 1500;
BA_REL_ "GenSigTimeoutTime" BU_SG_REL_ WPC2 SG_ 1240 CF_AVN_ProfileIDRValue 1500;
BA_ "Version" SG_ 1240 CF_AVN_ProfileIDRValue "18.09.04";
BA_ "Description" SG_ 1240 HazardFromHUSVM "18.08.22_This signal is for the 'Premium AVNT6 && SVM&& ConnectedCarService' vehicle only";
BA_ "GenSigSendType" SG_ 1240 HazardFromHUSVM 4;
BA_ "GenSigStartValue" SG_ 1240 HazardFromHUSVM 3;
BA_ "UserSigValidity" SG_ 1240 HazardFromHUSVM 0;
BA_ "Version" SG_ 1240 HazardFromHUSVM "18.09.04";
BA_ "Description" SG_ 1240 OMUOSMirCtrl "18.08.22_This signal is for the 'Premium AVNT 6.0&&SVM&&ConnectedCarService' vehicle only";
BA_ "GenSigSendType" SG_ 1240 OMUOSMirCtrl 4;
BA_ "GenSigStartValue" SG_ 1240 OMUOSMirCtrl 3;
BA_ "UserSigValidity" SG_ 1240 OMUOSMirCtrl 0;
BA_ "Version" SG_ 1240 OMUOSMirCtrl "18.09.04";
BA_ "Description" SG_ 1240 OTAUIStatus "0x00 : Headunit is booting so, Headunit can't display any state

0x01 : Headunit is normal state, Headunit could display according to CCU command.";
BA_ "GenSigSendType" SG_ 1240 OTAUIStatus 4;
BA_ "UserSigValidity" SG_ 1240 OTAUIStatus 0;
BA_ "Version" SG_ 1240 OTAUIStatus "21.03.02";
BA_ "GenSigSendType" SG_ 1240 C_TeleActiveStatus 4;
BA_ "GenSigStartValue" SG_ 1240 C_TeleActiveStatus 3;
BA_ "UserSigValidity" SG_ 1240 C_TeleActiveStatus 0;
BA_ "Version" SG_ 1240 C_TeleActiveStatus "19.04.06";
BA_ "Description" SG_ 1240 HU_AliveStatus "18.08.22_";
BA_ "GenSigSendType" SG_ 1240 HU_AliveStatus 4;
BA_ "GenSigStartValue" SG_ 1240 HU_AliveStatus 3;
BA_ "UserSigValidity" SG_ 1240 HU_AliveStatus 0;
BA_ "NetworkRequest" SG_ 1240 HU_AliveStatus 0;
BA_ "Version" SG_ 1240 HU_AliveStatus "19.02.08";
BA_ "GenSigSendType" SG_ 1240 HU_RTCCheck 4;
BA_ "GenSigStartValue" SG_ 1240 HU_RTCCheck 3;
BA_ "TimeoutValue" SG_ 1240 HU_RTCCheck "0x3";
BA_ "UserSigValidity" SG_ 1240 HU_RTCCheck 3;
BA_REL_ "GenSigTimeoutTime" BU_SG_REL_ APSU SG_ 1240 HU_RTCCheck 1500;
BA_ "Version" SG_ 1240 HU_RTCCheck "20.02.02";
BA_ "GenMsgCycleTime" BO_ 1195 0;
BA_ "Description" SG_ 1195 CF_AVN_CluWelcomeSnd "16.06.04_";
BA_ "GenSigSendType" SG_ 1195 CF_AVN_CluWelcomeSnd 4;
BA_ "UserSigValidity" SG_ 1195 CF_AVN_CluWelcomeSnd 3;
BA_ "Version" SG_ 1195 CF_AVN_CluWelcomeSnd "18.04.02";
BA_ "Description" SG_ 1195 CF_AVN_CluTransmissionDisp "16.06.04_";
BA_ "GenSigSendType" SG_ 1195 CF_AVN_CluTransmissionDisp 4;
BA_ "UserSigValidity" SG_ 1195 CF_AVN_CluTransmissionDisp 3;
BA_ "Version" SG_ 1195 CF_AVN_CluTransmissionDisp "18.04.02";
BA_ "Description" SG_ 1195 CF_AVN_CluWiperLight "16.06.04_";
BA_ "GenSigSendType" SG_ 1195 CF_AVN_CluWiperLight 4;
BA_ "UserSigValidity" SG_ 1195 CF_AVN_CluWiperLight 3;
BA_ "Version" SG_ 1195 CF_AVN_CluWiperLight "18.04.02";
BA_ "Description" SG_ 1195 CF_AVN_CluRoadInfoGuide "16.06.04_";
BA_ "GenSigSendType" SG_ 1195 CF_AVN_CluRoadInfoGuide 4;
BA_ "UserSigValidity" SG_ 1195 CF_AVN_CluRoadInfoGuide 3;
BA_ "Version" SG_ 1195 CF_AVN_CluRoadInfoGuide "18.04.02";
BA_ "Description" SG_ 1195 CF_AVN_CluUserSettingPeriod "16.06.04_";
BA_ "GenSigSendType" SG_ 1195 CF_AVN_CluUserSettingPeriod 4;
BA_ "GenSigStartValue" SG_ 1195 CF_AVN_CluUserSettingPeriod 127;
BA_ "UserSigValidity" SG_ 1195 CF_AVN_CluUserSettingPeriod 3;
BA_ "Version" SG_ 1195 CF_AVN_CluUserSettingPeriod "19.01.10";
BA_ "Description" SG_ 1195 CF_AVN_CluFuelEconUnit_mi "18.08.08_";
BA_ "GenSigSendType" SG_ 1195 CF_AVN_CluFuelEconUnit_mi 4;
BA_ "UserSigValidity" SG_ 1195 CF_AVN_CluFuelEconUnit_mi 3;
BA_ "Version" SG_ 1195 CF_AVN_CluFuelEconUnit_mi "18.09.04";
BA_ "GenSigSendType" SG_ 1195 CF_AVN_CluFuelEconUnit_km 4;
BA_ "UserSigValidity" SG_ 1195 CF_AVN_CluFuelEconUnit_km 3;
BA_ "Version" SG_ 1195 CF_AVN_CluFuelEconUnit_km "20.08.02";
BA_ "Description" SG_ 1195 CF_AVN_CluUserSettingDistance "16.06.04_";
BA_ "GenSigSendType" SG_ 1195 CF_AVN_CluUserSettingDistance 4;
BA_ "GenSigStartValue" SG_ 1195 CF_AVN_CluUserSettingDistance 131071;
BA_ "UserSigValidity" SG_ 1195 CF_AVN_CluUserSettingDistance 3;
BA_ "Version" SG_ 1195 CF_AVN_CluUserSettingDistance "19.01.10";
BA_ "Description" SG_ 1195 CF_AVN_CluRheostatLvl "18.06.00_";
BA_ "GenSigSendType" SG_ 1195 CF_AVN_CluRheostatLvl 4;
BA_ "GenSigStartValue" SG_ 1195 CF_AVN_CluRheostatLvl 31;
BA_ "UserSigValidity" SG_ 1195 CF_AVN_CluRheostatLvl 3;
BA_ "Version" SG_ 1195 CF_AVN_CluRheostatLvl "18.06.04";
BA_ "Description" SG_ 1195 CF_AVN_EVReset "18.08.08_Request to reset EV Service (0x1 : EV USM Reset)";
BA_ "GenSigSendType" SG_ 1195 CF_AVN_EVReset 4;
BA_ "UserSigValidity" SG_ 1195 CF_AVN_EVReset 7;
BA_ "Version" SG_ 1195 CF_AVN_EVReset "18.09.04";
BA_ "Description" SG_ 1195 CF_AVN_UnitReset "18.08.08_";
BA_ "GenSigSendType" SG_ 1195 CF_AVN_UnitReset 4;
BA_ "UserSigValidity" SG_ 1195 CF_AVN_UnitReset 3;
BA_ "Version" SG_ 1195 CF_AVN_UnitReset "18.09.04";
BA_ "Description" SG_ 1195 CF_AVN_CluServiceReminderReset "16.11.03_";
BA_ "GenSigSendType" SG_ 1195 CF_AVN_CluServiceReminderReset 4;
BA_ "UserSigValidity" SG_ 1195 CF_AVN_CluServiceReminderReset 3;
BA_ "Version" SG_ 1195 CF_AVN_CluServiceReminderReset "18.04.02";
BA_ "GenSigSendType" SG_ 1195 CF_AVN_CluUSMReset 4;
BA_ "UserSigValidity" SG_ 1195 CF_AVN_CluUSMReset 3;
BA_REL_ "GenSigTimeoutTime" BU_SG_REL_ WPC SG_ 1195 CF_AVN_CluUSMReset 0;
BA_REL_ "GenSigTimeoutTime" BU_SG_REL_ RWPC SG_ 1195 CF_AVN_CluUSMReset 0;
BA_REL_ "GenSigTimeoutTime" BU_SG_REL_ SLB SG_ 1195 CF_AVN_CluUSMReset 0;
BA_REL_ "GenSigTimeoutTime" BU_SG_REL_ ARS SG_ 1195 CF_AVN_CluUSMReset 0;
BA_REL_ "GenSigTimeoutTime" BU_SG_REL_ APSU SG_ 1195 CF_AVN_CluUSMReset 0;
BA_REL_ "GenSigTimeoutTime" BU_SG_REL_ RLHV SG_ 1195 CF_AVN_CluUSMReset 0;
BA_REL_ "GenSigTimeoutTime" BU_SG_REL_ RRHV SG_ 1195 CF_AVN_CluUSMReset 0;
BA_REL_ "GenSigTimeoutTime" BU_SG_REL_ SHVU_FR SG_ 1195 CF_AVN_CluUSMReset 0;
BA_REL_ "GenSigTimeoutTime" BU_SG_REL_ SHVU_RR SG_ 1195 CF_AVN_CluUSMReset 0;
BA_REL_ "GenSigTimeoutTime" BU_SG_REL_ DPSU SG_ 1195 CF_AVN_CluUSMReset 0;
BA_REL_ "GenSigTimeoutTime" BU_SG_REL_ DLBCU SG_ 1195 CF_AVN_CluUSMReset 0;
BA_REL_ "GenSigTimeoutTime" BU_SG_REL_ PFSU SG_ 1195 CF_AVN_CluUSMReset 0;
BA_REL_ "GenSigTimeoutTime" BU_SG_REL_ RRPSU SG_ 1195 CF_AVN_CluUSMReset 0;
BA_REL_ "GenSigTimeoutTime" BU_SG_REL_ RLPSU SG_ 1195 CF_AVN_CluUSMReset 0;
BA_REL_ "GenSigTimeoutTime" BU_SG_REL_ ATS SG_ 1195 CF_AVN_CluUSMReset 0;
BA_REL_ "GenSigTimeoutTime" BU_SG_REL_ DSAU SG_ 1195 CF_AVN_CluUSMReset 0;
BA_REL_ "GenSigTimeoutTime" BU_SG_REL_ ASAU SG_ 1195 CF_AVN_CluUSMReset 0;
BA_REL_ "GenSigTimeoutTime" BU_SG_REL_ RCM SG_ 1195 CF_AVN_CluUSMReset 0;
BA_REL_ "GenSigTimeoutTime" BU_SG_REL_ BLTN_CAM SG_ 1195 CF_AVN_CluUSMReset 0;
BA_REL_ "GenSigTimeoutTime" BU_SG_REL_ SGU SG_ 1195 CF_AVN_CluUSMReset 0;
BA_REL_ "GenSigTimeoutTime" BU_SG_REL_ ALBCU SG_ 1195 CF_AVN_CluUSMReset 0;
BA_REL_ "GenSigTimeoutTime" BU_SG_REL_ WPC2 SG_ 1195 CF_AVN_CluUSMReset 0;
BA_ "Version" SG_ 1195 CF_AVN_CluUSMReset "21.01.08";
BA_ "Description" SG_ 1195 CF_AVN_CluServiceReminderSet "16.06.04_";
BA_ "GenSigSendType" SG_ 1195 CF_AVN_CluServiceReminderSet 4;
BA_ "UserSigValidity" SG_ 1195 CF_AVN_CluServiceReminderSet 3;
BA_ "Version" SG_ 1195 CF_AVN_CluServiceReminderSet "18.04.02";
BA_ "GenMsgSendType" BO_ 1041 0;
BA_ "Description" SG_ 1041 ICU_Crc2Val "The data area for CRC calculation is based on the data length (DLC) of the message DB.

The CRC shall be calculated over the entire data block (excluding the CRC bytes) including the user data, alive counter and Data ID 

 

- CRC Polynomial (0x1D) , Initial Value : 0x00, XOR value : 0xFF, Data ID Mode : Both, Data ID : Message ID + 0xF800 

- The initial value is for CRC calculation and the message should be sent with the calculated result value. 

The mathematical expression to 8 bit CRC polynomial is given here. G(x) = x8 + x4 + x3 + x2 + 1";
BA_ "GenSigSendType" SG_ 1041 ICU_Crc2Val 4;
BA_ "GenSigStartValue" SG_ 1041 ICU_Crc2Val 255;
BA_ "UserSigValidity" SG_ 1041 ICU_Crc2Val 0;
BA_ "Version" SG_ 1041 ICU_Crc2Val "18.11.08";
BA_ "Description" SG_ 1041 ICU_MtGearPosRSta "Manual Shift Lever R Switch Status 0x0:Off/0x1:On";
BA_ "GenSigSendType" SG_ 1041 ICU_MtGearPosRSta 4;
BA_ "UserSigValidity" SG_ 1041 ICU_MtGearPosRSta 3;
BA_REL_ "GenSigTimeoutTime" BU_SG_REL_ BLTN_CAM SG_ 1041 ICU_MtGearPosRSta 1500;
BA_ "Version" SG_ 1041 ICU_MtGearPosRSta "21.07.05";
BA_ "Description" SG_ 1041 ICU_AlvCnt2Val "For the first transmission request for a data element the counter shall be initialized with 0 and shall be incremented by 1

for every subsequent send request. When the counter reaches the maximum value(0xE), then it shall restart with 0 for the next send request";
BA_ "GenSigSendType" SG_ 1041 ICU_AlvCnt2Val 4;
BA_ "UserSigValidity" SG_ 1041 ICU_AlvCnt2Val 0;
BA_ "Version" SG_ 1041 ICU_AlvCnt2Val "18.11.08";
BA_ "Description" SG_ 1041 Autocut_DlvryModSta "-(Old)C_SJB_DeliveryMode

-Initial value: 1";
BA_ "GenSigSendType" SG_ 1041 Autocut_DlvryModSta 4;
BA_ "GenSigStartValue" SG_ 1041 Autocut_DlvryModSta 1;
BA_ "UserSigValidity" SG_ 1041 Autocut_DlvryModSta 0;
BA_ "NetworkRequest" SG_ 1041 Autocut_DlvryModSta 0;
BA_ "NetworkRequestHoldingTime" SG_ 1041 Autocut_DlvryModSta 5000;
BA_ "Version" SG_ 1041 Autocut_DlvryModSta "17.12.00";
BA_ "GenSigSendType" SG_ 1041 DoorLock_AsstDrUnLkSta 4;
BA_ "UserSigValidity" SG_ 1041 DoorLock_AsstDrUnLkSta 0;
BA_ "NetworkRequest" SG_ 1041 DoorLock_AsstDrUnLkSta 0;
BA_ "NetworkRequestHoldingTime" SG_ 1041 DoorLock_AsstDrUnLkSta 5000;
BA_ "Version" SG_ 1041 DoorLock_AsstDrUnLkSta "17.12.00";
BA_ "GenSigSendType" SG_ 1041 Warn_DrvDrSwSta 4;
BA_ "UserSigValidity" SG_ 1041 Warn_DrvDrSwSta 0;
BA_REL_ "GenSigTimeoutTime" BU_SG_REL_ WPC SG_ 1041 Warn_DrvDrSwSta 1500;
BA_REL_ "GenSigTimeoutTime" BU_SG_REL_ RWPC SG_ 1041 Warn_DrvDrSwSta 1500;
BA_REL_ "GenSigTimeoutTime" BU_SG_REL_ DPSU SG_ 1041 Warn_DrvDrSwSta 1500;
BA_REL_ "GenSigTimeoutTime" BU_SG_REL_ BLTN_CAM SG_ 1041 Warn_DrvDrSwSta 1500;
BA_REL_ "GenSigTimeoutTime" BU_SG_REL_ WPC2 SG_ 1041 Warn_DrvDrSwSta 1500;
BA_ "NetworkRequest" SG_ 1041 Warn_DrvDrSwSta 0;
BA_ "NetworkRequestHoldingTime" SG_ 1041 Warn_DrvDrSwSta 5000;
BA_ "Version" SG_ 1041 Warn_DrvDrSwSta "17.12.00";
BA_ "GenSigSendType" SG_ 1041 DoorLock_DrvKeyUnLkSwSta 4;
BA_ "UserSigValidity" SG_ 1041 DoorLock_DrvKeyUnLkSwSta 0;
BA_ "NetworkRequest" SG_ 1041 DoorLock_DrvKeyUnLkSwSta 0;
BA_ "NetworkRequestHoldingTime" SG_ 1041 DoorLock_DrvKeyUnLkSwSta 5000;
BA_ "Version" SG_ 1041 DoorLock_DrvKeyUnLkSwSta "17.12.00";
BA_ "GenSigSendType" SG_ 1041 DoorLock_RrLftDrUnLkSta 4;
BA_ "UserSigValidity" SG_ 1041 DoorLock_RrLftDrUnLkSta 0;
BA_ "NetworkRequest" SG_ 1041 DoorLock_RrLftDrUnLkSta 0;
BA_ "NetworkRequestHoldingTime" SG_ 1041 DoorLock_RrLftDrUnLkSta 5000;
BA_ "Version" SG_ 1041 DoorLock_RrLftDrUnLkSta "17.12.00";
BA_ "GenSigSendType" SG_ 1041 DoorLock_RrRtDrUnLkSta 4;
BA_ "UserSigValidity" SG_ 1041 DoorLock_RrRtDrUnLkSta 0;
BA_ "NetworkRequest" SG_ 1041 DoorLock_RrRtDrUnLkSta 0;
BA_ "NetworkRequestHoldingTime" SG_ 1041 DoorLock_RrRtDrUnLkSta 5000;
BA_ "Version" SG_ 1041 DoorLock_RrRtDrUnLkSta "17.12.00";
BA_ "GenSigSendType" SG_ 1041 Warn_AsstDrSwSta 4;
BA_ "UserSigValidity" SG_ 1041 Warn_AsstDrSwSta 0;
BA_REL_ "GenSigTimeoutTime" BU_SG_REL_ WPC SG_ 1041 Warn_AsstDrSwSta 1500;
BA_REL_ "GenSigTimeoutTime" BU_SG_REL_ RWPC SG_ 1041 Warn_AsstDrSwSta 1500;
BA_REL_ "GenSigTimeoutTime" BU_SG_REL_ APSU SG_ 1041 Warn_AsstDrSwSta 1500;
BA_REL_ "GenSigTimeoutTime" BU_SG_REL_ RLPSU SG_ 1041 Warn_AsstDrSwSta 1500;
BA_REL_ "GenSigTimeoutTime" BU_SG_REL_ BLTN_CAM SG_ 1041 Warn_AsstDrSwSta 1500;
BA_REL_ "GenSigTimeoutTime" BU_SG_REL_ ALBCU SG_ 1041 Warn_AsstDrSwSta 1500;
BA_REL_ "GenSigTimeoutTime" BU_SG_REL_ WPC2 SG_ 1041 Warn_AsstDrSwSta 1500;
BA_ "NetworkRequest" SG_ 1041 Warn_AsstDrSwSta 0;
BA_ "NetworkRequestHoldingTime" SG_ 1041 Warn_AsstDrSwSta 5000;
BA_ "Version" SG_ 1041 Warn_AsstDrSwSta "17.12.00";
BA_ "Description" SG_ 1041 Warn_AsstStBltSwSta "-Default value: 0x1 (Belt)



-Initial value: 0x1 (Belt)



-Timeout value: 0x1 (Belt)";
BA_ "GenSigSendType" SG_ 1041 Warn_AsstStBltSwSta 4;
BA_ "GenSigStartValue" SG_ 1041 Warn_AsstStBltSwSta 1;
BA_ "UserSigValidity" SG_ 1041 Warn_AsstStBltSwSta 0;
BA_REL_ "GenSigTimeoutTime" BU_SG_REL_ PSB SG_ 1041 Warn_AsstStBltSwSta 1500;
BA_REL_ "GenSigTimeoutTime" BU_SG_REL_ APSU SG_ 1041 Warn_AsstStBltSwSta 1500;
BA_REL_ "GenSigTimeoutTime" BU_SG_REL_ RLPSU SG_ 1041 Warn_AsstStBltSwSta 1500;
BA_REL_ "GenSigTimeoutTime" BU_SG_REL_ ASAU SG_ 1041 Warn_AsstStBltSwSta 1500;
BA_REL_ "GenSigTimeoutTime" BU_SG_REL_ ALBCU SG_ 1041 Warn_AsstStBltSwSta 1500;
BA_ "NetworkRequest" SG_ 1041 Warn_AsstStBltSwSta 0;
BA_ "NetworkRequestHoldingTime" SG_ 1041 Warn_AsstStBltSwSta 5000;
BA_ "Version" SG_ 1041 Warn_AsstStBltSwSta "17.12.00";
BA_ "GenSigSendType" SG_ 1041 Warn_BrkFldSwSta 4;
BA_ "UserSigValidity" SG_ 1041 Warn_BrkFldSwSta 0;
BA_ "NetworkRequest" SG_ 1041 Warn_BrkFldSwSta 0;
BA_ "NetworkRequestHoldingTime" SG_ 1041 Warn_BrkFldSwSta 5000;
BA_ "Version" SG_ 1041 Warn_BrkFldSwSta "17.12.00";
BA_ "GenSigSendType" SG_ 1041 DoorLock_DrvKeyLkSwSta 4;
BA_ "UserSigValidity" SG_ 1041 DoorLock_DrvKeyLkSwSta 0;
BA_ "NetworkRequest" SG_ 1041 DoorLock_DrvKeyLkSwSta 0;
BA_ "NetworkRequestHoldingTime" SG_ 1041 DoorLock_DrvKeyLkSwSta 5000;
BA_ "Version" SG_ 1041 DoorLock_DrvKeyLkSwSta "17.12.00";
BA_ "GenSigSendType" SG_ 1041 Warn_DrvStBltSwSta 4;
BA_ "UserSigValidity" SG_ 1041 Warn_DrvStBltSwSta 0;
BA_REL_ "GenSigTimeoutTime" BU_SG_REL_ PSB SG_ 1041 Warn_DrvStBltSwSta 1500;
BA_REL_ "GenSigTimeoutTime" BU_SG_REL_ DPSU SG_ 1041 Warn_DrvStBltSwSta 1500;
BA_REL_ "GenSigTimeoutTime" BU_SG_REL_ DLBCU SG_ 1041 Warn_DrvStBltSwSta 1500;
BA_REL_ "GenSigTimeoutTime" BU_SG_REL_ ATS SG_ 1041 Warn_DrvStBltSwSta 1500;
BA_REL_ "GenSigTimeoutTime" BU_SG_REL_ DSAU SG_ 1041 Warn_DrvStBltSwSta 1500;
BA_REL_ "GenSigTimeoutTime" BU_SG_REL_ ASAU SG_ 1041 Warn_DrvStBltSwSta 1500;
BA_ "NetworkRequest" SG_ 1041 Warn_DrvStBltSwSta 0;
BA_ "NetworkRequestHoldingTime" SG_ 1041 Warn_DrvStBltSwSta 5000;
BA_ "Version" SG_ 1041 Warn_DrvStBltSwSta "17.12.00";
BA_ "GenSigSendType" SG_ 1041 Warn_HoodSwSta 4;
BA_ "UserSigValidity" SG_ 1041 Warn_HoodSwSta 0;
BA_REL_ "GenSigTimeoutTime" BU_SG_REL_ BLTN_CAM SG_ 1041 Warn_HoodSwSta 1500;
BA_ "NetworkRequest" SG_ 1041 Warn_HoodSwSta 0;
BA_ "NetworkRequestHoldingTime" SG_ 1041 Warn_HoodSwSta 5000;
BA_ "Version" SG_ 1041 Warn_HoodSwSta "17.12.00";
BA_ "Description" SG_ 1041 Warn_PassStOccSta "Passenger Seated State







-Default value: 0x0 (미탑승)



-Initial value: 0x0 (미탑승)



-Timeout value: 0x0 (미탑승)";
BA_ "GenSigSendType" SG_ 1041 Warn_PassStOccSta 4;
BA_ "UserSigValidity" SG_ 1041 Warn_PassStOccSta 0;
BA_REL_ "GenSigTimeoutTime" BU_SG_REL_ APSU SG_ 1041 Warn_PassStOccSta 1500;
BA_ "NetworkRequest" SG_ 1041 Warn_PassStOccSta 0;
BA_ "NetworkRequestHoldingTime" SG_ 1041 Warn_PassStOccSta 5000;
BA_ "Version" SG_ 1041 Warn_PassStOccSta "17.12.00";
BA_ "GenSigSendType" SG_ 1041 Warn_PrkngBrkSwSta 4;
BA_ "UserSigValidity" SG_ 1041 Warn_PrkngBrkSwSta 0;
BA_REL_ "GenSigTimeoutTime" BU_SG_REL_ APSU SG_ 1041 Warn_PrkngBrkSwSta 1500;
BA_REL_ "GenSigTimeoutTime" BU_SG_REL_ RLHV SG_ 1041 Warn_PrkngBrkSwSta 1500;
BA_REL_ "GenSigTimeoutTime" BU_SG_REL_ RRHV SG_ 1041 Warn_PrkngBrkSwSta 1500;
BA_REL_ "GenSigTimeoutTime" BU_SG_REL_ PFSU SG_ 1041 Warn_PrkngBrkSwSta 1500;
BA_REL_ "GenSigTimeoutTime" BU_SG_REL_ RRPSU SG_ 1041 Warn_PrkngBrkSwSta 1500;
BA_REL_ "GenSigTimeoutTime" BU_SG_REL_ RLPSU SG_ 1041 Warn_PrkngBrkSwSta 1500;
BA_ "NetworkRequest" SG_ 1041 Warn_PrkngBrkSwSta 0;
BA_ "NetworkRequestHoldingTime" SG_ 1041 Warn_PrkngBrkSwSta 5000;
BA_ "Version" SG_ 1041 Warn_PrkngBrkSwSta "17.12.00";
BA_ "GenSigSendType" SG_ 1041 Warn_RrCtrStBltSwSta 4;
BA_ "UserSigValidity" SG_ 1041 Warn_RrCtrStBltSwSta 0;
BA_REL_ "GenSigTimeoutTime" BU_SG_REL_ PSB SG_ 1041 Warn_RrCtrStBltSwSta 1500;
BA_ "NetworkRequest" SG_ 1041 Warn_RrCtrStBltSwSta 0;
BA_ "NetworkRequestHoldingTime" SG_ 1041 Warn_RrCtrStBltSwSta 5000;
BA_ "Version" SG_ 1041 Warn_RrCtrStBltSwSta "17.12.00";
BA_ "GenSigSendType" SG_ 1041 Warn_RrLftDrSwSta 4;
BA_ "UserSigValidity" SG_ 1041 Warn_RrLftDrSwSta 0;
BA_REL_ "GenSigTimeoutTime" BU_SG_REL_ WPC SG_ 1041 Warn_RrLftDrSwSta 1500;
BA_REL_ "GenSigTimeoutTime" BU_SG_REL_ RWPC SG_ 1041 Warn_RrLftDrSwSta 1500;
BA_REL_ "GenSigTimeoutTime" BU_SG_REL_ APSU SG_ 1041 Warn_RrLftDrSwSta 1500;
BA_REL_ "GenSigTimeoutTime" BU_SG_REL_ RLHV SG_ 1041 Warn_RrLftDrSwSta 1500;
BA_REL_ "GenSigTimeoutTime" BU_SG_REL_ RRPSU SG_ 1041 Warn_RrLftDrSwSta 1500;
BA_REL_ "GenSigTimeoutTime" BU_SG_REL_ RLPSU SG_ 1041 Warn_RrLftDrSwSta 1500;
BA_REL_ "GenSigTimeoutTime" BU_SG_REL_ BLTN_CAM SG_ 1041 Warn_RrLftDrSwSta 1500;
BA_REL_ "GenSigTimeoutTime" BU_SG_REL_ WPC2 SG_ 1041 Warn_RrLftDrSwSta 1500;
BA_ "NetworkRequest" SG_ 1041 Warn_RrLftDrSwSta 0;
BA_ "NetworkRequestHoldingTime" SG_ 1041 Warn_RrLftDrSwSta 5000;
BA_ "Version" SG_ 1041 Warn_RrLftDrSwSta "17.12.00";
BA_ "GenSigSendType" SG_ 1041 Warn_RrLftStBltSwSta 4;
BA_ "UserSigValidity" SG_ 1041 Warn_RrLftStBltSwSta 0;
BA_REL_ "GenSigTimeoutTime" BU_SG_REL_ PSB SG_ 1041 Warn_RrLftStBltSwSta 1500;
BA_REL_ "GenSigTimeoutTime" BU_SG_REL_ APSU SG_ 1041 Warn_RrLftStBltSwSta 1500;
BA_REL_ "GenSigTimeoutTime" BU_SG_REL_ DPSU SG_ 1041 Warn_RrLftStBltSwSta 1500;
BA_ "NetworkRequest" SG_ 1041 Warn_RrLftStBltSwSta 0;
BA_ "NetworkRequestHoldingTime" SG_ 1041 Warn_RrLftStBltSwSta 5000;
BA_ "Version" SG_ 1041 Warn_RrLftStBltSwSta "17.12.00";
BA_ "GenSigSendType" SG_ 1041 Warn_RrRtDrSwSta 4;
BA_ "UserSigValidity" SG_ 1041 Warn_RrRtDrSwSta 0;
BA_REL_ "GenSigTimeoutTime" BU_SG_REL_ WPC SG_ 1041 Warn_RrRtDrSwSta 1500;
BA_REL_ "GenSigTimeoutTime" BU_SG_REL_ RWPC SG_ 1041 Warn_RrRtDrSwSta 1500;
BA_REL_ "GenSigTimeoutTime" BU_SG_REL_ APSU SG_ 1041 Warn_RrRtDrSwSta 1500;
BA_REL_ "GenSigTimeoutTime" BU_SG_REL_ RRHV SG_ 1041 Warn_RrRtDrSwSta 1500;
BA_REL_ "GenSigTimeoutTime" BU_SG_REL_ RRPSU SG_ 1041 Warn_RrRtDrSwSta 1500;
BA_REL_ "GenSigTimeoutTime" BU_SG_REL_ RLPSU SG_ 1041 Warn_RrRtDrSwSta 1500;
BA_REL_ "GenSigTimeoutTime" BU_SG_REL_ BLTN_CAM SG_ 1041 Warn_RrRtDrSwSta 1500;
BA_REL_ "GenSigTimeoutTime" BU_SG_REL_ WPC2 SG_ 1041 Warn_RrRtDrSwSta 1500;
BA_ "NetworkRequest" SG_ 1041 Warn_RrRtDrSwSta 0;
BA_ "NetworkRequestHoldingTime" SG_ 1041 Warn_RrRtDrSwSta 5000;
BA_ "Version" SG_ 1041 Warn_RrRtDrSwSta "17.12.00";
BA_ "GenSigSendType" SG_ 1041 Warn_RrRtStBltSwSta 4;
BA_ "UserSigValidity" SG_ 1041 Warn_RrRtStBltSwSta 0;
BA_REL_ "GenSigTimeoutTime" BU_SG_REL_ PSB SG_ 1041 Warn_RrRtStBltSwSta 1500;
BA_REL_ "GenSigTimeoutTime" BU_SG_REL_ APSU SG_ 1041 Warn_RrRtStBltSwSta 1500;
BA_REL_ "GenSigTimeoutTime" BU_SG_REL_ DPSU SG_ 1041 Warn_RrRtStBltSwSta 1500;
BA_ "NetworkRequest" SG_ 1041 Warn_RrRtStBltSwSta 0;
BA_ "NetworkRequestHoldingTime" SG_ 1041 Warn_RrRtStBltSwSta 5000;
BA_ "Version" SG_ 1041 Warn_RrRtStBltSwSta "17.12.00";
BA_ "Description" SG_ 1041 Warn_HoodSwMemorySta "Hood swtich open->close information(memory)



This signal is for oil level warning lamp reset In case hood open->close when IG-OFF, 0x01 sent for 5 sec at next IG-ON";
BA_ "GenSigSendType" SG_ 1041 Warn_HoodSwMemorySta 4;
BA_ "UserSigValidity" SG_ 1041 Warn_HoodSwMemorySta 3;
BA_ "NetworkRequest" SG_ 1041 Warn_HoodSwMemorySta 0;
BA_ "NetworkRequestHoldingTime" SG_ 1041 Warn_HoodSwMemorySta 5000;
BA_ "Version" SG_ 1041 Warn_HoodSwMemorySta "17.12.00";
BA_ "Description" SG_ 1041 Warn_WshrFldSwSta "Washer Fluid Switch Signal

This signal indicates Washer Fluid Switch Signal

0x0:Off/0x1:On";
BA_ "GenSigSendType" SG_ 1041 Warn_WshrFldSwSta 4;
BA_ "UserSigValidity" SG_ 1041 Warn_WshrFldSwSta 3;
BA_ "NetworkRequest" SG_ 1041 Warn_WshrFldSwSta 0;
BA_ "NetworkRequestHoldingTime" SG_ 1041 Warn_WshrFldSwSta 5000;
BA_ "Version" SG_ 1041 Warn_WshrFldSwSta "21.07.05";
BA_ "Description" SG_ 1041 ICU_Haptic_OPT "Steering Wheel Haptic Warning Option Infomation (From ICU)";
BA_ "GenSigSendType" SG_ 1041 ICU_Haptic_OPT 4;
BA_ "UserSigValidity" SG_ 1041 ICU_Haptic_OPT 0;
BA_ "NetworkRequest" SG_ 1041 ICU_Haptic_OPT 0;
BA_ "NetworkRequestHoldingTime" SG_ 1041 ICU_Haptic_OPT 5000;
BA_ "Version" SG_ 1041 ICU_Haptic_OPT "18.07.07";
BA_ "GenMsgSendType" BO_ 1093 0;
BA_ "Description" SG_ 1093 SMK_Crc6Val "The data area for CRC calculation is based on the data length (DLC) of the message DB.

The CRC shall be calculated over the entire data block (excluding the CRC bytes) including the user data, alive counter and Data ID 

 

- CRC Polynomial (0x1D) , Initial Value : 0x00, XOR value : 0xFF, Data ID Mode : Both, Data ID : Message ID + 0xF800 

- The initial value is for CRC calculation and the message should be sent with the calculated result value. 

The mathematical expression to 8 bit CRC polynomial is given here. G(x) = x8 + x4 + x3 + x2 + 1";
BA_ "GenSigSendType" SG_ 1093 SMK_Crc6Val 4;
BA_ "UserSigValidity" SG_ 1093 SMK_Crc6Val 0;
BA_ "Version" SG_ 1093 SMK_Crc6Val "21.09.03";
BA_ "Description" SG_ 1093 SMK_AlvCnt6Val "For the first transmission request for a data element the counter shall be initialized with 0 and shall be incremented by 1

for every subsequent send request. When the counter reaches the maximum value(0xE), then it shall restart with 0 for the next send request";
BA_ "GenSigSendType" SG_ 1093 SMK_AlvCnt6Val 4;
BA_ "UserSigValidity" SG_ 1093 SMK_AlvCnt6Val 0;
BA_ "Version" SG_ 1093 SMK_AlvCnt6Val "21.09.03";
BA_ "Description" SG_ 1093 Lamp_HzrdBlnkngSta "Hazard Signal for Hands Free Trunk/Tailgate";
BA_ "GenSigSendType" SG_ 1093 Lamp_HzrdBlnkngSta 4;
BA_ "UserSigValidity" SG_ 1093 Lamp_HzrdBlnkngSta 0;
BA_ "Version" SG_ 1093 Lamp_HzrdBlnkngSta "17.12.00";
BA_ "Description" SG_ 1093 RSPA_LearntSta "IBU RSPA learnt state signal.

This signal is used only for ADAS_PRK.";
BA_ "GenSigSendType" SG_ 1093 RSPA_LearntSta 4;
BA_ "UserSigValidity" SG_ 1093 RSPA_LearntSta 0;
BA_ "Version" SG_ 1093 RSPA_LearntSta "19.07.01";
BA_ "Description" SG_ 1093 Lamp_SmrtWlcmLtOnReq "Smart Key welcome light on request.";
BA_ "GenSigSendType" SG_ 1093 Lamp_SmrtWlcmLtOnReq 4;
BA_ "UserSigValidity" SG_ 1093 Lamp_SmrtWlcmLtOnReq 0;
BA_ "NetworkRequest" SG_ 1093 Lamp_SmrtWlcmLtOnReq 0;
BA_ "NetworkRequestHoldingTime" SG_ 1093 Lamp_SmrtWlcmLtOnReq 5000;
BA_ "Version" SG_ 1093 Lamp_SmrtWlcmLtOnReq "17.12.00";
BA_ "Description" SG_ 1093 Fob_BattStaInfo "Received Fob Battery Status for Telematics Vehicle Information Service";
BA_ "GenSigSendType" SG_ 1093 Fob_BattStaInfo 4;
BA_ "UserSigValidity" SG_ 1093 Fob_BattStaInfo 0;
BA_ "Version" SG_ 1093 Fob_BattStaInfo "17.12.00";
BA_ "Description" SG_ 1093 Fob_FoundDrvWlcmArea "This Signal Indicates direction of user approach to vehicle.

If User Approach to vehicle Driver direction, This signal set On.";
BA_ "GenSigSendType" SG_ 1093 Fob_FoundDrvWlcmArea 4;
BA_ "UserSigValidity" SG_ 1093 Fob_FoundDrvWlcmArea 0;
BA_ "Version" SG_ 1093 Fob_FoundDrvWlcmArea "17.12.00";
BA_ "Description" SG_ 1093 Fob_FoundAsstWlcmArea "This Signal Indicates direction of user approach to vehicle.

If User Approach to vehicle Assistant direction, This signal set On.";
BA_ "GenSigSendType" SG_ 1093 Fob_FoundAsstWlcmArea 4;
BA_ "UserSigValidity" SG_ 1093 Fob_FoundAsstWlcmArea 0;
BA_ "Version" SG_ 1093 Fob_FoundAsstWlcmArea "17.12.00";
BA_ "Description" SG_ 1093 Fob_FoundExtrnlArea "Exterior FOB Position recognize";
BA_ "GenSigSendType" SG_ 1093 Fob_FoundExtrnlArea 4;
BA_ "UserSigValidity" SG_ 1093 Fob_FoundExtrnlArea 0;
BA_ "Version" SG_ 1093 Fob_FoundExtrnlArea "17.12.00";
BA_ "Description" SG_ 1093 Fob_FoundIntArea "Interior FOB Position recognize";
BA_ "GenSigSendType" SG_ 1093 Fob_FoundIntArea 4;
BA_ "UserSigValidity" SG_ 1093 Fob_FoundIntArea 0;
BA_ "Version" SG_ 1093 Fob_FoundIntArea "17.12.00";
BA_ "Description" SG_ 1093 Fob_LearntSta "Fob key registration status information";
BA_ "GenSigSendType" SG_ 1093 Fob_LearntSta 4;
BA_ "GenSigStartValue" SG_ 1093 Fob_LearntSta 1;
BA_ "UserSigValidity" SG_ 1093 Fob_LearntSta 0;
BA_ "NetworkRequest" SG_ 1093 Fob_LearntSta 0;
BA_ "NetworkRequestHoldingTime" SG_ 1093 Fob_LearntSta 5000;
BA_ "Version" SG_ 1093 Fob_LearntSta "17.12.00";
BA_ "Description" SG_ 1093 RSPA_RFSigErrSta "Error status of RKE_BtnReq signal.



If RF frame data from FOB defferent with CAN signal data(RKE_BtnReq), 

RSPA_RFSigErrSta signal send 0x1 Signal Invalid.";
BA_ "GenSigSendType" SG_ 1093 RSPA_RFSigErrSta 4;
BA_ "UserSigValidity" SG_ 1093 RSPA_RFSigErrSta 0;
BA_ "NetworkRequest" SG_ 1093 RSPA_RFSigErrSta 0;
BA_ "NetworkRequestHoldingTime" SG_ 1093 RSPA_RFSigErrSta 5000;
BA_ "Version" SG_ 1093 RSPA_RFSigErrSta "18.05.02";
BA_ "Description" SG_ 1093 RSPA_CanErrSta "Error status of RSPA control signals.(From ADAS_PRK)";
BA_ "GenSigSendType" SG_ 1093 RSPA_CanErrSta 4;
BA_ "UserSigValidity" SG_ 1093 RSPA_CanErrSta 0;
BA_ "Version" SG_ 1093 RSPA_CanErrSta "18.05.02";
BA_ "Description" SG_ 1093 LFAnt_FltSta "This signal represents LF ANT's Error condition. 

If one of LF ANT has Fault(ex, timeout), signal has fault value.";
BA_ "GenSigSendType" SG_ 1093 LFAnt_FltSta 4;
BA_ "UserSigValidity" SG_ 1093 LFAnt_FltSta 0;
BA_ "Version" SG_ 1093 LFAnt_FltSta "17.12.00";
BA_ "Description" SG_ 1093 LFAnt_SrchSta "SMK LF Searching Status



This signal indicates that SMK operates LF searching for finding FOB.

WPC uses this signal for suspending wirless charging.";
BA_ "GenSigSendType" SG_ 1093 LFAnt_SrchSta 4;
BA_ "UserSigValidity" SG_ 1093 LFAnt_SrchSta 0;
BA_REL_ "GenSigTimeoutTime" BU_SG_REL_ WPC SG_ 1093 LFAnt_SrchSta 1500;
BA_REL_ "GenSigTimeoutTime" BU_SG_REL_ RWPC SG_ 1093 LFAnt_SrchSta 1500;
BA_REL_ "GenSigTimeoutTime" BU_SG_REL_ WPC2 SG_ 1093 LFAnt_SrchSta 1500;
BA_ "Version" SG_ 1093 LFAnt_SrchSta "17.12.00";
BA_ "Description" SG_ 1093 RSPA_ModSta_SMK "State of RSPA system operate";
BA_ "GenSigSendType" SG_ 1093 RSPA_ModSta_SMK 4;
BA_ "UserSigValidity" SG_ 1093 RSPA_ModSta_SMK 0;
BA_REL_ "GenSigTimeoutTime" BU_SG_REL_ DPSU SG_ 1093 RSPA_ModSta_SMK 1500;
BA_ "Version" SG_ 1093 RSPA_ModSta_SMK "19.03.08";
BA_ "Description" SG_ 1093 RSPA_FobBattSta "FOB Battery's Low Battery(discharge) state.

Low Battery condition is same with 'C_KeyBATDischargeWarn' Signal";
BA_ "GenSigSendType" SG_ 1093 RSPA_FobBattSta 4;
BA_ "UserSigValidity" SG_ 1093 RSPA_FobBattSta 0;
BA_ "Version" SG_ 1093 RSPA_FobBattSta "17.12.00";
BA_ "Description" SG_ 1093 Fob_BtnReleasedSta "this signal indicate fob butten released state during RSPA mode. 

##2G##IBU##SMK18##C_FobButtenReleased";
BA_ "GenSigSendType" SG_ 1093 Fob_BtnReleasedSta 4;
BA_ "UserSigValidity" SG_ 1093 Fob_BtnReleasedSta 0;
BA_ "Version" SG_ 1093 Fob_BtnReleasedSta "18.10.09";
BA_ "GenSigSendType" SG_ 1093 USM_SmrtTrnkTlgtModSta 4;
BA_ "UserSigValidity" SG_ 1093 USM_SmrtTrnkTlgtModSta 0;
BA_ "Version" SG_ 1093 USM_SmrtTrnkTlgtModSta "18.05.01";
BA_ "Description" SG_ 1093 USM_WALModSta "Current USM Setting value of Walk Away Lock(WAL) mode";
BA_ "GenSigSendType" SG_ 1093 USM_WALModSta 4;
BA_ "UserSigValidity" SG_ 1093 USM_WALModSta 0;
BA_ "Version" SG_ 1093 USM_WALModSta "17.12.00";
BA_ "Description" SG_ 1093 Fob_FoundWlcmArea "This signal indicates that there is Fob around the welcome area. 

 -to inform the door handle (Lock/Unlock touch sensor)";
BA_ "GenSigSendType" SG_ 1093 Fob_FoundWlcmArea 4;
BA_ "UserSigValidity" SG_ 1093 Fob_FoundWlcmArea 0;
BA_ "Version" SG_ 1093 Fob_FoundWlcmArea "19.03.09";
BA_ "GenMsgSendType" BO_ 830 0;
BA_ "Description" SG_ 830 USM_CmdWPC2Sta "USM request value of WPC2";
BA_ "GenSigSendType" SG_ 830 USM_CmdWPC2Sta 4;
BA_ "UserSigValidity" SG_ 830 USM_CmdWPC2Sta 0;
BA_REL_ "GenSigTimeoutTime" BU_SG_REL_ CGW_CCU SG_ 830 USM_CmdWPC2Sta 1500;
BA_ "NetworkRequest" SG_ 830 USM_CmdWPC2Sta 0;
BA_ "NetworkRequestHoldingTime" SG_ 830 USM_CmdWPC2Sta 5000;
BA_ "Version" SG_ 830 USM_CmdWPC2Sta "22.02.06";
BA_ "Description" SG_ 830 WPC2_OptSta "Apply dual WPC information	2";
BA_ "GenSigSendType" SG_ 830 WPC2_OptSta 4;
BA_ "UserSigValidity" SG_ 830 WPC2_OptSta 0;
BA_REL_ "GenSigTimeoutTime" BU_SG_REL_ CGW_CCU SG_ 830 WPC2_OptSta 1500;
BA_ "NetworkRequest" SG_ 830 WPC2_OptSta 0;
BA_ "NetworkRequestHoldingTime" SG_ 830 WPC2_OptSta 5000;
BA_ "Version" SG_ 830 WPC2_OptSta "22.03.02";
BA_ "Description" SG_ 830 WPC2_SWVerMajor1 "Indicate the WPC2 software version as follows:

- The software version is displayed in three digits.

- The Major and Minor digits are separated by '.'

- Signal values are transmitted to ASCII codes.



※ Example

WPC2_SWVerMajor1 : 0x41 (HEX) -> ASCII CODE : 'A' 

WPC2_SWVerMinor1 : 0x30 (HEX) -> ASCII CODE : '0'

WPC2_SWVerMinor2 : 0x33 (HEX) -> ASCII CODE : '3'

=> WPC2 S/W Ver is displayed 'A.03'";
BA_ "GenSigSendType" SG_ 830 WPC2_SWVerMajor1 4;
BA_ "UserSigValidity" SG_ 830 WPC2_SWVerMajor1 0;
BA_REL_ "GenSigTimeoutTime" BU_SG_REL_ CGW_CCU SG_ 830 WPC2_SWVerMajor1 1500;
BA_ "Version" SG_ 830 WPC2_SWVerMajor1 "22.02.06";
BA_ "Description" SG_ 830 WPC2_PhnLftWrngSta "Warning by WPC2 for User (Phone left in vehicle)";
BA_ "GenSigSendType" SG_ 830 WPC2_PhnLftWrngSta 4;
BA_ "UserSigValidity" SG_ 830 WPC2_PhnLftWrngSta 0;
BA_REL_ "GenSigTimeoutTime" BU_SG_REL_ CGW_CCU SG_ 830 WPC2_PhnLftWrngSta 1500;
BA_ "NetworkRequest" SG_ 830 WPC2_PhnLftWrngSta 0;
BA_ "NetworkRequestHoldingTime" SG_ 830 WPC2_PhnLftWrngSta 5000;
BA_ "Version" SG_ 830 WPC2_PhnLftWrngSta "22.02.06";
BA_ "Description" SG_ 830 WPC2_SWVerMinor1 "Indicate the WPC2 software version as follows:

- The software version is displayed in three digits.

- The Major and Minor digits are separated by '.'

- Signal values are transmitted to ASCII codes.



※ Example

WPC2_SWVerMajor1 : 0x41 (HEX) -> ASCII CODE : 'A' 

WPC2_SWVerMinor1 : 0x30 (HEX) -> ASCII CODE : '0'

WPC2_SWVerMinor2 : 0x33 (HEX) -> ASCII CODE : '3'

=> WPC2 S/W Ver is displayed 'A.03'";
BA_ "GenSigSendType" SG_ 830 WPC2_SWVerMinor1 4;
BA_ "UserSigValidity" SG_ 830 WPC2_SWVerMinor1 0;
BA_REL_ "GenSigTimeoutTime" BU_SG_REL_ CGW_CCU SG_ 830 WPC2_SWVerMinor1 1500;
BA_ "Version" SG_ 830 WPC2_SWVerMinor1 "22.02.06";
BA_ "Description" SG_ 830 WPC2_SWVerMinor2 "Indicate the WPC2 software version as follows:

- The software version is displayed in three digits.

- The Major and Minor digits are separated by '.'

- Signal values are transmitted to ASCII codes.



※ Example

WPC2_SWVerMajor1 : 0x41 (HEX) -> ASCII CODE : 'A' 

WPC2_SWVerMinor1 : 0x30 (HEX) -> ASCII CODE : '0'

WPC2_SWVerMinor2 : 0x33 (HEX) -> ASCII CODE : '3'

=> WPC2 S/W Ver is displayed 'A.03'";
BA_ "GenSigSendType" SG_ 830 WPC2_SWVerMinor2 4;
BA_ "UserSigValidity" SG_ 830 WPC2_SWVerMinor2 0;
BA_REL_ "GenSigTimeoutTime" BU_SG_REL_ CGW_CCU SG_ 830 WPC2_SWVerMinor2 1500;
BA_ "Version" SG_ 830 WPC2_SWVerMinor2 "22.02.06";
BA_ "Description" SG_ 830 WPC2_IndSyncVal "WPC IND ANIMATION SYNC SIGNAL";
BA_ "GenSigSendType" SG_ 830 WPC2_IndSyncVal 4;
BA_ "TimeoutValue" SG_ 830 WPC2_IndSyncVal "0x0";
BA_ "UserSigValidity" SG_ 830 WPC2_IndSyncVal 3;
BA_REL_ "GenSigTimeoutTime" BU_SG_REL_ RWPC SG_ 830 WPC2_IndSyncVal 1500;
BA_REL_ "GenSigTimeoutTime" BU_SG_REL_ WPC SG_ 830 WPC2_IndSyncVal 1500;
BA_ "Version" SG_ 830 WPC2_IndSyncVal "22.04.01";
BA_ "GenMsgSendType" BO_ 1099 0;
BA_ "Description" SG_ 1099 USM_CmdWPCSta "USM request value of WPC";
BA_ "GenSigSendType" SG_ 1099 USM_CmdWPCSta 4;
BA_ "UserSigValidity" SG_ 1099 USM_CmdWPCSta 0;
BA_REL_ "GenSigTimeoutTime" BU_SG_REL_ CGW_CCU SG_ 1099 USM_CmdWPCSta 1500;
BA_ "NetworkRequest" SG_ 1099 USM_CmdWPCSta 0;
BA_ "NetworkRequestHoldingTime" SG_ 1099 USM_CmdWPCSta 5000;
BA_ "Version" SG_ 1099 USM_CmdWPCSta "17.11.00";
BA_ "Description" SG_ 1099 WPC_SWVerMajor1 "Indicate the WPC software version as follows:

- The software version is displayed in three digits.

- The Major and Minor digits are separated by '.'

- Signal values are transmitted to ASCII codes.



※ Example

WPC_SWVerMajor1 : 0x41 (HEX) -> ASCII CODE : 'A' 

WPC_SWVerMinor1 : 0x30 (HEX) -> ASCII CODE : '0'

WPC_SWVerMinor2 : 0x33 (HEX) -> ASCII CODE : '3'

=> WPC S/W Ver is displayed 'A.03'";
BA_ "GenSigSendType" SG_ 1099 WPC_SWVerMajor1 4;
BA_ "UserSigValidity" SG_ 1099 WPC_SWVerMajor1 0;
BA_REL_ "GenSigTimeoutTime" BU_SG_REL_ CGW_CCU SG_ 1099 WPC_SWVerMajor1 1500;
BA_ "Version" SG_ 1099 WPC_SWVerMajor1 "20.12.04";
BA_ "Description" SG_ 1099 WPC_PhnLftWrngSta "Warning by WPC for User (Phone left in vehicle)";
BA_ "GenSigSendType" SG_ 1099 WPC_PhnLftWrngSta 4;
BA_ "UserSigValidity" SG_ 1099 WPC_PhnLftWrngSta 0;
BA_REL_ "GenSigTimeoutTime" BU_SG_REL_ CGW_CCU SG_ 1099 WPC_PhnLftWrngSta 1500;
BA_ "NetworkRequest" SG_ 1099 WPC_PhnLftWrngSta 0;
BA_ "NetworkRequestHoldingTime" SG_ 1099 WPC_PhnLftWrngSta 5000;
BA_ "Version" SG_ 1099 WPC_PhnLftWrngSta "18.02.03";
BA_ "Description" SG_ 1099 WPC_SWVerMinor1 "Indicate the WPC software version as follows:

- The software version is displayed in three digits.

- The Major and Minor digits are separated by '.'

- Signal values are transmitted to ASCII codes.



※ Example

WPC_SWVerMajor1 : 0x41 (HEX) -> ASCII CODE : 'A' 

WPC_SWVerMinor1 : 0x30 (HEX) -> ASCII CODE : '0'

WPC_SWVerMinor2 : 0x33 (HEX) -> ASCII CODE : '3'

=> WPC S/W Ver is displayed 'A.03'";
BA_ "GenSigSendType" SG_ 1099 WPC_SWVerMinor1 4;
BA_ "UserSigValidity" SG_ 1099 WPC_SWVerMinor1 0;
BA_REL_ "GenSigTimeoutTime" BU_SG_REL_ CGW_CCU SG_ 1099 WPC_SWVerMinor1 1500;
BA_ "Version" SG_ 1099 WPC_SWVerMinor1 "18.10.06";
BA_ "Description" SG_ 1099 WPC_SWVerMinor2 "Indicate the WPC software version as follows:

- The software version is displayed in three digits.

- The Major and Minor digits are separated by '.'

- Signal values are transmitted to ASCII codes.



※ Example

WPC_SWVerMajor1 : 0x41 (HEX) -> ASCII CODE : 'A' 

WPC_SWVerMinor1 : 0x30 (HEX) -> ASCII CODE : '0'

WPC_SWVerMinor2 : 0x33 (HEX) -> ASCII CODE : '3'

=> WPC S/W Ver is displayed 'A.03'";
BA_ "GenSigSendType" SG_ 1099 WPC_SWVerMinor2 4;
BA_ "UserSigValidity" SG_ 1099 WPC_SWVerMinor2 0;
BA_REL_ "GenSigTimeoutTime" BU_SG_REL_ CGW_CCU SG_ 1099 WPC_SWVerMinor2 1500;
BA_ "Version" SG_ 1099 WPC_SWVerMinor2 "18.10.06";
BA_ "Description" SG_ 1099 WPC_IndSyncVal "WPC IND ANIMATION SYNC SIGANL";
BA_ "GenSigSendType" SG_ 1099 WPC_IndSyncVal 4;
BA_ "TimeoutValue" SG_ 1099 WPC_IndSyncVal "0x0";
BA_ "UserSigValidity" SG_ 1099 WPC_IndSyncVal 3;
BA_REL_ "GenSigTimeoutTime" BU_SG_REL_ RWPC SG_ 1099 WPC_IndSyncVal 1500;
BA_REL_ "GenSigTimeoutTime" BU_SG_REL_ WPC2 SG_ 1099 WPC_IndSyncVal 1500;
BA_ "Version" SG_ 1099 WPC_IndSyncVal "22.04.01";
BA_ "Description" SG_ 1099 USM_CmdWPCIndSta "WPC Indicator animation type USM";
BA_ "GenSigSendType" SG_ 1099 USM_CmdWPCIndSta 4;
BA_ "GenSigStartValue" SG_ 1099 USM_CmdWPCIndSta 2;
BA_ "UserSigValidity" SG_ 1099 USM_CmdWPCIndSta 0;
BA_REL_ "GenSigTimeoutTime" BU_SG_REL_ CGW_CCU SG_ 1099 USM_CmdWPCIndSta 1500;
BA_ "NetworkRequest" SG_ 1099 USM_CmdWPCIndSta 0;
BA_ "NetworkRequestHoldingTime" SG_ 1099 USM_CmdWPCIndSta 5000;
BA_ "Version" SG_ 1099 USM_CmdWPCIndSta "22.05.02";
BA_ "GenMsgCycleTime" BO_ 1837 0;
BA_ "GenMsgCycleTimeFast" BO_ 1837 0;
BA_ "GenMsgNrOfRepetition" BO_ 1837 0;
BA_ "DiagResponse" BO_ 1837 1;
BA_ "GenMsgILSupport" BO_ 1837 0;
BA_ "TpMessage" BO_ 1837 1;
BA_ "TpTxIndex" BO_ 1837 180;
BA_ "Description" SG_ 1837 WPC_GST_Byte0 "TP Index : 180";
BA_ "UsrSigPurpose" SG_ 1837 WPC_GST_Byte0 4;
BA_ "UserSigValidity" SG_ 1837 WPC_GST_Byte0 0;
BA_REL_ "GenSigTimeoutTime" BU_SG_REL_ CGW_CCU SG_ 1837 WPC_GST_Byte0 0;
BA_ "NetworkRequest" SG_ 1837 WPC_GST_Byte0 0;
BA_ "NetworkRequestHoldingTime" SG_ 1837 WPC_GST_Byte0 5000;
BA_ "Version" SG_ 1837 WPC_GST_Byte0 "22.07.01";
BA_ "Description" SG_ 1837 WPC_GST_Byte2 "TP Index : 180";
BA_ "UsrSigPurpose" SG_ 1837 WPC_GST_Byte2 4;
BA_ "UserSigValidity" SG_ 1837 WPC_GST_Byte2 0;
BA_REL_ "GenSigTimeoutTime" BU_SG_REL_ CGW_CCU SG_ 1837 WPC_GST_Byte2 0;
BA_ "NetworkRequest" SG_ 1837 WPC_GST_Byte2 0;
BA_ "NetworkRequestHoldingTime" SG_ 1837 WPC_GST_Byte2 5000;
BA_ "Version" SG_ 1837 WPC_GST_Byte2 "22.07.01";
BA_ "Description" SG_ 1837 WPC_GST_Byte3 "TP Index : 180";
BA_ "UsrSigPurpose" SG_ 1837 WPC_GST_Byte3 4;
BA_ "UserSigValidity" SG_ 1837 WPC_GST_Byte3 0;
BA_REL_ "GenSigTimeoutTime" BU_SG_REL_ CGW_CCU SG_ 1837 WPC_GST_Byte3 0;
BA_ "NetworkRequest" SG_ 1837 WPC_GST_Byte3 0;
BA_ "NetworkRequestHoldingTime" SG_ 1837 WPC_GST_Byte3 5000;
BA_ "Version" SG_ 1837 WPC_GST_Byte3 "22.07.01";
BA_ "Description" SG_ 1837 WPC_GST_Byte4 "TP Index : 180";
BA_ "UsrSigPurpose" SG_ 1837 WPC_GST_Byte4 4;
BA_ "UserSigValidity" SG_ 1837 WPC_GST_Byte4 0;
BA_REL_ "GenSigTimeoutTime" BU_SG_REL_ CGW_CCU SG_ 1837 WPC_GST_Byte4 0;
BA_ "NetworkRequest" SG_ 1837 WPC_GST_Byte4 0;
BA_ "NetworkRequestHoldingTime" SG_ 1837 WPC_GST_Byte4 5000;
BA_ "Version" SG_ 1837 WPC_GST_Byte4 "22.07.01";
BA_ "Description" SG_ 1837 WPC_GST_Byte5 "TP Index : 180";
BA_ "UsrSigPurpose" SG_ 1837 WPC_GST_Byte5 4;
BA_ "UserSigValidity" SG_ 1837 WPC_GST_Byte5 0;
BA_REL_ "GenSigTimeoutTime" BU_SG_REL_ CGW_CCU SG_ 1837 WPC_GST_Byte5 0;
BA_ "NetworkRequest" SG_ 1837 WPC_GST_Byte5 0;
BA_ "NetworkRequestHoldingTime" SG_ 1837 WPC_GST_Byte5 5000;
BA_ "Version" SG_ 1837 WPC_GST_Byte5 "22.07.01";
BA_ "Description" SG_ 1837 WPC_GST_Byte6 "TP Index : 180";
BA_ "UsrSigPurpose" SG_ 1837 WPC_GST_Byte6 4;
BA_ "UserSigValidity" SG_ 1837 WPC_GST_Byte6 0;
BA_REL_ "GenSigTimeoutTime" BU_SG_REL_ CGW_CCU SG_ 1837 WPC_GST_Byte6 0;
BA_ "NetworkRequest" SG_ 1837 WPC_GST_Byte6 0;
BA_ "NetworkRequestHoldingTime" SG_ 1837 WPC_GST_Byte6 5000;
BA_ "Version" SG_ 1837 WPC_GST_Byte6 "22.07.01";
BA_ "Description" SG_ 1837 WPC_GST_Byte7 "TP Index : 180";
BA_ "UsrSigPurpose" SG_ 1837 WPC_GST_Byte7 4;
BA_ "UserSigValidity" SG_ 1837 WPC_GST_Byte7 0;
BA_REL_ "GenSigTimeoutTime" BU_SG_REL_ CGW_CCU SG_ 1837 WPC_GST_Byte7 0;
BA_ "NetworkRequest" SG_ 1837 WPC_GST_Byte7 0;
BA_ "NetworkRequestHoldingTime" SG_ 1837 WPC_GST_Byte7 5000;
BA_ "Version" SG_ 1837 WPC_GST_Byte7 "22.07.01";
BA_ "Description" SG_ 1837 WPC_GST_Byte1 "TP Index : 180";
BA_ "UsrSigPurpose" SG_ 1837 WPC_GST_Byte1 4;
BA_ "UserSigValidity" SG_ 1837 WPC_GST_Byte1 0;
BA_REL_ "GenSigTimeoutTime" BU_SG_REL_ CGW_CCU SG_ 1837 WPC_GST_Byte1 0;
BA_ "NetworkRequest" SG_ 1837 WPC_GST_Byte1 0;
BA_ "NetworkRequestHoldingTime" SG_ 1837 WPC_GST_Byte1 5000;
BA_ "Version" SG_ 1837 WPC_GST_Byte1 "22.07.01";
VAL_ 1050 BCM_Crc7Val 0 "0x0x0~0xFF:CRCValue" 255 "0x0x0~0xFF:CRCValue" ;
VAL_ 1050 BCM_AlvCnt7Val 0 "AlvCntValue" 1 "AlvCntValue" 2 "AlvCntValue" 3 "AlvCntValue" 4 "AlvCntValue" 5 "AlvCntValue" 6 "AlvCntValue" 7 "AlvCntValue" 8 "AlvCntValue" 9 "AlvCntValue" 10 "AlvCntValue" 11 "AlvCntValue" 12 "AlvCntValue" 13 "AlvCntValue" 14 "AlvCntValue" 15 "AlvCntValue" ;
VAL_ 1050 Lamp_HiPrioHzrdReq 0 "Off" 1 "High On" 2 "High Inactive" 3 "Reserved" 4 "Reserved" 5 "Reseved" 6 "Not Used" 7 "Error Indicator" ;
VAL_ 1050 Lamp_LoPrioHzrdReq 0 "Off" 1 "Low On" 2 "Low Inactive" 3 "Reserved" 4 "Reserved" 5 "Reseved" 6 "Not Used" 7 "Error Indicator" ;
VAL_ 1050 Lamp_IntTailLmpOnReq 0 "Off" 1 "On" 2 "Not Used" 3 "Error Indicator" ;
VAL_ 1050 Lamp_ExtrnlTailLmpOnReq 0 "Off" 1 "On" 2 "Not Used" 3 "Error Indicator" ;
VAL_ 1050 Lamp_HdLmpLoOnReq 0 "Off" 1 "On" 2 "Not Used" 3 "Error Indicator" ;
VAL_ 1050 Lamp_HdLmpHiOnReq 0 "Off" 1 "On" 2 "Not Used" 3 "Error Indicator" ;
VAL_ 1050 Lamp_AvTailLmpSta 0 "Off" 1 "On" 2 "Not Used" 3 "Error Indicator" ;
VAL_ 1050 Lamp_BckUpLmpCmd 0 "Off" 1 "On" 2 "Not Used" 3 "Error Indicator" ;
VAL_ 1050 Lamp_DrlOnReq 0 "Off" 1 "On" 2 "Not Used" 3 "Error Indicator" ;
VAL_ 1050 USM_IllAlwaysOnwithPSTNSta 0 "Default" 1 "Off" 2 "IllAlwaysOn" 3 "IllAlwaysOnwithPSTN" 4 "RESERVED" 5 "RESERVED" 6 "RESERVED" 7 "Invalid" ;
VAL_ 1090 BCM_Crc12Val 0 "0x0x0~0xFF:CRCValue" 255 "0x0x0~0xFF:CRCValue" ;
VAL_ 1090 BCM_AlvCnt12Val 0 "AlvCntValue" 1 "AlvCntValue" 2 "AlvCntValue" 3 "AlvCntValue" 4 "AlvCntValue" 5 "AlvCntValue" 6 "AlvCntValue" 7 "AlvCntValue" 8 "AlvCntValue" 9 "AlvCntValue" 10 "AlvCntValue" 11 "AlvCntValue" 12 "AlvCntValue" 13 "AlvCntValue" 14 "AlvCntValue" 15 "AlvCntValue" ;
VAL_ 1090 BCM_SmkOptTyp 0 "Non SMK Option" 1 "SMK Option" 2 "Not Used" 3 "Error Indicator" ;
VAL_ 1090 PHEV_FuelDrOpnSta 0 "Close" 1 "Open" 2 "Not Used" 3 "Error Indicator" ;
VAL_ 1090 BCM_SunRoofOptTyp 0 "NONE" 1 "Sunroof applied" 2 "reserved" 3 "Invalid" ;
VAL_ 1090 Window_DrvrSdWdwSta_BCM 0 "Window Close" 1 "Window Open" 2 "Not Used" 3 "Error Indicator" ;
VAL_ 1090 Window_AsstSdWdwSta_BCM 0 "Window Close" 1 "Window Open" 2 "Not Used" 3 "Error Indicator" ;
VAL_ 1090 Window_RrLftWdwSta_BCM 0 "Window Close" 1 "Window Open" 2 "Not Used" 3 "Error Indicator" ;
VAL_ 1090 Window_RrRtWdwSta_BCM 0 "Window Close" 1 "Window Open" 2 "Not Used" 3 "Error Indicator" ;
VAL_ 1090 SunRoof_GlassPosSta 0 "Glass Tilt up" 1 "Glass Vent area" 2 "Glass Anti pinch in vent" 3 "Glass Fully close" 4 "Glass Anti pinch in partially slide" 5 "Glass Partially slide" 6 "Glass Fully open" 7 "Glass Uninitialized" 8 "Reserved" 9 "Reserved" 10 "Reserved" 11 "Reserved" 12 "Reserved" 13 "Reserved" 14 "Reserved" 15 "invalid" ;
VAL_ 1090 PHEV_FuelDrDis 0 "Off" 1 "Fuel Door Open Wait" 2 "Refueling Ready(Fuel Door Open)" 3 "Check Fuel Door" 4 "Charging" 5 "Fuel Door Not Open" 6 "Not Used" 7 "Error Indicator" ;
VAL_ 1090 SunRoof_BlindPosSta 0 "BLIND_HALF_OPEN" 1 "BLIND_LESS_THEN_HALF_OPEN" 2 "BLIND_ANTIPINCH_LESS_THAN_HALF_OPEN" 3 "BLIND_FULLY_CLOSE" 4 "BLIND_ANTIPINCH_MORE_THAN_HALF_OPEN" 5 "BLIND_MORE_THAN_HALF_OPEN" 6 "BLIND_FULLY_OPEN" 7 "BLIND_UNINITIALIZED" 8 "Reserved" 9 "Reserved" 10 "Reserved" 11 "Reserved" 12 "Reserved" 13 "Reserved" 14 "Reserved" 15 "invalid" ;
VAL_ 1090 SunRoof_GlassErrSta 0 "Glass No error" 1 "Glass Thermal Protection Active" 2 "Glass Initialized Status" 3 "Glass Undefined ECU Error" 4 "Glass Switch Error" 5 "Glass Voltage error" 6 "Complex Error" 7 "invalid" ;
VAL_ 1090 SunRoof_BlindErrSta 0 "Roll Blind No error" 1 "Roll Blind Thermal Protection Active" 2 "Roll Blind Initialized Status" 3 "Roll Blind Undefined ECU Error" 4 "Roll Blind Switch Error" 5 "Roll Blind Voltage error" 6 "Complex Error" 7 "invalid" ;
VAL_ 2256644609 CLU_Crc1Val 0 "0x0x0~0xFFFF:CRCValue" 65535 "0x0x0~0xFFFF:CRCValue" ;
VAL_ 2256644609 CLU_AlvCnt1Val 0 "0x0x0~0xFF:AlvCntValue" 255 "0x0x0~0xFF:AlvCntValue" ;
VAL_ 2256644609 CLU_DtntOutSta 0 "Detent Off" 1 "Detent On" 2 "Not used" 3 "Error Indicator" ;
VAL_ 2256644609 CLU_SpdUnitTyp 0 "km/h" 1 "MPH" 2 "Not used" 3 "Error Indicator" ;
VAL_ 2256644609 CLU_DisSpdDcmlVal 0 "0" 1 "0.125" 2 "0.250" 3 "0.375" ;
VAL_ 2256644609 CLU_SWRCCrsMainSwSta 0 "Off" 1 "Key On" 2 "Reserved" 3 "Invalid" ;
VAL_ 2256644609 CLU_SWRCCrsSwSta 0 "Idle Position" 1 "Plus" 2 "Minus" 3 "Headway" 4 "Cancel/Pause" 5 "Reserved" 6 "Reserved" 7 "Reserved" ;
VAL_ 2256644609 CLU_SWRCLFASwSta 0 "Off" 1 "Key On" 2 "Reserved" 3 "Invalid" ;
VAL_ 2256644609 CLU_SWRCSldMainSwSta 0 "Off" 1 "Key On" 2 "Reserved" 3 "Invalid" ;
VAL_ 2256644609 CLU_RhstaLvlSta 0 "Reserved" 1 "Step 1" 2 "Step 2" 3 "Step 3" 4 "Step 4" 5 "Step 5" 6 "Step 6" 7 "Step 7" 8 "Step 8" 9 "Step 9" 10 "Step 10" 11 "Step 11" 12 "Step 12" 13 "Step 13" 14 "Step 14" 15 "Step 15" 16 "Step 16" 17 "Step 17" 18 "Step 18" 19 "Step 19" 20 "Step 20 (Reset Value)" 21 "Step 21 (Detent)" ;
VAL_ 2256644609 CLU_DisSpdVal 1023 "Error" ;
VAL_ 2256644609 CLU_OKSwSta 0 "Off" 1 "Key On" 2 "Reserved" 3 "Invalid" ;
VAL_ 2256644610 CLU_DisSpdVal_KPH 511 "Error" ;
VAL_ 2256644610 CLU_CUSTOMSta_NEW 0 "Default" 1 "MY DRIVE MODE(CUSTOM)" 2 "SMART(CUSTOM)" 3 "BABY(CUSTOM)" 4 "RETRO(CUSTOM)" 5 "SNOW(CUSTOM)-Not Terrain" 6 "COMFORT(REAR)(CUSTOM)" 7 "" 8 "" 9 "" 10 "" 11 "" 12 "" 13 "" 14 "Off(CUSTOM)" 15 "Invalid" ;
VAL_ 2256644610 CLU_AutoBrightSta 0 "Reserved (Not Used)" 1 "0x01~0xC8:Bright State (1~200 Step)" 200 "0x01~0xC8:Bright State (1~200 Step)" ;
VAL_ 2256644610 CLU_NotMinModeBrightSta 0 "RESERVED" 1 "0x01~0xC8:CLU Bright State (1~200 Step)" 200 "0x01~0xC8:CLU Bright State (1~200 Step)" 201 "RESERVED" 202 "RESERVED" 203 "RESERVED" 204 "RESERVED" 205 "RESERVED" 206 "RESERVED" 207 "RESERVED" 208 "RESERVED" 209 "RESERVED" 210 "RESERVED" 211 "RESERVED" 212 "RESERVED" 213 "RESERVED" 214 "RESERVED" 215 "RESERVED" 216 "RESERVED" 217 "RESERVED" 218 "RESERVED" 219 "RESERVED" 220 "RESERVED" 221 "RESERVED" 222 "RESERVED" 223 "RESERVED" 224 "RESERVED" 225 "RESERVED" 226 "RESERVED" 227 "RESERVED" 228 "RESERVED" 229 "RESERVED" 230 "RESERVED" 231 "RESERVED" 232 "RESERVED" 233 "RESERVED" 234 "RESERVED" 235 "RESERVED" 236 "RESERVED" 237 "RESERVED" 238 "RESERVED" 239 "RESERVED" 240 "RESERVED" 241 "RESERVED" 242 "RESERVED" 243 "RESERVED" 244 "RESERVED" 245 "RESERVED" 246 "RESERVED" 247 "RESERVED" 248 "RESERVED" 249 "RESERVED" 250 "RESERVED" 251 "RESERVED" 252 "RESERVED" 253 "RESERVED" 254 "RESERVED" 255 "RESERVED" ;
VAL_ 2256644610 CLU_PwrAutoOffResetReq_HCU 0 "Default" 1 "Reset Request" 2 "Reserved" 3 "Invalid" ;
VAL_ 2470760705 CLU_Crc5Val 0 "0x0x0~0xFFFF:CRCValue" 65535 "0x0x0~0xFFFF:CRCValue" ;
VAL_ 2470760705 CLU_AlvCnt5Val 0 "0x0x0~0xFF:AlvCntValue" 255 "0x0x0~0xFF:AlvCntValue" ;
VAL_ 2470760705 USM_TlgtAwayCloseSetReq 0 "Default(No Display)" 1 "Off" 2 "On" 3 "Invalid" ;
VAL_ 2470760705 USM_InletAutoLockSetReq 0 "Default" 1 "Auto Mode" 2 "Lock Mode" 3 "Unlock Mode" 4 "Reserved" 5 "Reserved" 6 "Reserved" 7 "Invalid" ;
VAL_ 2470760705 USM_IFSActVehSpd_Set 0 "Default" 1 "Vehicle Speed Function Off" 2 "10km/h" 3 "20" 4 "30" 5 "40" 6 "50" 7 "60" 8 "70" 9 "80" 10 "90" 11 "100" 12 "RESERVED" 13 "RESERVED" 14 "RESERVED" 15 "Invalid" ;
VAL_ 2470760705 USM_StaRst1Req 0 "Defualt" 1 "Reset" 2 "Not used" 3 "Error Indicator" ;
VAL_ 2470760705 USM_NccCamSetReq 0 "Not Applied" 1 "Function Off" 2 "Function On - Manual Resume" 3 "Function On - Automatic Resume" 4 "Reserved" 5 "Reserved" 6 "Reserved" 7 "Invalid" ;
VAL_ 2470760705 CLU_RrStRemindDelayReq 0 "default" 1 "delay request" 2 "RESERVED" 3 "Invalid" ;
VAL_ 2470760705 CLU_RrStRemindDelayFdbckReq 0 "Defualt" 1 "Delay" 2 "RESERVED" 3 "Invalid" ;
VAL_ 2470763009 CLU_Crc9Val 0 "0x0x0~0xFFFF:CRCValue" 65535 "0x0x0~0xFFFF:CRCValue" ;
VAL_ 2470763009 CLU_AlvCnt9Val 0 "0x0x0~0xFF:AlvCntValue" 255 "0x0x0~0xFF:AlvCntValue" ;
VAL_ 2470763009 USM_MdLmpClrSetReq 0 "Default" 1 "color 1" 2 "color 2" 3 "color 3" 4 "color 4" 5 "color 5" 6 "color 6" 7 "color 7" 8 "color 8" 9 "color 9" 10 "color 10" 11 "reserved" 12 "reserved" 13 "reserved" 14 "reserved" 15 "Invalid" ;
VAL_ 2470763009 USM_RrWiperRevSetReq 0 "Default" 1 "Rear Wiper(reverse) Off" 2 "Rear Wiper(reverse) On" 3 "Invalid" ;
VAL_ 2470763009 USM_RrStRemindSetReq 0 "Default" 1 "Off(Disable)" 2 "On(Enable)" 3 "Invalid" ;
VAL_ 2470763009 USM_RrWpcSetReq 0 "Default" 1 "Off(Disable)" 2 "On(Enable)" 3 "Invalid" ;
VAL_ 2470763009 USM_WpcSetReq 0 "Default" 1 "Off(Disable)" 2 "On(Enable)" 3 "Invalid" ;
VAL_ 2470763009 USM_SeqLmpSetReq 0 "Default" 1 "Off" 2 "On" 3 "Invalid" ;
VAL_ 2470763009 USM_UnlckWlcmSetReq 0 "Default Value" 1 "Off" 2 "On" 3 "Invalid" ;
VAL_ 2470763009 USM_SmrtWlcmSetReq 0 "Default Value" 1 "Off" 2 "On" 3 "Invalid" ;
VAL_ 2470763009 USM_UipSetReq 0 "Default(USM미구성)" 1 "Off(Disable)" 2 "On(Enable)" 3 "Invalid" ;
VAL_ 2470763009 USM_DigitalKeyEnblSetReq 0 "Default(미구성)" 1 "Disable" 2 "Enable" 3 "Invalid" ;
VAL_ 2470763009 USM_OwnerPhnRegSetReq 0 "Default(미구성)" 1 "Deleter" 2 "Register" 3 "Invalid" ;
VAL_ 2470763009 USM_NFCCard1RegSetReq 0 "Default(미구성)" 1 "Disable" 2 "Enable" 3 "Invalid" ;
VAL_ 2470763009 USM_NFCCard2RegSetReq 0 "Default(미구성)" 1 "Disable" 2 "Enable" 3 "Invalid" ;
VAL_ 2470763009 USM_ProcStpReq 0 "Default" 1 "StopReq" ;
VAL_ 2470763009 USM_PwrAutoOffTimeSetReq 0 "Default" 1 "Timer1" 2 "Timer2" 3 "Timer3" 4 "Timer4" 5 "Reserved" 6 "Reserved" 7 "Invalid" ;
VAL_ 2470763009 USM_RrStRemindSetReq_RestMode 0 "Default" 1 "Off(Disable)" 2 "On(Enable)" 3 "Invalid" 4 "Reserved" 5 "Reserved" 6 "Not Used" 7 "Error Indicator" ;
VAL_ 2470763009 USM_1stRrStRemindSetReq 0 "Default" 1 "Off(Disable)" 2 "On(Enable)" 3 "Invalid" ;
VAL_ 2470763009 USM_Wpc2SetReq 0 "Default" 1 "Off(Disable)" 2 "On(Enable)" 3 "Invalid" ;
VAL_ 2353206529 CLU_Crc20Val 0 "0x0x0~0xFFFF:CRCValue" 65535 "0x0x0~0xFFFF:CRCValue" ;
VAL_ 2353206529 CLU_AlvCnt20Val 0 "0x0x0~0xFF:AlvCntValue" 255 "0x0x0~0xFF:AlvCntValue" ;
VAL_ 2353206529 CLU_SndType 0 "Cluster applied speaker" 1 "Cluster applied buzzer" 2 "Not used" 3 "Error Indicator" ;
VAL_ 2353206529 CLU_ClusterUSM 0 "Default" 1 "Cluster not applied USM" 2 "Cluster applied USM" 3 "Reserved" ;
VAL_ 2214658049 EMS_Crc2Val 0 "0x0x0~0xFFFF:CRCValue" 65535 "0x0x0~0xFFFF:CRCValue" ;
VAL_ 2214658049 EMS_AlvCnt2Val 0 "0x0x0~0xFF:AlvCntValue" 255 "0x0x0~0xFF:AlvCntValue" ;
VAL_ 2214658049 ENG_BrkSwSta 0 "Brake switch is not pressed (OFF)" 1 "Brake switch is pressed (ON)" 2 "EMS does not support this function." 3 "Brake switch failure" ;
VAL_ 2214658049 ENG_EngClntTempVal 255 "Error indicator" ;
VAL_ 2214658049 ENG_MafCrctVal 128 "Error indicator" ;
VAL_ 2214658049 ENG_BattDscnctSta 0 "no battery disconnection detected" 1 "battery disconnection detected and failure memory erased" 2 "Not used" 3 "Error indicator" ;
VAL_ 2214658049 OBD_MilConfgVal 0 "no MIL, Failure Memory Management OBD-I" 1 "MIL Treatment OBD-I, Failure Memory Management OBD-I" 2 "MIL Treatment OBD-II, Exception" 3 "MIL Treatment OBD-II, Failure Memory Management OBD-II" 4 "MIL Treatment E-OBD, Failure Memory Management E-OBD" 5 "MIL Treatment K-OBD, Failure Memory Management K-OBD" ;
VAL_ 2214658049 ENG_EngSta 0 "Engine Stop" 1 "Cranking" 2 "Stalled" 3 "Running" 4 "Reserved" 5 "Reserved" 6 "Reserved" 7 "Fault" ;
VAL_ 2214659330 HEV_EngOpSta 0 "ES(Engine Stop)" 1 "ST(Start)" 2 "IS(Idle speed)" 3 "PL(Part Load)" 4 "PU(Pull)" 5 "PUC(Fuel Cut off)" ;
VAL_ 2214659330 HEV_AccelPdlVal 0 "Accelerator Pedal not activated" 1022 "Accelerator Pedal fully activated" 1023 "Accelerator Pedal is defective (fail state) or Non-ETC system (APS is not installed)" ;
VAL_ 2210462210 HCU_GreenZoneLmpDis 0 "GDM Lamp Off" 1 "GDM Lamp On" ;
VAL_ 2210462210 HCU_MILOnReq 0 "Not request" 1 "MIL On Request" 2 "Not used" 3 "Error Indicator" ;
VAL_ 2210462210 HCU_PhevAutoModOnSta 0 "AUTO Mode Off" 1 "AUTO Mode On" ;
VAL_ 2210462210 HCU_SccDrvOvrdReq 0 "Override clear" 1 "Override set" 2 "Not used" 3 "Error Indicator" ;
VAL_ 2210462210 HCU_SccEnblSta 0 "SCC Impossible" 1 "SCC Possible" 2 "Not used" 3 "Error Indicator" ;
VAL_ 2210462210 HCU_SlwDnSta 0 "None" 1 "Slowdown state" 2 "Not used" 3 "Error Indicator" ;
VAL_ 2210462210 HCU_HcuRdySta 0 "HCU not Ready" 1 "HCU Control Board Ready" 2 "Not used" 3 "Error Indicator" ;
VAL_ 2210462210 HCU_SmrtEcoGdDis 0 "Off" 1 "On" 2 "Not used" 3 "Error Indicator" ;
VAL_ 2210462210 HCU_SmrtEcoLvlDis 0 "Not Display" 1 "1~100%" 2 "1~100%" 3 "1~100%" 4 "1~100%" 5 "1~100%" 6 "1~100%" 7 "1~100%" 8 "1~100%" 9 "1~100%" 10 "1~100%" 11 "1~100%" 12 "1~100%" 13 "1~100%" 14 "1~100%" 15 "1~100%" 16 "1~100%" 17 "1~100%" 18 "1~100%" 19 "1~100%" 20 "1~100%" 21 "1~100%" 22 "1~100%" 23 "1~100%" 24 "1~100%" 25 "1~100%" 26 "1~100%" 27 "1~100%" 28 "1~100%" 29 "1~100%" 30 "1~100%" 31 "1~100%" 32 "1~100%" 33 "1~100%" 34 "1~100%" 35 "1~100%" 36 "1~100%" 37 "1~100%" 38 "1~100%" 39 "1~100%" 40 "1~100%" 41 "1~100%" 42 "1~100%" 43 "1~100%" 44 "1~100%" 45 "1~100%" 46 "1~100%" 47 "1~100%" 48 "1~100%" 49 "1~100%" 50 "1~100%" 51 "1~100%" 52 "1~100%" 53 "1~100%" 54 "1~100%" 55 "1~100%" 56 "1~100%" 57 "1~100%" 58 "1~100%" 59 "1~100%" 60 "1~100%" 61 "1~100%" 62 "1~100%" 63 "1~100%" 64 "1~100%" 65 "1~100%" 66 "1~100%" 67 "1~100%" 68 "1~100%" 69 "1~100%" 70 "1~100%" 71 "1~100%" 72 "1~100%" 73 "1~100%" 74 "1~100%" 75 "1~100%" 76 "1~100%" 77 "1~100%" 78 "1~100%" 79 "1~100%" 80 "1~100%" 81 "1~100%" 82 "1~100%" 83 "1~100%" 84 "1~100%" 85 "1~100%" 86 "1~100%" 87 "1~100%" 88 "1~100%" 89 "1~100%" 90 "1~100%" 91 "1~100%" 92 "1~100%" 93 "1~100%" 94 "1~100%" 95 "1~100%" 96 "1~100%" 97 "1~100%" 98 "1~100%" 99 "1~100%" 100 "1~100%" 101 "Reserved" 102 "Reserved" 103 "Reserved" 104 "Reserved" 105 "Reserved" 106 "Reserved" 107 "Reserved" 108 "Reserved" 109 "Reserved" 110 "Reserved" 111 "Reserved" 112 "Reserved" 113 "Reserved" 114 "Reserved" 115 "Reserved" 116 "Reserved" 117 "Reserved" 118 "Reserved" 119 "Reserved" 120 "Reserved" 121 "Reserved" 122 "Reserved" 123 "Reserved" 124 "Reserved" 125 "Reserved" 126 "Reserved" 127 "Reserved" ;
VAL_ 2210462210 HCU_SmrtEcoRngDis 0 "Not Display" 1 "1~100%" 2 "1~100%" 3 "1~100%" 4 "1~100%" 5 "1~100%" 6 "1~100%" 7 "1~100%" 8 "1~100%" 9 "1~100%" 10 "1~100%" 11 "1~100%" 12 "1~100%" 13 "1~100%" 14 "1~100%" 15 "1~100%" 16 "1~100%" 17 "1~100%" 18 "1~100%" 19 "1~100%" 20 "1~100%" 21 "1~100%" 22 "1~100%" 23 "1~100%" 24 "1~100%" 25 "1~100%" 26 "1~100%" 27 "1~100%" 28 "1~100%" 29 "1~100%" 30 "1~100%" 31 "1~100%" 32 "1~100%" 33 "1~100%" 34 "1~100%" 35 "1~100%" 36 "1~100%" 37 "1~100%" 38 "1~100%" 39 "1~100%" 40 "1~100%" 41 "1~100%" 42 "1~100%" 43 "1~100%" 44 "1~100%" 45 "1~100%" 46 "1~100%" 47 "1~100%" 48 "1~100%" 49 "1~100%" 50 "1~100%" 51 "1~100%" 52 "1~100%" 53 "1~100%" 54 "1~100%" 55 "1~100%" 56 "1~100%" 57 "1~100%" 58 "1~100%" 59 "1~100%" 60 "1~100%" 61 "1~100%" 62 "1~100%" 63 "1~100%" 64 "1~100%" 65 "1~100%" 66 "1~100%" 67 "1~100%" 68 "1~100%" 69 "1~100%" 70 "1~100%" 71 "1~100%" 72 "1~100%" 73 "1~100%" 74 "1~100%" 75 "1~100%" 76 "1~100%" 77 "1~100%" 78 "1~100%" 79 "1~100%" 80 "1~100%" 81 "1~100%" 82 "1~100%" 83 "1~100%" 84 "1~100%" 85 "1~100%" 86 "1~100%" 87 "1~100%" 88 "1~100%" 89 "1~100%" 90 "1~100%" 91 "1~100%" 92 "1~100%" 93 "1~100%" 94 "1~100%" 95 "1~100%" 96 "1~100%" 97 "1~100%" 98 "1~100%" 99 "1~100%" 100 "1~100%" 101 "Reserved" 102 "Reserved" 103 "Reserved" 104 "Reserved" 105 "Reserved" 106 "Reserved" 107 "Reserved" 108 "Reserved" 109 "Reserved" 110 "Reserved" 111 "Reserved" 112 "Reserved" 113 "Reserved" 114 "Reserved" 115 "Reserved" 116 "Reserved" 117 "Reserved" 118 "Reserved" 119 "Reserved" 120 "Reserved" 121 "Reserved" 122 "Reserved" 123 "Reserved" 124 "Reserved" 125 "Reserved" 126 "Reserved" 127 "Reserved" ;
VAL_ 2210462210 HCU_SpdLimDeviceActSta 0 "Speed Limiter Lamp Off (Deactivation)" 1 "Speed Limiter Lamp On (Activation)" 2 "Not used" 3 "Error Indicator" ;
VAL_ 2210462210 HCU_SpdLimDeviceOperSta 0 "Speed Limiter Not Operation" 1 "Speed Limiter Operation" 2 "Speed Limiter Standby" 3 "Error Inicator" ;
VAL_ 2210462210 HCU_HEVRdyDis 0 "READY LAMP OFF" 1 "READY LAMP ON" 2 "Not used" 3 "READY LAMP BLINKING" ;
VAL_ 2210462210 HCU_SpdLimDeviceVehSpdVal 0 "0x0x00~0xFF:real values" 255 "0x0x00~0xFF:real values" ;
VAL_ 2210462210 HCU_SrvModSta 0 "Normal made" 1 "2WD Test mode" 2 "Not used" 3 "Error Indicator" ;
VAL_ 2210462210 HCU_StrtInhbt2Sta 0 "None" 1 "Start Inhibit" 2 "Not used" 3 "Error Indicator" ;
VAL_ 2210462210 HCU_StrtInhbtSta 0 "None" 1 "Start Inhibit state" 2 "Not used" 3 "Error Indicator" ;
VAL_ 2210462210 HCU_SysShtOffReq 0 "Not request" 1 "Request" 2 "Not used" 3 "Error Indicator" ;
VAL_ 2210462210 HCU_VehStrtEnblSta 0 "Start disable" 1 "Start Enable" 2 "Not used" 3 "Error Indicator" ;
VAL_ 2210462210 HCU_BrkLmpOnReq 0 "None" 1 "Lamp On Request" 2 "Not Used" 3 "Error Indicator" ;
VAL_ 2210462210 HCU_HevRdySta 0 "HEV not ready" 1 "HEV Drivable" 2 "Not used" 3 "Error Indicator" ;
VAL_ 2210462210 HCU_CcDrvAlrtDis 0 "default" 1 "CC Disengaged" 2 "No CC Engage Condition" 3 "reserved" ;
VAL_ 2210462210 HCU_SldDrvAlrtDis 0 "default" 1 "SLDdisengeged" 2 "NoSLDEngageCondition" 3 "Reserve" ;
VAL_ 2210462210 HCU_LimpOffSta 0 "None" 1 "Limp off the road" 2 "Not used" 3 "Error Indicator" ;
VAL_ 1240 HU_DistanceUnit 0 "Km" 1 "Mile" 2 "Reserved" 3 "Invalid" ;
VAL_ 1240 HU_ThemeType 0 "default" 1 "Aqua(Hyundai)" 16 "Copper" 17 "Copper Rust" 2 "Magenta(Kia)" 32 "ccIC Light" 33 "ccIC Dark" 3 "Eco White" 4 "Eco Black" 5 "Genesis(IKPE)" 6 "Magenta White" ;
VAL_ 1240 HU_MicActivity 0 "Deactivated" 1 "Activated" 2 "reserved" 3 "Invalid" ;
VAL_ 1240 HU_Scheduled_Setting 0 "Scheduled not set" 1 "Scheduled set" 2 "Reserved" 3 "Reserved" 4 "Reserved" 5 "Reserved" 6 "60% SoC Requested" 7 "70% SoC Requested" 8 "80% SoC Requested" 9 "90% SoC Requested" 10 "100% SoC Requested" 11 "Reserved" 12 "Reserved" 13 "Reserved" 14 "Reserved" 15 "Invalid" ;
VAL_ 1240 AVN_RSPA_ModeSelect 0 "None" 1 "CCP focus (1st menu on the left)" 2 "Touch or CCP confirm (1st menu on the left)" 3 "CCP focus (2nd menu on the left)" 4 "Touch or CCP confirm (2nd menu on the left)" 5 "CCP focus (1st menu on the right)" 6 "Touch or CCP confirm (1st menu on the right)" 7 "CCP focus (2nd menu on the right)" 8 "Touch or CCP confirm (2nd menu on the right)" 9 "Reserved" 10 "Reserved" 11 "Reserved" 12 "Reserved" 13 "Reserved" 14 "Reserved" 15 "Invalid" ;
VAL_ 1240 CF_HU_GPSFlt 0 "Normal" 1 "Fault operation" 2 "TimeOut" 3 "Invalid" ;
VAL_ 1240 AVN_RSPA_CancelInput 0 "Init" 1 "No Input" 2 "Cancel Input" 3 "Invalid" ;
VAL_ 1240 AVN_RSPA_Disp_Rdy 0 "Impossible to display" 1 "Possible to display" 2 "Reserved" 3 "Invalid" ;
VAL_ 1240 CF_AVN_ProfileIDRValue 0 "Default" 1 "Guest" 2 "Profile 1" 3 "Profile 2" 4 "reserved" 5 "reserved" 6 "reserved" 7 "reserved" 8 "reserved" 9 "reserved" 10 "reserved" 11 "reserved" 12 "reserved" 13 "reserved" 14 "reserved" 15 "Invalid" ;
VAL_ 1240 HazardFromHUSVM 0 "inactive" 1 "active" 2 "reserved" 3 "invalid" ;
VAL_ 1240 OMUOSMirCtrl 0 "Off" 1 "Fold" 2 "Unfold" 3 "invalid" ;
VAL_ 1240 OTAUIStatus 0 "Not Ready" 1 "Ready" 2 "Reserved" 3 "Invalid" ;
VAL_ 1240 C_TeleActiveStatus 0 "Active" 1 "Deactive" 2 "Reserved" 3 "Invalid" ;
VAL_ 1240 HU_AliveStatus 0 "Not Ready" 1 "On Mode" 2 "Head Unit Update Mode" 3 "Invalid" ;
VAL_ 1240 HU_RTCCheck 0 "Ready" 1 "Checking" 2 "Reserved" 3 "Invalid" ;
VAL_ 1195 CF_AVN_CluWelcomeSnd 0 "Default" 1 "Off" 2 "On" 3 "Invalid" ;
VAL_ 1195 CF_AVN_CluTransmissionDisp 0 "Default" 1 "Off" 2 "On" 3 "Invalid" ;
VAL_ 1195 CF_AVN_CluWiperLight 0 "Default" 1 "Off" 2 "On" 3 "Invalid" ;
VAL_ 1195 CF_AVN_CluRoadInfoGuide 0 "Default" 1 "Off" 2 "On" 3 "Invalid" ;
VAL_ 1195 CF_AVN_CluUserSettingPeriod 0 "0~99month" 1 "0~99month" 2 "0~99month" 3 "0~99month" 4 "0~99month" 5 "0~99month" 6 "0~99month" 7 "0~99month" 8 "0~99month" 9 "0~99month" 10 "0~99month" 11 "0~99month" 12 "0~99month" 13 "0~99month" 14 "0~99month" 15 "0~99month" 16 "0~99month" 17 "0~99month" 18 "0~99month" 19 "0~99month" 20 "0~99month" 21 "0~99month" 22 "0~99month" 23 "0~99month" 24 "0~99month" 25 "0~99month" 26 "0~99month" 27 "0~99month" 28 "0~99month" 29 "0~99month" 30 "0~99month" 31 "0~99month" 32 "0~99month" 33 "0~99month" 34 "0~99month" 35 "0~99month" 36 "0~99month" 37 "0~99month" 38 "0~99month" 39 "0~99month" 40 "0~99month" 41 "0~99month" 42 "0~99month" 43 "0~99month" 44 "0~99month" 45 "0~99month" 46 "0~99month" 47 "0~99month" 48 "0~99month" 49 "0~99month" 50 "0~99month" 51 "0~99month" 52 "0~99month" 53 "0~99month" 54 "0~99month" 55 "0~99month" 56 "0~99month" 57 "0~99month" 58 "0~99month" 59 "0~99month" 60 "0~99month" 61 "0~99month" 62 "0~99month" 63 "0~99month" 64 "0~99month" 65 "0~99month" 66 "0~99month" 67 "0~99month" 68 "0~99month" 69 "0~99month" 70 "0~99month" 71 "0~99month" 72 "0~99month" 73 "0~99month" 74 "0~99month" 75 "0~99month" 76 "0~99month" 77 "0~99month" 78 "0~99month" 79 "0~99month" 80 "0~99month" 81 "0~99month" 82 "0~99month" 83 "0~99month" 84 "0~99month" 85 "0~99month" 86 "0~99month" 87 "0~99month" 88 "0~99month" 89 "0~99month" 90 "0~99month" 91 "0~99month" 92 "0~99month" 93 "0~99month" 94 "0~99month" 95 "0~99month" 96 "0~99month" 97 "0~99month" 98 "0~99month" 99 "0~99month" 100 "Reserved" 101 "Reserved" 102 "Reserved" 103 "Reserved" 104 "Reserved" 105 "Reserved" 106 "Reserved" 107 "Reserved" 108 "Reserved" 109 "Reserved" 110 "Reserved" 111 "Reserved" 112 "Reserved" 113 "Reserved" 114 "Reserved" 115 "Reserved" 116 "Reserved" 117 "Reserved" 118 "Reserved" 119 "Reserved" 120 "Reserved" 121 "Reserved" 122 "Reserved" 123 "Reserved" 124 "Reserved" 125 "Reserved" 126 "Reserved" 127 "Invalid" ;
VAL_ 1195 CF_AVN_CluFuelEconUnit_mi 0 "Default" 1 "US gallon" 2 "UK gallon" 3 "Reserved" ;
VAL_ 1195 CF_AVN_CluFuelEconUnit_km 0 "Default" 1 "km/L, km/kg, km/kWh" 2 "L/100km, kg/100km, kWh/100km" 3 "Reserved" ;
VAL_ 1195 CF_AVN_CluUserSettingDistance 0 "0x0x0~0x1869F:0~9999km_mi" 99999 "0x0x0~0x1869F:0~9999km_mi" 131071 "Invalid" ;
VAL_ 1195 CF_AVN_CluRheostatLvl 0 "Reserved" 1 "Step 1" 2 "Step 2" 3 "Step 3" 4 "Step 4" 5 "Step 5" 6 "Step 6" 7 "Step 7" 8 "Step 8" 9 "Step 9" 10 "Step 10" 11 "Step 11" 12 "Step 12" 13 "Step 13" 14 "Step 14" 15 "Step 15" 16 "Step 16" 17 "Step 17" 18 "Step 18" 19 "Step 19" 20 "Step 20(Reset Value)" 21 "Step 21(Detent)" 22 "Reserved" 23 "Reserved" 24 "Reserved" 25 "Reserved" 26 "Reserved" 27 "Reserved" 28 "Reserved" 29 "Reserved" 30 "Reserved" 31 "Invalid" ;
VAL_ 1195 CF_AVN_EVReset 0 "Default" 1 "USM Reset" 2 "Reserved" 3 "Invalid" ;
VAL_ 1195 CF_AVN_UnitReset 0 "Default" 1 "Unit Reset" 2 "Reserved" 3 "Invalid" ;
VAL_ 1195 CF_AVN_CluServiceReminderReset 0 "Default" 1 "Service Reminder Reset" 2 "Reserved" 3 "Invalid" ;
VAL_ 1195 CF_AVN_CluUSMReset 0 "Default" 1 "USM Reset" 2 "Reserved" 3 "Invalid" ;
VAL_ 1195 CF_AVN_CluServiceReminderSet 0 "Default" 1 "Off" 2 "On" 3 "Invalid" ;
VAL_ 1041 ICU_MtGearPosRSta 0 "Off" 1 "On" 2 "RESERVED" 3 "RESERVED" ;
VAL_ 1041 Autocut_DlvryModSta 0 "Before Delivery(Welcome Off)" 1 "After Delivery(Welcome On)" 2 "Not Used" 3 "Error Indicator" ;
VAL_ 1041 DoorLock_AsstDrUnLkSta 0 "Lock" 1 "Unlock" 2 "Not Used" 3 "Error Indicator" ;
VAL_ 1041 Warn_DrvDrSwSta 0 "Close" 1 "Open" 2 "Not Used" 3 "Error Indicator" ;
VAL_ 1041 DoorLock_DrvKeyUnLkSwSta 0 "Off" 1 "Unlock" 2 "Not Used" 3 "Error Indicator" ;
VAL_ 1041 DoorLock_RrLftDrUnLkSta 0 "Lock" 1 "Unlock" 2 "Not Used" 3 "Error Indicator" ;
VAL_ 1041 DoorLock_RrRtDrUnLkSta 0 "Lock" 1 "Unlock" 2 "Not Used" 3 "Error Indicator" ;
VAL_ 1041 Warn_AsstDrSwSta 0 "Close" 1 "Open" 2 "Not Used" 3 "Error Indicator" ;
VAL_ 1041 Warn_AsstStBltSwSta 0 "Unbelted" 1 "Belted" 2 "Not Used" 3 "Error Indicator" ;
VAL_ 1041 Warn_BrkFldSwSta 0 "Off" 1 "On" 2 "Not Used" 3 "Error Indicator" ;
VAL_ 1041 DoorLock_DrvKeyLkSwSta 0 "Off" 1 "Lock" 2 "Not Used" 3 "Error Indicator" ;
VAL_ 1041 Warn_DrvStBltSwSta 0 "Unbelted" 1 "Belted" 2 "Not Used" 3 "Error Indicator" ;
VAL_ 1041 Warn_HoodSwSta 0 "Off" 1 "On" 2 "Not Used" 3 "Error Indicator" ;
VAL_ 1041 Warn_PassStOccSta 0 "Off (UnSeated)" 1 "On (Seated)" 2 "Not Used" 3 "Error Indicator" ;
VAL_ 1041 Warn_PrkngBrkSwSta 0 "Off" 1 "On" 2 "Not Used" 3 "Error Indicator" ;
VAL_ 1041 Warn_RrCtrStBltSwSta 0 "Unbelted" 1 "Belted" 2 "Not Used" 3 "Error Indicator" ;
VAL_ 1041 Warn_RrLftDrSwSta 0 "Close" 1 "Open" 2 "Not Used" 3 "Error Indicator" ;
VAL_ 1041 Warn_RrLftStBltSwSta 0 "Unbelted" 1 "Belted" 2 "Not Used" 3 "Error Indicator" ;
VAL_ 1041 Warn_RrRtDrSwSta 0 "Close" 1 "Open" 2 "Not Used" 3 "Error Indicator" ;
VAL_ 1041 Warn_RrRtStBltSwSta 0 "Unbelted" 1 "Belted" 2 "Not Used" 3 "Error Indicator" ;
VAL_ 1041 Warn_HoodSwMemorySta 0 "No event" 1 "hood_open_close" 2 "reserved" 3 "reserved" ;
VAL_ 1041 Warn_WshrFldSwSta 0 "Off" 1 "On" 2 "RESERVED" 3 "RESERVED" ;
VAL_ 1041 ICU_Haptic_OPT 0 "Default" 1 "No option(None Haptic Option)" 2 "Option" 3 "Invalid" ;
VAL_ 1093 SMK_Crc6Val 0 "0x0x0~0xFF:CRCValue" 255 "0x0x0~0xFF:CRCValue" ;
VAL_ 1093 SMK_AlvCnt6Val 0 "AlvCntValue" 1 "AlvCntValue" 2 "AlvCntValue" 3 "AlvCntValue" 4 "AlvCntValue" 5 "AlvCntValue" 6 "AlvCntValue" 7 "AlvCntValue" 8 "AlvCntValue" 9 "AlvCntValue" 10 "AlvCntValue" 11 "AlvCntValue" 12 "AlvCntValue" 13 "AlvCntValue" 14 "AlvCntValue" 15 "AlvCntValue" ;
VAL_ 1093 Lamp_HzrdBlnkngSta 0 "Off" 1 "Single Blinking" 2 "Double Blinking" 3 "Reserved" 4 "Reserved" 5 "Reseved" 6 "Not Used" 7 "Error Indicator" ;
VAL_ 1093 RSPA_LearntSta 0 "Non-RSPA Learnt" 1 "RSPA Learnt" 2 "Reserved" 3 "Error Indicator" ;
VAL_ 1093 Lamp_SmrtWlcmLtOnReq 0 "Off" 1 "On" 2 "Not Used" 3 "Error Indicator" ;
VAL_ 1093 Fob_BattStaInfo 0 "Normal or No Information" 1 "Recent used FOB is in discharge warning voltage level" 2 "Not Used" 3 "Error Indicator" ;
VAL_ 1093 Fob_FoundDrvWlcmArea 0 "Default" 1 "Fob Found(Drv)" 2 "Not Used" 3 "Error Indicator" ;
VAL_ 1093 Fob_FoundAsstWlcmArea 0 "Default" 1 "Fob Found(Ast)" 2 "Not Used" 3 "Error Indicator" ;
VAL_ 1093 Fob_FoundExtrnlArea 0 "Default" 1 "Can't recognize" 2 "Fob recognized" 3 "Search in progress" ;
VAL_ 1093 Fob_FoundIntArea 0 "Default" 1 "Can't recognize" 2 "Fob recognized" 3 "Search in progress" ;
VAL_ 1093 Fob_LearntSta 0 "Learnt" 1 "Virgin" 2 "Not Used" 3 "Error Indicator" ;
VAL_ 1093 RSPA_RFSigErrSta 0 "Default" 1 "Signal Invalid" 2 "In Progress" 3 "Error Indicator" ;
VAL_ 1093 RSPA_CanErrSta 0 "Default" 1 "RSPA CAN Error" 2 "Not Used" 3 "Error Indicator" ;
VAL_ 1093 LFAnt_FltSta 0 "Normal" 1 "Fault" 2 "Not Used" 3 "Error Indicator" ;
VAL_ 1093 LFAnt_SrchSta 0 "Off" 1 "On (LF Searching)" 2 "Not Used" 3 "Error Indicator" ;
VAL_ 1093 RSPA_ModSta_SMK 0 "RSPA Off" 1 "RSPA On" 2 "Reserved" 3 "Reserved" 4 "Reserved" 5 "Reseved" 6 "Not Used" 7 "Error Indicator" ;
VAL_ 1093 RSPA_FobBattSta 0 "Normal" 1 "Low Battery" 2 "Reserved" 3 "Reserved" 4 "Reserved" 5 "Reseved" 6 "Not Used" 7 "Error Indicator" ;
VAL_ 1093 Fob_BtnReleasedSta 0 "Default" 1 "Butten Released" 2 "Not used" 3 "Error Indicator" ;
VAL_ 1093 USM_SmrtTrnkTlgtModSta 0 "Default Value" 1 "HandsFree Off" 2 "HandsFree On" 3 "Reserved" 4 "Invalid" 5 "Reserved" 6 "Not Used" 7 "Error Indicator" ;
VAL_ 1093 USM_WALModSta 0 "Default" 1 "WAL Off" 2 "WAL On" 3 "Invalid" 4 "Reserved" 5 "Reseved" 6 "Not Used" 7 "Error Indicator" ;
VAL_ 1093 Fob_FoundWlcmArea 0 "Default (Off)" 1 "Fob Found" 2 "Not Used" 3 "Error Indicator" ;
VAL_ 830 USM_CmdWPC2Sta 0 "Default" 1 "Off(Disable)" 2 "On(Enable)" 3 "Invalid" ;
VAL_ 830 WPC2_OptSta 0 "Default" 1 "Apply" 2 "RESERVED" 3 "Invalid" ;
VAL_ 830 WPC2_SWVerMajor1 0 "0x0x0~0x7F:ASCII Code Value (HEX)" 127 "0x0x0~0x7F:ASCII Code Value (HEX)" ;
VAL_ 830 WPC2_PhnLftWrngSta 0 "Off" 1 "Cellphone on the pad" 2 "Charging" 3 "Charging complete" 4 "Cellphone reminder" 5 "Error" 6 "Reserved" 7 "Invalid" ;
VAL_ 830 WPC2_SWVerMinor1 0 "0x0x0~0x7F:ASCII Code Value (HEX)" 127 "0x0x0~0x7F:ASCII Code Value (HEX)" ;
VAL_ 830 WPC2_SWVerMinor2 0 "0x0x0~0x7F:ASCII Code Value (HEX)" 127 "0x0x0~0x7F:ASCII Code Value (HEX)" ;
VAL_ 830 WPC2_IndSyncVal 0 "default" 1 "off" 2 "1st sync" 3 "2nd sync" 4 "3rd sync" 5 "error off" 6 "error on" 7 "reserved" ;
VAL_ 1099 USM_CmdWPCSta 0 "Default" 1 "Off(Disable)" 2 "On(Enable)" 3 "Invalid" ;
VAL_ 1099 WPC_SWVerMajor1 0 "0x0x0~0x7F:ASCII Code Value (HEX)" 127 "0x0x0~0x7F:ASCII Code Value (HEX)" ;
VAL_ 1099 WPC_PhnLftWrngSta 0 "Off" 1 "Cellphone on the pad" 2 "Charging" 3 "Charging complete" 4 "Cellphone reminder" 5 "Error" 6 "Reserved" 7 "Invalid" ;
VAL_ 1099 WPC_SWVerMinor1 0 "0x0x0~0x7F:ASCII Code Value (HEX)" 127 "0x0x0~0x7F:ASCII Code Value (HEX)" ;
VAL_ 1099 WPC_SWVerMinor2 0 "0x0x0~0x7F:ASCII Code Value (HEX)" 127 "0x0x0~0x7F:ASCII Code Value (HEX)" ;
VAL_ 1099 WPC_IndSyncVal 0 "default" 1 "off" 2 "1st sync" 3 "2nd sync" 4 "3rd sync" 5 "error off" 6 "error on" 7 "reserved" ;
VAL_ 1099 USM_CmdWPCIndSta 0 "Default" 1 "Type 1 (Animation Off)" 2 "Type 2 (Animation On)" 3 "RESERVED" 4 "RESERVED" 5 "RESERVED" 6 "RESERVED" 7 "Invalid" ;
